// *************************************************************************** *
// *                                                                           *
// *                      Mentor Graphics Corporation                          *
// *                          All rights reserved                              *
// *                                                                           *
// *************************************************************************** *
// *                                                                           *
// * Description:         CANDB File                                           *
// * Generated at:        2025-06-23 15:14                                     *
// * System:              PP                                                   *
// * Variant:             DMH                                                  *
// * Network:             PTCANFD                                              *
// *                                                                           *
// *************************************************************************** *
// *                                                                           *
// *             THIS CONFIGURATION MIGHT CONTAIN SOME ERRORS                  *
// *              IF THE INPUT MODEL WAS NOT PROPERLY FORMED!                  *
// *                    Do Not Use this File directly!                         *
// *                                                                           *
// *************************************************************************** *
VERSION "PTCANFD"

NS_ :

BS_ :

BU_ :  BMS CCU PEU PICU TC TESTER VIU0

BO_ 287 ABM_State_VV01 : 20 VIU0
 SG_ ABM_CrashTyp : 127|5@0+ (1,0) [0|31] "" BMS,PEU,PICU,TC
 SG_ ABM_IMU_LateralAcceleration : 85|14@0+ (0.01,-49.05) [-49.05|114.78000000000002] "m/s2" TC
 SG_ ABM_IMU_LateralAccValid : 118|1@0+ (1,0) [0|1] "" TC
 SG_ ABM_IMU_LongAcceleration : 69|14@0+ (0.01,-49.05) [-49.05|114.78000000000002] "m/s2" TC
 SG_ ABM_IMU_LongAccelerationValid : 119|1@0+ (1,0) [0|1] "" TC
 SG_ ABM_IMU_Rollrate : 47|16@0+ (0.01,-300.0) [-300.0|355.35] "degree/s" TESTER
 SG_ ABM_IMU_RollrateSigVld : 33|1@0+ (1,0) [0|1] "" TESTER
 SG_ ABM_IMU_VertA : 31|14@0+ (0.01,-49.05) [-49.05|114.78000000000002] "m/s2" TESTER
 SG_ ABM_IMU_VertASigVld : 32|1@0+ (1,0) [0|1] "" TESTER
 SG_ ABM_IMU_YawRate : 103|16@0+ (0.01,-300.0) [-300.0|355.35] "degree/s" TESTER
 SG_ ABM_IMU_YawRateValid : 117|1@0+ (1,0) [0|1] "" TESTER
 SG_ ABM_IMU_YrsCalibStatus : 115|1@0+ (1,0) [0|1] "" TESTER
 SG_ ABM_State_Checksum : 7|16@0+ (1.0,0.0) [0.0|65535.0] "" PEU,PICU
 SG_ ABM_State_RollingCounter : 23|8@0+ (1.0,0.0) [0.0|255.0] "" PEU,PICU
 SG_ ABM_WarningLampStatus : 113|2@0+ (1,0) [0|3] "" PICU

BO_ 810 ADS_State : 32 VIU0
 SG_ ADS_CalSt : 110|5@0+ (1,0) [0|31] "" Vector_XXX
 SG_ ADS_FctSts : 37|1@0+ (1,0) [0|1] "" Vector_XXX
 SG_ ADS_FlowReq : 29|4@0+ (1,0) [0|15] "" PICU,TESTER
 SG_ ADS_ForcedHiBeamCtrl : 45|2@0+ (1,0) [0|3] "" Vector_XXX
 SG_ ADS_HVCtrlReq : 73|1@0+ (1,0) [0|1] "" Vector_XXX
 SG_ ADS_HzrdLampReq : 33|2@0+ (1,0) [0|3] "" Vector_XXX
 SG_ ADS_MdcCrtSts : 76|3@0+ (1,0) [0|7] "" Vector_XXX
 SG_ ADS_PwrOnOffReq : 79|3@0+ (1,0) [0|7] "" Vector_XXX
 SG_ ADS_RcwWarningReq : 47|2@0+ (1,0) [0|3] "" Vector_XXX
 SG_ ADS_RDAHzrdLampCtrl : 43|2@0+ (1,0) [0|3] "" Vector_XXX
 SG_ ADS_SilentCoolgMod : 199|2@0+ (1,0) [0|3] "" PICU,TESTER
 SG_ ADS_State_Checksum : 7|16@0+ (1.0,0.0) [0.0|65535.0] "" TESTER
 SG_ ADS_State_RollingCounter : 23|8@0+ (1.0,0.0) [0.0|255.0] "" TESTER
 SG_ ADS_SuspensionStatus : 24|3@0+ (1,0) [0|7] "" Vector_XXX
 SG_ ADS_ThmPostRun : 31|2@0+ (1,0) [0|3] "" PICU,TESTER
 SG_ ADS_TurnLampReq : 35|2@0+ (1,0) [0|3] "" Vector_XXX
 SG_ MDC_FuncReq_SentryModDetec : 118|1@0+ (1,0) [0|1] "" PICU
 SG_ MDC_FuncReq_SentryModWarn : 117|1@0+ (1,0) [0|1] "" Vector_XXX
 SG_ MDC_PrivacyModeSts : 127|2@0+ (1,0) [0|3] "" Vector_XXX

BO_ 1415 BMS_CellEquSt : 32 BMS
 SG_ BMS_BattEquilnSts : 0|1@0+ (1,0) [0|1] "" TESTER
 SG_ BMS_CellEquilnSts1 : 1|1@0+ (1,0) [0|1] "" TESTER
 SG_ BMS_CellEquilnSts10 : 10|1@0+ (1,0) [0|1] "" TESTER
 SG_ BMS_CellEquilnSts100 : 100|1@0+ (1,0) [0|1] "" TESTER
 SG_ BMS_CellEquilnSts101 : 101|1@0+ (1,0) [0|1] "" TESTER
 SG_ BMS_CellEquilnSts102 : 102|1@0+ (1,0) [0|1] "" TESTER
 SG_ BMS_CellEquilnSts103 : 103|1@0+ (1,0) [0|1] "" TESTER
 SG_ BMS_CellEquilnSts104 : 104|1@0+ (1,0) [0|1] "" TESTER
 SG_ BMS_CellEquilnSts105 : 105|1@0+ (1,0) [0|1] "" TESTER
 SG_ BMS_CellEquilnSts106 : 106|1@0+ (1,0) [0|1] "" TESTER
 SG_ BMS_CellEquilnSts107 : 107|1@0+ (1,0) [0|1] "" TESTER
 SG_ BMS_CellEquilnSts108 : 108|1@0+ (1,0) [0|1] "" TESTER
 SG_ BMS_CellEquilnSts109 : 109|1@0+ (1,0) [0|1] "" TESTER
 SG_ BMS_CellEquilnSts11 : 11|1@0+ (1,0) [0|1] "" TESTER
 SG_ BMS_CellEquilnSts110 : 110|1@0+ (1,0) [0|1] "" TESTER
 SG_ BMS_CellEquilnSts111 : 111|1@0+ (1,0) [0|1] "" TESTER
 SG_ BMS_CellEquilnSts112 : 112|1@0+ (1,0) [0|1] "" TESTER
 SG_ BMS_CellEquilnSts113 : 113|1@0+ (1,0) [0|1] "" TESTER
 SG_ BMS_CellEquilnSts114 : 114|1@0+ (1,0) [0|1] "" TESTER
 SG_ BMS_CellEquilnSts115 : 115|1@0+ (1,0) [0|1] "" TESTER
 SG_ BMS_CellEquilnSts116 : 116|1@0+ (1,0) [0|1] "" TESTER
 SG_ BMS_CellEquilnSts117 : 117|1@0+ (1,0) [0|1] "" TESTER
 SG_ BMS_CellEquilnSts118 : 118|1@0+ (1,0) [0|1] "" TESTER
 SG_ BMS_CellEquilnSts119 : 119|1@0+ (1,0) [0|1] "" TESTER
 SG_ BMS_CellEquilnSts12 : 12|1@0+ (1,0) [0|1] "" TESTER
 SG_ BMS_CellEquilnSts120 : 120|1@0+ (1,0) [0|1] "" TESTER
 SG_ BMS_CellEquilnSts121 : 121|1@0+ (1,0) [0|1] "" TESTER
 SG_ BMS_CellEquilnSts122 : 122|1@0+ (1,0) [0|1] "" TESTER
 SG_ BMS_CellEquilnSts123 : 123|1@0+ (1,0) [0|1] "" TESTER
 SG_ BMS_CellEquilnSts124 : 124|1@0+ (1,0) [0|1] "" TESTER
 SG_ BMS_CellEquilnSts125 : 125|1@0+ (1,0) [0|1] "" TESTER
 SG_ BMS_CellEquilnSts126 : 126|1@0+ (1,0) [0|1] "" TESTER
 SG_ BMS_CellEquilnSts127 : 127|1@0+ (1,0) [0|1] "" TESTER
 SG_ BMS_CellEquilnSts128 : 128|1@0+ (1,0) [0|1] "" TESTER
 SG_ BMS_CellEquilnSts129 : 129|1@0+ (1,0) [0|1] "" TESTER
 SG_ BMS_CellEquilnSts13 : 13|1@0+ (1,0) [0|1] "" TESTER
 SG_ BMS_CellEquilnSts130 : 130|1@0+ (1,0) [0|1] "" TESTER
 SG_ BMS_CellEquilnSts131 : 131|1@0+ (1,0) [0|1] "" TESTER
 SG_ BMS_CellEquilnSts132 : 132|1@0+ (1,0) [0|1] "" TESTER
 SG_ BMS_CellEquilnSts133 : 133|1@0+ (1,0) [0|1] "" TESTER
 SG_ BMS_CellEquilnSts134 : 134|1@0+ (1,0) [0|1] "" TESTER
 SG_ BMS_CellEquilnSts135 : 135|1@0+ (1,0) [0|1] "" TESTER
 SG_ BMS_CellEquilnSts136 : 136|1@0+ (1,0) [0|1] "" TESTER
 SG_ BMS_CellEquilnSts137 : 137|1@0+ (1,0) [0|1] "" TESTER
 SG_ BMS_CellEquilnSts138 : 138|1@0+ (1,0) [0|1] "" TESTER
 SG_ BMS_CellEquilnSts139 : 139|1@0+ (1,0) [0|1] "" TESTER
 SG_ BMS_CellEquilnSts14 : 14|1@0+ (1,0) [0|1] "" TESTER
 SG_ BMS_CellEquilnSts140 : 140|1@0+ (1,0) [0|1] "" TESTER
 SG_ BMS_CellEquilnSts141 : 141|1@0+ (1,0) [0|1] "" TESTER
 SG_ BMS_CellEquilnSts142 : 142|1@0+ (1,0) [0|1] "" TESTER
 SG_ BMS_CellEquilnSts143 : 143|1@0+ (1,0) [0|1] "" TESTER
 SG_ BMS_CellEquilnSts144 : 144|1@0+ (1,0) [0|1] "" TESTER
 SG_ BMS_CellEquilnSts145 : 145|1@0+ (1,0) [0|1] "" TESTER
 SG_ BMS_CellEquilnSts146 : 146|1@0+ (1,0) [0|1] "" TESTER
 SG_ BMS_CellEquilnSts147 : 147|1@0+ (1,0) [0|1] "" TESTER
 SG_ BMS_CellEquilnSts148 : 148|1@0+ (1,0) [0|1] "" TESTER
 SG_ BMS_CellEquilnSts149 : 149|1@0+ (1,0) [0|1] "" TESTER
 SG_ BMS_CellEquilnSts15 : 15|1@0+ (1,0) [0|1] "" TESTER
 SG_ BMS_CellEquilnSts150 : 150|1@0+ (1,0) [0|1] "" TESTER
 SG_ BMS_CellEquilnSts151 : 151|1@0+ (1,0) [0|1] "" TESTER
 SG_ BMS_CellEquilnSts152 : 152|1@0+ (1,0) [0|1] "" TESTER
 SG_ BMS_CellEquilnSts153 : 153|1@0+ (1,0) [0|1] "" TESTER
 SG_ BMS_CellEquilnSts154 : 154|1@0+ (1,0) [0|1] "" TESTER
 SG_ BMS_CellEquilnSts155 : 155|1@0+ (1,0) [0|1] "" TESTER
 SG_ BMS_CellEquilnSts156 : 156|1@0+ (1,0) [0|1] "" TESTER
 SG_ BMS_CellEquilnSts157 : 157|1@0+ (1,0) [0|1] "" TESTER
 SG_ BMS_CellEquilnSts158 : 158|1@0+ (1,0) [0|1] "" TESTER
 SG_ BMS_CellEquilnSts159 : 159|1@0+ (1,0) [0|1] "" TESTER
 SG_ BMS_CellEquilnSts16 : 16|1@0+ (1,0) [0|1] "" TESTER
 SG_ BMS_CellEquilnSts160 : 160|1@0+ (1,0) [0|1] "" TESTER
 SG_ BMS_CellEquilnSts161 : 161|1@0+ (1,0) [0|1] "" TESTER
 SG_ BMS_CellEquilnSts162 : 162|1@0+ (1,0) [0|1] "" TESTER
 SG_ BMS_CellEquilnSts163 : 163|1@0+ (1,0) [0|1] "" TESTER
 SG_ BMS_CellEquilnSts164 : 164|1@0+ (1,0) [0|1] "" TESTER
 SG_ BMS_CellEquilnSts165 : 165|1@0+ (1,0) [0|1] "" TESTER
 SG_ BMS_CellEquilnSts166 : 166|1@0+ (1,0) [0|1] "" TESTER
 SG_ BMS_CellEquilnSts167 : 167|1@0+ (1,0) [0|1] "" TESTER
 SG_ BMS_CellEquilnSts168 : 168|1@0+ (1,0) [0|1] "" TESTER
 SG_ BMS_CellEquilnSts169 : 169|1@0+ (1,0) [0|1] "" TESTER
 SG_ BMS_CellEquilnSts17 : 17|1@0+ (1,0) [0|1] "" TESTER
 SG_ BMS_CellEquilnSts170 : 170|1@0+ (1,0) [0|1] "" TESTER
 SG_ BMS_CellEquilnSts171 : 171|1@0+ (1,0) [0|1] "" TESTER
 SG_ BMS_CellEquilnSts172 : 172|1@0+ (1,0) [0|1] "" TESTER
 SG_ BMS_CellEquilnSts173 : 173|1@0+ (1,0) [0|1] "" TESTER
 SG_ BMS_CellEquilnSts174 : 174|1@0+ (1,0) [0|1] "" TESTER
 SG_ BMS_CellEquilnSts175 : 175|1@0+ (1,0) [0|1] "" TESTER
 SG_ BMS_CellEquilnSts176 : 176|1@0+ (1,0) [0|1] "" TESTER
 SG_ BMS_CellEquilnSts177 : 177|1@0+ (1,0) [0|1] "" TESTER
 SG_ BMS_CellEquilnSts178 : 178|1@0+ (1,0) [0|1] "" TESTER
 SG_ BMS_CellEquilnSts179 : 179|1@0+ (1,0) [0|1] "" TESTER
 SG_ BMS_CellEquilnSts18 : 18|1@0+ (1,0) [0|1] "" TESTER
 SG_ BMS_CellEquilnSts180 : 180|1@0+ (1,0) [0|1] "" TESTER
 SG_ BMS_CellEquilnSts181 : 181|1@0+ (1,0) [0|1] "" TESTER
 SG_ BMS_CellEquilnSts182 : 182|1@0+ (1,0) [0|1] "" TESTER
 SG_ BMS_CellEquilnSts183 : 183|1@0+ (1,0) [0|1] "" TESTER
 SG_ BMS_CellEquilnSts184 : 184|1@0+ (1,0) [0|1] "" TESTER
 SG_ BMS_CellEquilnSts185 : 185|1@0+ (1,0) [0|1] "" TESTER
 SG_ BMS_CellEquilnSts186 : 186|1@0+ (1,0) [0|1] "" TESTER
 SG_ BMS_CellEquilnSts187 : 187|1@0+ (1,0) [0|1] "" TESTER
 SG_ BMS_CellEquilnSts188 : 188|1@0+ (1,0) [0|1] "" TESTER
 SG_ BMS_CellEquilnSts189 : 189|1@0+ (1,0) [0|1] "" TESTER
 SG_ BMS_CellEquilnSts19 : 19|1@0+ (1,0) [0|1] "" TESTER
 SG_ BMS_CellEquilnSts190 : 190|1@0+ (1,0) [0|1] "" TESTER
 SG_ BMS_CellEquilnSts191 : 191|1@0+ (1,0) [0|1] "" TESTER
 SG_ BMS_CellEquilnSts192 : 192|1@0+ (1,0) [0|1] "" TESTER
 SG_ BMS_CellEquilnSts2 : 2|1@0+ (1,0) [0|1] "" TESTER
 SG_ BMS_CellEquilnSts20 : 20|1@0+ (1,0) [0|1] "" TESTER
 SG_ BMS_CellEquilnSts21 : 21|1@0+ (1,0) [0|1] "" TESTER
 SG_ BMS_CellEquilnSts22 : 22|1@0+ (1,0) [0|1] "" TESTER
 SG_ BMS_CellEquilnSts23 : 23|1@0+ (1,0) [0|1] "" TESTER
 SG_ BMS_CellEquilnSts24 : 24|1@0+ (1,0) [0|1] "" TESTER
 SG_ BMS_CellEquilnSts25 : 25|1@0+ (1,0) [0|1] "" TESTER
 SG_ BMS_CellEquilnSts26 : 26|1@0+ (1,0) [0|1] "" TESTER
 SG_ BMS_CellEquilnSts27 : 27|1@0+ (1,0) [0|1] "" TESTER
 SG_ BMS_CellEquilnSts28 : 28|1@0+ (1,0) [0|1] "" TESTER
 SG_ BMS_CellEquilnSts29 : 29|1@0+ (1,0) [0|1] "" TESTER
 SG_ BMS_CellEquilnSts3 : 3|1@0+ (1,0) [0|1] "" TESTER
 SG_ BMS_CellEquilnSts30 : 30|1@0+ (1,0) [0|1] "" TESTER
 SG_ BMS_CellEquilnSts31 : 31|1@0+ (1,0) [0|1] "" TESTER
 SG_ BMS_CellEquilnSts32 : 32|1@0+ (1,0) [0|1] "" TESTER
 SG_ BMS_CellEquilnSts33 : 33|1@0+ (1,0) [0|1] "" TESTER
 SG_ BMS_CellEquilnSts34 : 34|1@0+ (1,0) [0|1] "" TESTER
 SG_ BMS_CellEquilnSts35 : 35|1@0+ (1,0) [0|1] "" TESTER
 SG_ BMS_CellEquilnSts36 : 36|1@0+ (1,0) [0|1] "" TESTER
 SG_ BMS_CellEquilnSts37 : 37|1@0+ (1,0) [0|1] "" TESTER
 SG_ BMS_CellEquilnSts38 : 38|1@0+ (1,0) [0|1] "" TESTER
 SG_ BMS_CellEquilnSts39 : 39|1@0+ (1,0) [0|1] "" TESTER
 SG_ BMS_CellEquilnSts4 : 4|1@0+ (1,0) [0|1] "" TESTER
 SG_ BMS_CellEquilnSts40 : 40|1@0+ (1,0) [0|1] "" TESTER
 SG_ BMS_CellEquilnSts41 : 41|1@0+ (1,0) [0|1] "" TESTER
 SG_ BMS_CellEquilnSts42 : 42|1@0+ (1,0) [0|1] "" TESTER
 SG_ BMS_CellEquilnSts43 : 43|1@0+ (1,0) [0|1] "" TESTER
 SG_ BMS_CellEquilnSts44 : 44|1@0+ (1,0) [0|1] "" TESTER
 SG_ BMS_CellEquilnSts45 : 45|1@0+ (1,0) [0|1] "" TESTER
 SG_ BMS_CellEquilnSts46 : 46|1@0+ (1,0) [0|1] "" TESTER
 SG_ BMS_CellEquilnSts47 : 47|1@0+ (1,0) [0|1] "" TESTER
 SG_ BMS_CellEquilnSts48 : 48|1@0+ (1,0) [0|1] "" TESTER
 SG_ BMS_CellEquilnSts49 : 49|1@0+ (1,0) [0|1] "" TESTER
 SG_ BMS_CellEquilnSts5 : 5|1@0+ (1,0) [0|1] "" TESTER
 SG_ BMS_CellEquilnSts50 : 50|1@0+ (1,0) [0|1] "" TESTER
 SG_ BMS_CellEquilnSts51 : 51|1@0+ (1,0) [0|1] "" TESTER
 SG_ BMS_CellEquilnSts52 : 52|1@0+ (1,0) [0|1] "" TESTER
 SG_ BMS_CellEquilnSts53 : 53|1@0+ (1,0) [0|1] "" TESTER
 SG_ BMS_CellEquilnSts54 : 54|1@0+ (1,0) [0|1] "" TESTER
 SG_ BMS_CellEquilnSts55 : 55|1@0+ (1,0) [0|1] "" TESTER
 SG_ BMS_CellEquilnSts56 : 56|1@0+ (1,0) [0|1] "" TESTER
 SG_ BMS_CellEquilnSts57 : 57|1@0+ (1,0) [0|1] "" TESTER
 SG_ BMS_CellEquilnSts58 : 58|1@0+ (1,0) [0|1] "" TESTER
 SG_ BMS_CellEquilnSts59 : 59|1@0+ (1,0) [0|1] "" TESTER
 SG_ BMS_CellEquilnSts6 : 6|1@0+ (1,0) [0|1] "" TESTER
 SG_ BMS_CellEquilnSts60 : 60|1@0+ (1,0) [0|1] "" TESTER
 SG_ BMS_CellEquilnSts61 : 61|1@0+ (1,0) [0|1] "" TESTER
 SG_ BMS_CellEquilnSts62 : 62|1@0+ (1,0) [0|1] "" TESTER
 SG_ BMS_CellEquilnSts63 : 63|1@0+ (1,0) [0|1] "" TESTER
 SG_ BMS_CellEquilnSts64 : 64|1@0+ (1,0) [0|1] "" TESTER
 SG_ BMS_CellEquilnSts65 : 65|1@0+ (1,0) [0|1] "" TESTER
 SG_ BMS_CellEquilnSts66 : 66|1@0+ (1,0) [0|1] "" TESTER
 SG_ BMS_CellEquilnSts67 : 67|1@0+ (1,0) [0|1] "" TESTER
 SG_ BMS_CellEquilnSts68 : 68|1@0+ (1,0) [0|1] "" TESTER
 SG_ BMS_CellEquilnSts69 : 69|1@0+ (1,0) [0|1] "" TESTER
 SG_ BMS_CellEquilnSts7 : 7|1@0+ (1,0) [0|1] "" TESTER
 SG_ BMS_CellEquilnSts70 : 70|1@0+ (1,0) [0|1] "" TESTER
 SG_ BMS_CellEquilnSts71 : 71|1@0+ (1,0) [0|1] "" TESTER
 SG_ BMS_CellEquilnSts72 : 72|1@0+ (1,0) [0|1] "" TESTER
 SG_ BMS_CellEquilnSts73 : 73|1@0+ (1,0) [0|1] "" TESTER
 SG_ BMS_CellEquilnSts74 : 74|1@0+ (1,0) [0|1] "" TESTER
 SG_ BMS_CellEquilnSts75 : 75|1@0+ (1,0) [0|1] "" TESTER
 SG_ BMS_CellEquilnSts76 : 76|1@0+ (1,0) [0|1] "" TESTER
 SG_ BMS_CellEquilnSts77 : 77|1@0+ (1,0) [0|1] "" TESTER
 SG_ BMS_CellEquilnSts78 : 78|1@0+ (1,0) [0|1] "" TESTER
 SG_ BMS_CellEquilnSts79 : 79|1@0+ (1,0) [0|1] "" TESTER
 SG_ BMS_CellEquilnSts8 : 8|1@0+ (1,0) [0|1] "" TESTER
 SG_ BMS_CellEquilnSts80 : 80|1@0+ (1,0) [0|1] "" TESTER
 SG_ BMS_CellEquilnSts81 : 81|1@0+ (1,0) [0|1] "" TESTER
 SG_ BMS_CellEquilnSts82 : 82|1@0+ (1,0) [0|1] "" TESTER
 SG_ BMS_CellEquilnSts83 : 83|1@0+ (1,0) [0|1] "" TESTER
 SG_ BMS_CellEquilnSts84 : 84|1@0+ (1,0) [0|1] "" TESTER
 SG_ BMS_CellEquilnSts85 : 85|1@0+ (1,0) [0|1] "" TESTER
 SG_ BMS_CellEquilnSts86 : 86|1@0+ (1,0) [0|1] "" TESTER
 SG_ BMS_CellEquilnSts87 : 87|1@0+ (1,0) [0|1] "" TESTER
 SG_ BMS_CellEquilnSts88 : 88|1@0+ (1,0) [0|1] "" TESTER
 SG_ BMS_CellEquilnSts89 : 89|1@0+ (1,0) [0|1] "" TESTER
 SG_ BMS_CellEquilnSts9 : 9|1@0+ (1,0) [0|1] "" TESTER
 SG_ BMS_CellEquilnSts90 : 90|1@0+ (1,0) [0|1] "" TESTER
 SG_ BMS_CellEquilnSts91 : 91|1@0+ (1,0) [0|1] "" TESTER
 SG_ BMS_CellEquilnSts92 : 92|1@0+ (1,0) [0|1] "" TESTER
 SG_ BMS_CellEquilnSts93 : 93|1@0+ (1,0) [0|1] "" TESTER
 SG_ BMS_CellEquilnSts94 : 94|1@0+ (1,0) [0|1] "" TESTER
 SG_ BMS_CellEquilnSts95 : 95|1@0+ (1,0) [0|1] "" TESTER
 SG_ BMS_CellEquilnSts96 : 96|1@0+ (1,0) [0|1] "" TESTER
 SG_ BMS_CellEquilnSts97 : 97|1@0+ (1,0) [0|1] "" TESTER
 SG_ BMS_CellEquilnSts98 : 98|1@0+ (1,0) [0|1] "" TESTER
 SG_ BMS_CellEquilnSts99 : 99|1@0+ (1,0) [0|1] "" TESTER
 SG_ BMS_CellEquStSync : 251|4@0+ (1.0,0.0) [0.0|14.0] "" TESTER
 SG_ BMS_EquilnFltCellIdx : 247|8@0+ (1.0,0.0) [0.0|255.0] "" TESTER

BO_ 389 BMS_ChargeInfo : 32 BMS
 SG_ BMS_ACChrgSt : 91|4@0+ (1,0) [0|15] "" PICU,VIU0
 SG_ BMS_ACOutDischrgSt : 94|3@0+ (1,0) [0|7] "" PICU,VIU0
 SG_ BMS_ActvHvOffReq : 127|8@0+ (1.0,0.0) [0.0|255.0] "" VIU0
 SG_ BMS_ActvHvOnReq : 71|8@0+ (1,0) [0|255] "" CCU,PICU,TC,VIU0
 SG_ BMS_BattChrgNeeded : 87|1@0+ (1,0) [0|1] "" VIU0
 SG_ BMS_Cc2SngR : 100|13@0+ (1.0,0.0) [0.0|8191.0] "Ω" TESTER
 SG_ BMS_ChargeInfo_Checksum : 7|16@0+ (1.0,0.0) [0.0|65535.0] "" CCU,VIU0
 SG_ BMS_ChargeInfo_Counter : 23|8@0+ (1.0,0.0) [0.0|255.0] "" CCU,VIU0
 SG_ BMS_ChrgASigSt : 27|1@0+ (1,0) [0|1] "" TESTER
 SG_ BMS_ChrgASigVolt : 39|9@0+ (0.1,0.0) [0.0|36.0] "V" TESTER
 SG_ BMS_ChrgEndNum : 119|8@0+ (1.0,0.0) [0.0|255.0] "" VIU0
 SG_ BMS_ChrgForm : 79|4@0+ (1,0) [0|15] "" TESTER
 SG_ BMS_ChrgLockReq : 245|2@0+ (1,0) [0|3] "" VIU0
 SG_ BMS_ChrgRemainTime : 52|13@0+ (1.0,0.0) [0.0|8191.0] "min" VIU0
 SG_ BMS_ChrgTiEstimn : 220|13@0+ (1.0,0.0) [0.0|8189.0] "min" VIU0
 SG_ BMS_ChrgTrgtSOC : 46|7@0+ (1.0,0.0) [0.0|100.0] "%" VIU0
 SG_ BMS_DCChrgConnectSt : 26|3@0+ (1,0) [0|7] "" CCU,PICU,TC,VIU0
 SG_ BMS_DCChrgSt : 83|4@0+ (1,0) [0|15] "" PICU,VIU0
 SG_ BMS_DCOutDischrgSt : 86|3@0+ (1,0) [0|7] "" TESTER,VIU0
 SG_ BMS_DCPileInsuTestVoltMax : 215|10@0+ (1.0,0.0) [0.0|1000.0] "V" VIU0
 SG_ BMS_DeratingCoeff : 239|10@0+ (0.1,0.0) [0.0|100.0] "%" TESTER
 SG_ BMS_DrtngChg : 181|3@0+ (1,0) [0|7] "" VIU0
 SG_ BMS_FCNegRelaySt : 31|2@0+ (1,0) [0|3] "" VIU0
 SG_ BMS_FCPosRelaySt : 29|2@0+ (1,0) [0|3] "" VIU0
 SG_ BMS_HVONReq : 54|2@0+ (1,0) [0|3] "" PICU,VIU0
 SG_ BMS_LinkEnergizeSt : 103|3@0+ (1,0) [0|7] "" VIU0
 SG_ BMS_OBCCurrtReq : 155|12@0+ (0.1,0.0) [0.0|409.5] "A" CCU,VIU0
 SG_ BMS_OBCInvACVoltReq : 176|9@0+ (1.0,0.0) [0.0|511.0] "V" CCU
 SG_ BMS_OBCInvMaxPermPwr : 175|10@0+ (0.01,0.0) [0.0|10.23] "kw" CCU
 SG_ BMS_OBCVoltReq : 151|10@0+ (1.0,0.0) [0.0|1000.0] "V" CCU,VIU0
 SG_ BMS_OBCWorkModReq : 142|3@0+ (1,0) [0|7] "" CCU
 SG_ BMS_PilePwrSt : 139|3@0+ (1,0) [0|7] "" VIU0
 SG_ BMS_S1Req : 156|1@0+ (1,0) [0|1] "" TESTER
 SG_ BMS_S2SwtCtrl : 243|2@0+ (1,0) [0|3] "" VIU0
 SG_ BMS_S4Req : 157|1@0+ (1,0) [0|1] "" TESTER

BO_ 795 BMS_DFX_1 : 32 BMS
 SG_ BMS_AFEPreFail : 213|1@0+ (1,0) [0|1] "" VIU0
 SG_ BMS_AFEPreFailNum : 212|5@0+ (1.0,0.0) [0.0|31.0] "" VIU0
 SG_ BMS_ChrgCurrtLkUp : 167|14@0+ (0.1,-1000.0) [-1000.0|0.0] "A" VIU0
 SG_ BMS_CrashPWMDuty : 190|7@0+ (1.0,0.0) [0.0|100.0] "%" VIU0
 SG_ BMS_EquPreFail : 221|1@0+ (1,0) [0|1] "" VIU0
 SG_ BMS_EquPreFailNum : 220|5@0+ (1.0,0.0) [0.0|31.0] "" VIU0
 SG_ BMS_HighTempFaultNTCIdx : 237|6@0+ (1.0,0.0) [0.0|61.0] "" VIU0
 SG_ BMS_HighTempFaultNTCNum : 229|6@0+ (1.0,0.0) [0.0|61.0] "" VIU0
 SG_ BMS_HVILFCVh : 68|13@0+ (1.0,0.0) [0.0|5000.0] "mV" VIU0
 SG_ BMS_HVILFCVl : 84|13@0+ (1.0,0.0) [0.0|5000.0] "mV" VIU0
 SG_ BMS_HVILPWRTrainFVh : 100|13@0+ (1.0,0.0) [0.0|5000.0] "mV" VIU0
 SG_ BMS_HVILPWRTrainFVl : 116|13@0+ (1.0,0.0) [0.0|5000.0] "mV" VIU0
 SG_ BMS_HVILPWRTrainRVh : 132|13@0+ (1.0,0.0) [0.0|5000.0] "mV" VIU0
 SG_ BMS_HVILPWRTrainRVl : 148|13@0+ (1.0,0.0) [0.0|5000.0] "mV" VIU0
 SG_ BMS_InsulationNeg : 23|16@0+ (1.0,0.0) [0.0|60000.0] " kΩ" VIU0
 SG_ BMS_InsulationPos : 7|16@0+ (1.0,0.0) [0.0|60000.0] " kΩ" VIU0
 SG_ BMS_InsulationVoltNeg : 52|13@0+ (1.0,0.0) [0.0|5000.0] "V" VIU0
 SG_ BMS_InsulationVoltPos : 36|13@0+ (1.0,0.0) [0.0|5000.0] "V" VIU0
 SG_ BMS_LowTempFaultNTCIdx : 253|6@0+ (1.0,0.0) [0.0|61.0] "" VIU0
 SG_ BMS_LowTempFaultNTCNum : 245|6@0+ (1.0,0.0) [0.0|61.0] "" VIU0
 SG_ BMS_PreChgScssTime : 169|10@0+ (1.0,0.0) [0.0|1000.0] "ms" VIU0
 SG_ BMS_TSmplngLnPreFail : 206|1@0+ (1,0) [0|1] "" VIU0
 SG_ BMS_TSmplngLnPreFailNum : 205|6@0+ (1.0,0.0) [0.0|63.0] "" VIU0
 SG_ BMS_VSmplngLnPreFail : 207|1@0+ (1,0) [0|1] "" VIU0
 SG_ BMS_VSmplngLnPreFailNum : 199|8@0+ (1.0,0.0) [0.0|255.0] "" VIU0

BO_ 797 BMS_DFX_2 : 32 BMS
 SG_ BMS_CellMaxVolt : 20|13@0+ (1.0,0.0) [0.0|5000.0] "mV" VIU0
 SG_ BMS_CellMinVolt : 36|13@0+ (1.0,0.0) [0.0|5000.0] "mV" VIU0
 SG_ BMS_CellVoltSum : 53|14@0+ (0.1,0.0) [0.0|1000.0] "" VIU0
 SG_ BMS_MaxVoltCellNum : 7|8@0+ (1.0,0.0) [0.0|255.0] "" VIU0
 SG_ BMS_MinVoltCellNum : 15|8@0+ (1.0,0.0) [0.0|255.0] "" VIU0
 SG_ BMS_ModuleVolt1 : 71|10@0+ (0.1,0.0) [0.0|80.0] "V" VIU0
 SG_ BMS_ModuleVolt10 : 169|10@0+ (0.1,0.0) [0.0|80.0] "V" VIU0
 SG_ BMS_ModuleVolt11 : 191|10@0+ (0.1,0.0) [0.0|80.0] "V" VIU0
 SG_ BMS_ModuleVolt12 : 193|10@0+ (0.1,0.0) [0.0|80.0] "V" VIU0
 SG_ BMS_ModuleVolt13 : 215|10@0+ (0.1,0.0) [0.0|80.0] "V" VIU0
 SG_ BMS_ModuleVolt14 : 217|10@0+ (0.1,0.0) [0.0|80.0] "V" VIU0
 SG_ BMS_ModuleVolt2 : 73|10@0+ (0.1,0.0) [0.0|80.0] "V" VIU0
 SG_ BMS_ModuleVolt3 : 95|10@0+ (0.1,0.0) [0.0|80.0] "V" VIU0
 SG_ BMS_ModuleVolt4 : 97|10@0+ (0.1,0.0) [0.0|80.0] "V" VIU0
 SG_ BMS_ModuleVolt5 : 119|10@0+ (0.1,0.0) [0.0|80.0] "V" VIU0
 SG_ BMS_ModuleVolt6 : 121|10@0+ (0.1,0.0) [0.0|80.0] "V" VIU0
 SG_ BMS_ModuleVolt7 : 143|10@0+ (0.1,0.0) [0.0|80.0] "V" VIU0
 SG_ BMS_ModuleVolt8 : 145|10@0+ (0.1,0.0) [0.0|80.0] "V" VIU0
 SG_ BMS_ModuleVolt9 : 167|10@0+ (0.1,0.0) [0.0|80.0] "V" VIU0
 SG_ BMS_PrimaryCurrtSnsrTemp : 239|8@0+ (1.0,-50.0) [-50.0|205.0] "℃" TESTER

BO_ 1299 BMS_DFX_3 : 32 BMS
 SG_ BMS_EquTemp1 : 7|8@0+ (1.0,-40.0) [-40.0|125.0] "℃" VIU0
 SG_ BMS_EquTemp10 : 79|8@0+ (1.0,-40.0) [-40.0|125.0] "℃" VIU0
 SG_ BMS_EquTemp11 : 87|8@0+ (1.0,-40.0) [-40.0|125.0] "℃" VIU0
 SG_ BMS_EquTemp12 : 95|8@0+ (1.0,-40.0) [-40.0|125.0] "℃" VIU0
 SG_ BMS_EquTemp13 : 103|8@0+ (1.0,-40.0) [-40.0|125.0] "℃" VIU0
 SG_ BMS_EquTemp14 : 111|8@0+ (1.0,-40.0) [-40.0|125.0] "℃" VIU0
 SG_ BMS_EquTemp2 : 15|8@0+ (1.0,-40.0) [-40.0|125.0] "℃" VIU0
 SG_ BMS_EquTemp3 : 23|8@0+ (1.0,-40.0) [-40.0|125.0] "℃" VIU0
 SG_ BMS_EquTemp4 : 31|8@0+ (1.0,-40.0) [-40.0|125.0] "℃" VIU0
 SG_ BMS_EquTemp5 : 39|8@0+ (1.0,-40.0) [-40.0|125.0] "℃" VIU0
 SG_ BMS_EquTemp6 : 47|8@0+ (1.0,-40.0) [-40.0|125.0] "℃" VIU0
 SG_ BMS_EquTemp7 : 55|8@0+ (1.0,-40.0) [-40.0|125.0] "℃" VIU0
 SG_ BMS_EquTemp8 : 63|8@0+ (1.0,-40.0) [-40.0|125.0] "℃" VIU0
 SG_ BMS_EquTemp9 : 71|8@0+ (1.0,-40.0) [-40.0|125.0] "℃" VIU0
 SG_ BMS_MainNegBigLoadOpenCnt : 247|8@0+ (1.0,0.0) [0.0|255.0] "" VIU0
 SG_ BMS_MainNegLowLoadOpenCnt : 209|18@0+ (1.0,0.0) [0.0|262143.0] "" VIU0
 SG_ BMS_MainNegMidLoadOpenCnt : 239|8@0+ (1.0,0.0) [0.0|255.0] "" VIU0
 SG_ BMS_MainNegOpenCnt : 199|18@0+ (1.0,0.0) [0.0|262143.0] "" VIU0
 SG_ BMS_MainNegSuperLoadOpenCnt : 255|8@0+ (1.0,0.0) [0.0|255.0] "" VIU0
 SG_ BMS_MainPosBigLoadOpenCnt : 183|8@0+ (1.0,0.0) [0.0|255.0] "" VIU0
 SG_ BMS_MainPosLowLoadOpenCnt : 145|18@0+ (1.0,0.0) [0.0|262143.0] "" VIU0
 SG_ BMS_MainPosMidLoadOpenCnt : 175|8@0+ (1.0,0.0) [0.0|255.0] "" VIU0
 SG_ BMS_MainPosOpenCnt : 135|18@0+ (1.0,0.0) [0.0|262143.0] "" VIU0
 SG_ BMS_MainPosSuperLoadOpenCnt : 191|8@0+ (1.0,0.0) [0.0|255.0] "" VIU0

BO_ 786 BMS_ErrInfo : 32 BMS
 SG_ BMS_AirPressure : 87|16@0+ (0.1,0.0) [0.0|6553.3] "kPa" TESTER
 SG_ BMS_AirPressureRate : 103|8@0+ (0.1,0.0) [0.0|25.3] "kPa/s" TESTER
 SG_ BMS_BattSocUnderLamp : 29|1@0+ (1,0) [0|1] "" TESTER
 SG_ BMS_BattTempRate : 111|8@0+ (1.0,0.0) [0.0|253.0] "℃/3S" TESTER
 SG_ BMS_BattTLowLamp1 : 37|1@0+ (1,0) [0|1] "" TESTER
 SG_ BMS_BattTLowLamp2 : 38|1@0+ (1,0) [0|1] "" VIU0
 SG_ BMS_BattTOverLamp : 30|1@0+ (1,0) [0|1] "" PICU
 SG_ BMS_CalDataVers : 113|10@0+ (1.0,0.0) [0.0|1023.0] "" TESTER
 SG_ BMS_HVPwrDwnRsn : 119|6@0+ (1.0,0.0) [0.0|63.0] "" TESTER
 SG_ BMS_HVPwrOnFailRsn : 157|6@0+ (1.0,0.0) [0.0|63.0] "" TESTER
 SG_ BMS_InsulationProhibitRsn : 175|5@0+ (1.0,0.0) [0.0|31.0] "" TESTER
 SG_ BMS_MIL_Request : 39|1@0+ (1,0) [0|1] "" PICU,VIU0
 SG_ BMS_PackSOHActual : 151|10@0+ (0.1,0.0) [0.0|100.0] "%" TESTER
 SG_ BMS_PwrBattErrLamp : 31|1@0+ (1,0) [0|1] "" TESTER
 SG_ BMS_ResetRsn : 167|8@0+ (1.0,0.0) [0.0|255.0] "" TESTER
 SG_ BMS_SOCCalAlarm : 35|2@0+ (1,0) [0|3] "" VIU0
 SG_ BMS_TRWarnRsn : 28|5@0+ (1.0,0.0) [0.0|31.0] "" TESTER

BO_ 461 BMS_FastChgErr : 8 BMS
 SG_ BST_AchievedCellVoltage : 5|2@0+ (1,0) [0|3] "" TESTER
 SG_ BST_AchievedPackVoltage : 3|2@0+ (1,0) [0|3] "" TESTER
 SG_ BST_AchievedSOC : 1|2@0+ (1,0) [0|3] "" TESTER
 SG_ BST_BatteryTempHigh : 17|2@0+ (1,0) [0|3] "" TESTER
 SG_ BST_BMSComponentsFault : 13|2@0+ (1,0) [0|3] "" TESTER
 SG_ BST_ChargeConnetorFault : 15|2@0+ (1,0) [0|3] "" TESTER
 SG_ BST_ChargeTeminated : 7|2@0+ (1,0) [0|3] "" TESTER
 SG_ BST_HVContactorFault : 19|2@0+ (1,0) [0|3] "" TESTER
 SG_ BST_InsulationFault : 9|2@0+ (1,0) [0|3] "" TESTER
 SG_ BST_OtherFault : 23|2@0+ (1,0) [0|3] "" TESTER
 SG_ BST_OutputConectorTempHigh : 11|2@0+ (1,0) [0|3] "" TESTER
 SG_ BST_OverCurrentError : 25|2@0+ (1,0) [0|3] "" TESTER
 SG_ BST_Point2VoltageDetectFault : 21|2@0+ (1,0) [0|3] "" TESTER
 SG_ BST_VoltageError : 27|2@0+ (1,0) [0|3] "" TESTER
 SG_ CST_AchievedCondition : 33|2@0+ (1,0) [0|3] "" TESTER
 SG_ CST_BMSAbort : 39|2@0+ (1,0) [0|3] "" TESTER
 SG_ CST_ChargeConnetorFault : 43|2@0+ (1,0) [0|3] "" TESTER
 SG_ CST_ChargeInnerTempFault : 45|2@0+ (1,0) [0|3] "" TESTER
 SG_ CST_ChargeStopFault : 49|2@0+ (1,0) [0|3] "" TESTER
 SG_ CST_ChargeTempHighFault : 41|2@0+ (1,0) [0|3] "" TESTER
 SG_ CST_CurrentMismathError : 53|2@0+ (1,0) [0|3] "" TESTER
 SG_ CST_EnergyTransmitFault : 47|2@0+ (1,0) [0|3] "" TESTER
 SG_ CST_FaultAbort : 37|2@0+ (1,0) [0|3] "" TESTER
 SG_ CST_ManualAbort : 35|2@0+ (1,0) [0|3] "" TESTER
 SG_ CST_OtherFault : 51|2@0+ (1,0) [0|3] "" TESTER
 SG_ CST_VolateError : 55|2@0+ (1,0) [0|3] "" TESTER

BO_ 862 BMS_FastChgInfo : 48 BMS
 SG_ BCL_ChareMode : 263|8@0+ (1,0) [0|255] "" TESTER
 SG_ BCL_CurrentRequire : 247|16@0+ (0.1,-400.0) [-400.0|6153.5] "A" VIU0
 SG_ BCL_VoltageRequire : 231|16@0+ (0.1,0.0) [0.0|6553.5] "V" VIU0
 SG_ BEM_CCSTimeout : 329|2@0+ (1,0) [0|3] "" TESTER
 SG_ BEM_CRMTimeout00 : 321|2@0+ (1,0) [0|3] "" TESTER
 SG_ BEM_CRMTimeoutAA : 323|2@0+ (1,0) [0|3] "" TESTER
 SG_ BEM_CROTimeout : 327|2@0+ (1,0) [0|3] "" TESTER
 SG_ BEM_CSDTimeout : 333|2@0+ (1,0) [0|3] "" TESTER
 SG_ BEM_CSTTimeout : 331|2@0+ (1,0) [0|3] "" TESTER
 SG_ BEM_CTS_CMLTimeout : 325|2@0+ (1,0) [0|3] "" TESTER
 SG_ BEM_Other : 335|2@0+ (1,0) [0|3] "" TESTER
 SG_ BRM_BatteryChargeTimes : 127|24@0+ (1.0,0.0) [0.0|16777215.0] "" TESTER
 SG_ BRM_BatteryManufacture : 95|32@0+ (1.0,0.0) [0.0|4294967295.0] "" TESTER
 SG_ BRO_BMSChargeReady : 215|8@0+ (1,0) [0|255] "" TESTER
 SG_ CCS_ChargeAllowed : 313|2@0+ (1,0) [0|3] "" TESTER
 SG_ CCS_OutputCurent : 287|16@0+ (0.1,-400.0) [-400.0|6153.5] "A" TC,VIU0
 SG_ CCS_OutputVoltage : 271|16@0+ (0.1,0.0) [0.0|6553.5] "V" TC,VIU0
 SG_ CCS_TotalChargeTime : 303|16@0+ (1.0,0.0) [0.0|600.0] "min" TESTER
 SG_ CEM_BCLTimeout : 345|2@0+ (1,0) [0|3] "" TESTER
 SG_ CEM_BCPTimeout : 339|2@0+ (1,0) [0|3] "" TESTER
 SG_ CEM_BCSTimeout : 343|2@0+ (1,0) [0|3] "" TESTER
 SG_ CEM_BRMTimeout : 337|2@0+ (1,0) [0|3] "" TESTER
 SG_ CEM_BROTimeout : 341|2@0+ (1,0) [0|3] "" TESTER
 SG_ CEM_BSDTimeout : 349|2@0+ (1,0) [0|3] "" TESTER
 SG_ CEM_BSTTimeout : 347|2@0+ (1,0) [0|3] "" TESTER
 SG_ CEM_Other : 351|2@0+ (1,0) [0|3] "" TESTER
 SG_ CHM_ComVersion : 7|24@0+ (1.0,0.0) [0.0|16777215.0] "" TESTER
 SG_ CML_OutputCurentMax : 183|16@0+ (0.1,-400.0) [-400.0|6153.5] "A" TC,VIU0
 SG_ CML_OutputCurentMin : 199|16@0+ (0.1,-400.0) [-400.0|6153.5] "A" TESTER
 SG_ CML_OutputVoltageMax : 151|16@0+ (0.1,0.0) [0.0|6553.5] "V" TESTER
 SG_ CML_OutputVoltageMin : 167|16@0+ (0.1,0.0) [0.0|6553.5] "V" TESTER
 SG_ CRM_ChargeNo : 39|32@0+ (1.0,0.0) [0.0|4294967295.0] "" TESTER
 SG_ CRM_RecongnitionResult : 31|8@0+ (1.0,0.0) [0.0|255.0] "" TESTER
 SG_ CRM_RegionCode : 71|24@0+ (1.0,0.0) [0.0|16777215.0] "" TESTER
 SG_ CRO_ChargeReady : 223|8@0+ (1.0,0.0) [0.0|255.0] "" TESTER
 SG_ CSD_TotalChrgEnergy : 359|16@0+ (0.1,0.0) [0.0|1000.0] "kWh" TESTER

BO_ 1303 BMS_Fault : 32 BMS
 SG_ BMS_FaultNum1 : 23|12@0+ (1.0,0.0) [0.0|4095.0] "" VIU0
 SG_ BMS_FaultNum10 : 123|12@0+ (1.0,0.0) [0.0|4095.0] "" VIU0
 SG_ BMS_FaultNum11 : 143|12@0+ (1.0,0.0) [0.0|4095.0] "" VIU0
 SG_ BMS_FaultNum12 : 147|12@0+ (1.0,0.0) [0.0|4095.0] "" VIU0
 SG_ BMS_FaultNum13 : 167|12@0+ (1.0,0.0) [0.0|4095.0] "" VIU0
 SG_ BMS_FaultNum14 : 171|12@0+ (1.0,0.0) [0.0|4095.0] "" VIU0
 SG_ BMS_FaultNum15 : 191|12@0+ (1.0,0.0) [0.0|4095.0] "" VIU0
 SG_ BMS_FaultNum16 : 195|12@0+ (1.0,0.0) [0.0|4095.0] "" VIU0
 SG_ BMS_FaultNum17 : 215|12@0+ (1.0,0.0) [0.0|4095.0] "" VIU0
 SG_ BMS_FaultNum18 : 219|12@0+ (1.0,0.0) [0.0|4095.0] "" VIU0
 SG_ BMS_FaultNum19 : 239|12@0+ (1.0,0.0) [0.0|4095.0] "" VIU0
 SG_ BMS_FaultNum2 : 27|12@0+ (1.0,0.0) [0.0|4095.0] "" VIU0
 SG_ BMS_FaultNum20 : 243|12@0+ (1.0,0.0) [0.0|4095.0] "" VIU0
 SG_ BMS_FaultNum3 : 47|12@0+ (1.0,0.0) [0.0|4095.0] "" VIU0
 SG_ BMS_FaultNum4 : 51|12@0+ (1.0,0.0) [0.0|4095.0] "" VIU0
 SG_ BMS_FaultNum5 : 71|12@0+ (1.0,0.0) [0.0|4095.0] "" VIU0
 SG_ BMS_FaultNum6 : 75|12@0+ (1.0,0.0) [0.0|4095.0] "" VIU0
 SG_ BMS_FaultNum7 : 95|12@0+ (1.0,0.0) [0.0|4095.0] "" VIU0
 SG_ BMS_FaultNum8 : 99|12@0+ (1.0,0.0) [0.0|4095.0] "" VIU0
 SG_ BMS_FaultNum9 : 119|12@0+ (1.0,0.0) [0.0|4095.0] "" VIU0
 SG_ BMS_FrameIndex : 12|5@0+ (1.0,0.0) [0.0|31.0] "" VIU0
 SG_ BMS_SupplierNum : 15|3@0+ (1.0,0.0) [0.0|7.0] "" VIU0
 SG_ BMS_TotalFaultNum : 7|8@0+ (1.0,0.0) [0.0|255.0] "" VIU0

BO_ 1416 BMS_GBInfo : 32 BMS
 SG_ BMS_BattConstnceErrGb : 170|1@0+ (1,0) [0|1] "" VIU0
 SG_ BMS_BattIGb : 183|16@0+ (0.1,-1000.0) [-1000.0|5553.5] "A" VIU0
 SG_ BMS_BattMatchErrGb : 169|1@0+ (1,0) [0|1] "" VIU0
 SG_ BMS_BattNrTotGb : 223|8@0+ (1.0,0.0) [0.0|255.0] "" VIU0
 SG_ BMS_BattSocHiGb : 167|1@0+ (1,0) [0|1] "" VIU0
 SG_ BMS_BattSocJmpGb : 168|1@0+ (1,0) [0|1] "" VIU0
 SG_ BMS_BattSocLoGb : 164|1@0+ (1,0) [0|1] "" VIU0
 SG_ BMS_BattTOverGb : 161|1@0+ (1,0) [0|1] "" VIU0
 SG_ BMS_BattUGb : 199|16@0+ (0.1,0.0) [0.0|6553.5] "V" VIU0
 SG_ BMS_BattUMaxNrGb : 55|8@0+ (1.0,0.0) [0.0|255.0] "" VIU0
 SG_ BMS_BattUMinNrGb : 87|8@0+ (1.0,0.0) [0.0|255.0] "" VIU0
 SG_ BMS_BattUOverGb : 163|1@0+ (1,0) [0|1] "" VIU0
 SG_ BMS_BattUUnderGb : 162|1@0+ (1,0) [0|1] "" VIU0
 SG_ BMS_CellNrTotGb : 23|16@0+ (1.0,0.0) [0.0|65535.0] "" VIU0
 SG_ BMS_CellUMaxGb : 71|16@0+ (0.001,0.0) [0.0|65.535] "V" VIU0
 SG_ BMS_CellUMaxNrGb : 63|8@0+ (1.0,0.0) [0.0|255.0] "" VIU0
 SG_ BMS_CellUMinGb : 103|16@0+ (0.001,0.0) [0.0|65.535] "V" VIU0
 SG_ BMS_CellUMinNrGb : 95|8@0+ (1.0,0.0) [0.0|255.0] "" VIU0
 SG_ BMS_CellUOverGb : 166|1@0+ (1,0) [0|1] "" VIU0
 SG_ BMS_CellUUnderGb : 165|1@0+ (1,0) [0|1] "" VIU0
 SG_ BMS_ChrgOverGb : 172|1@0+ (1,0) [0|1] "" VIU0
 SG_ BMS_ChrgStGb : 226|3@0+ (1,0) [0|7] "" VIU0
 SG_ BMS_DeltaTOverGb : 160|1@0+ (1,0) [0|1] "" VIU0
 SG_ BMS_HvilStsGb : 171|1@0+ (1,0) [0|1] "" VIU0
 SG_ BMS_InsulationRGb : 7|16@0+ (1.0,0.0) [0.0|60000.0] "kΩ" VIU0
 SG_ BMS_InsulationStsGb : 173|1@0+ (1,0) [0|1] "" VIU0
 SG_ BMS_ModTMaxGb : 135|8@0+ (1.0,-40.0) [-40.0|215.0] "℃" VIU0
 SG_ BMS_ModTMaxNrGb : 119|8@0+ (1.0,0.0) [0.0|255.0] "" VIU0
 SG_ BMS_ModTMinGb : 159|8@0+ (1.0,-40.0) [-40.0|215.0] "℃" VIU0
 SG_ BMS_ModTMinNrGb : 143|8@0+ (1.0,0.0) [0.0|255.0] "" VIU0
 SG_ BMS_SnsrTMaxNrGb : 127|8@0+ (1.0,0.0) [0.0|255.0] "" VIU0
 SG_ BMS_SnsrTMinNrGb : 151|8@0+ (1.0,0.0) [0.0|255.0] "" VIU0
 SG_ BMS_SnsrTNrTotGb : 39|16@0+ (1.0,0.0) [0.0|65535.0] "" VIU0
 SG_ BMS_SocGb : 215|8@0+ (1.0,0.0) [0.0|255.0] "%" VIU0

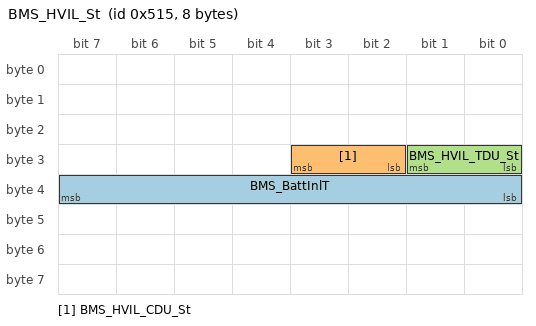
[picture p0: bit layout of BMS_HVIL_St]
BO_ 1301 BMS_HVIL_St : 8 BMS
 SG_ BMS_BattInlT : 39|8@0+ (1.0,-48.0) [0.0|207.0] "℃" PICU
 SG_ BMS_HVIL_CDU_St : 27|2@0+ (1,0) [0|3] "" PICU,VIU0
 SG_ BMS_HVIL_TDU_St : 25|2@0+ (1,0) [0|3] "" PICU,VIU0

BO_ 260 BMS_Measure : 32 BMS
 SG_ BMS_BattCurrt : 150|15@0+ (0.1,-1000.0) [-1000.0|2000.0] "A" PEU,PICU,TC,VIU0
 SG_ BMS_BattCurrtSnsr1 : 166|15@0+ (0.1,-1000.0) [-1000.0|2000.0] "A" TESTER
 SG_ BMS_BattCurrtSnsr1PreFail : 167|1@0+ (1,0) [0|1] "" TESTER
 SG_ BMS_BattCurrtSnsr2 : 182|15@0+ (0.1,-1000.0) [-1000.0|2000.0] "A" TESTER
 SG_ BMS_BattCurrtSnsr2PreFail : 183|1@0+ (1,0) [0|1] "" TESTER
 SG_ BMS_BattVolt_U1 : 213|14@0+ (0.1,0.0) [0.0|1000.0] "V" TC,TESTER
 SG_ BMS_BattVolt_U2 : 229|14@0+ (0.1,0.0) [0.0|1000.0] "V" TESTER
 SG_ BMS_BattVolt_U7 : 85|14@0+ (0.1,0.0) [0.0|1000.0] "V" CCU,PEU,PICU,TC,VIU0
 SG_ BMS_BattVolt_U8 : 101|14@0+ (0.1,0.0) [0.0|1000.0] "V" TESTER
 SG_ BMS_LVBattVolt_KL30 : 119|8@0+ (0.1,0.0) [0.0|24.0] "V" TESTER
 SG_ BMS_LVBattVolt_Relay : 127|8@0+ (0.1,0.0) [0.0|24.0] "V" TESTER
 SG_ BMS_Measure_Checksum : 7|16@0+ (1.0,0.0) [0.0|65535.0] "" CCU,TC,VIU0
 SG_ BMS_Measure_Counter : 23|8@0+ (1.0,0.0) [0.0|255.0] "" CCU,TC,VIU0
 SG_ BMS_vPackG0PreFail : 86|1@0+ (1,0) [0|1] "" TESTER
 SG_ BMS_vPackG1PreFail : 87|1@0+ (1,0) [0|1] "" VIU0

BO_ 269 BMS_SOX_1 : 32 BMS
 SG_ BMS_CurrtLimitCharge : 229|14@0+ (0.1,-1000.0) [-1000.0|0.0] "A" VIU0
 SG_ BMS_CurrtLimitDrive : 213|14@0+ (0.1,0.0) [0.0|1000.0] "A" VIU0
 SG_ BMS_CurrtLimitFeedback : 245|14@0+ (0.1,-1000.0) [-1000.0|0.0] "A" VIU0
 SG_ BMS_PackPwr : 134|15@0+ (0.1,-1000.0) [-1000.0|1000.0] "kW" TESTER
 SG_ BMS_PackSOCActual : 41|10@0+ (0.1,0.0) [0.0|100.0] "%" PICU,TC,TESTER
 SG_ BMS_PackSOCCalc : 111|10@0+ (0.1,0.0) [0.0|100.0] "%" TESTER
 SG_ BMS_PackSOCDisp : 62|7@0+ (1.0,0.0) [0.0|100.0] "%" PEU,PICU,VIU0
 SG_ BMS_PackSOCRange : 113|10@0+ (0.1,0.0) [0.0|100.0] "%" PICU,VIU0
 SG_ BMS_PackSOEActual : 87|18@0+ (1.0,0.0) [0.0|200000.0] "wh" TESTER
 SG_ BMS_PackSOEDisp : 31|18@0+ (1.0,0.0) [0.0|200000.0] "wh" VIU0
 SG_ BMS_PackSOHDisp : 193|10@0+ (0.1,0.0) [0.0|100.0] "%" VIU0
 SG_ BMS_PackSOX_Checksum : 7|16@0+ (1.0,0.0) [0.0|65535.0] "" VIU0
 SG_ BMS_PackSOX_Counter : 23|8@0+ (1.0,0.0) [0.0|255.0] "" VIU0
 SG_ BMS_PwrLimitCharge : 165|14@0+ (0.1,-1000.0) [-1000.0|0.0] "kW" PICU,VIU0
 SG_ BMS_PwrLimitDrive : 149|14@0+ (0.1,0.0) [0.0|1000.0] "kW" PICU,VIU0
 SG_ BMS_PwrLimitFeedback : 181|14@0+ (0.1,-1000.0) [-1000.0|0.0] "kW" PICU,VIU0

BO_ 528 BMS_SOX_2 : 32 BMS
 SG_ BMS_ChrgCurrtContnsMax : 181|14@0+ (0.1,-1000.0) [-1000.0|0.0] "A" VIU0
 SG_ BMS_ChrgCurrtLongTiMax : 247|14@0+ (0.1,-1000.0) [-1000.0|0.0] "A" TESTER
 SG_ BMS_ChrgCurrtShoTiMax : 103|14@0+ (0.1,-1000.0) [-1000.0|0.0] "A" TESTER
 SG_ BMS_ChrgPwrContnsMax : 149|14@0+ (0.1,-1000.0) [-1000.0|0.0] "kW" VIU0
 SG_ BMS_ChrgPwrLongTiMax : 215|14@0+ (0.1,-1000.0) [-1000.0|0.0] "kW" TESTER
 SG_ BMS_ChrgPwrShoTiMax : 47|14@0+ (0.1,-1000.0) [-1000.0|0.0] "kW" TESTER
 SG_ BMS_DchaCurrtContnsMax : 165|14@0+ (0.1,0.0) [0.0|1000.0] "A" VIU0
 SG_ BMS_DchaCurrtLongTiMax : 231|14@0+ (0.1,0.0) [0.0|1000.0] "A" TESTER
 SG_ BMS_DchaCurrtShoTiMax : 87|14@0+ (0.1,0.0) [0.0|1000.0] "A" TESTER
 SG_ BMS_DchaPwrContnsMax : 133|14@0+ (0.1,0.0) [0.0|1000.0] "kW" VIU0
 SG_ BMS_DchaPwrLongTiMax : 119|14@0+ (0.1,0.0) [0.0|1000.0] "kW" TESTER
 SG_ BMS_DchaPwrShoTiMax : 31|14@0+ (0.1,0.0) [0.0|1000.0] "kW" TESTER
 SG_ BMS_NormSOPLimSt : 79|3@0+ (1,0) [0|7] "" TESTER
 SG_ BMS_PackSOCNotAvrlble : 49|10@0+ (0.1,0.0) [0.0|100.0] "%" TESTER

BO_ 263 BMS_State : 32 BMS
 SG_ BMS_AbnormalPollingSt : 102|2@0+ (1,0) [0|3] "" VIU0
 SG_ BMS_AFEWakeupSt : 85|2@0+ (1,0) [0|3] "" TESTER
 SG_ BMS_APlusWakeupSt : 91|2@0+ (1,0) [0|3] "" TESTER
 SG_ BMS_BPSWakeupSt : 81|2@0+ (1,0) [0|3] "" TESTER
 SG_ BMS_CC1WakeupSt : 95|2@0+ (1,0) [0|3] "" TESTER
 SG_ BMS_CC2WakeupSt : 89|2@0+ (1,0) [0|3] "" TESTER
 SG_ BMS_CrashSt : 55|3@0+ (1,0) [0|7] "" VIU0
 SG_ BMS_DCBBoxRlyCtrlCmd : 144|1@0+ (1,0) [0|1] "" TESTER
 SG_ BMS_DCBCapRlyCtrlCmd : 145|1@0+ (1,0) [0|1] "" TESTER
 SG_ BMS_DCBInpUReq : 159|16@0+ (0.1,0.0) [0.0|6553.5] "V" TC
 SG_ BMS_DCBoostChrgReq : 191|2@0+ (1,0) [0|3] "" VIU0
 SG_ BMS_DCChrgProtocolVers : 119|8@0+ (1.0,0.0) [0.0|255.0] "" VIU0
 SG_ BMS_FaultLevel : 51|4@0+ (1,0) [0|15] "" PICU,VIU0
 SG_ BMS_HVIL_FC_St : 31|2@0+ (1,0) [0|3] "" VIU0
 SG_ BMS_HVIL_FMot_St : 39|2@0+ (1,0) [0|3] "" VIU0
 SG_ BMS_HVIL_RMot_St : 41|2@0+ (1,0) [0|3] "" VIU0
 SG_ BMS_HWWakeupSt : 93|2@0+ (1,0) [0|3] "" TESTER
 SG_ BMS_InsulationFaultlevel : 100|2@0+ (1,0) [0|3] "" VIU0
 SG_ BMS_InsulationSt : 111|3@0+ (1,0) [0|7] "" VIU0
 SG_ BMS_LowSOCHVOffReq : 52|1@0+ (1,0) [0|1] "" PICU,VIU0
 SG_ BMS_MainNegSt : 45|2@0+ (1,0) [0|3] "" TC,VIU0
 SG_ BMS_MainPosSt : 47|2@0+ (1,0) [0|3] "" PEU,PICU,TC,VIU0
 SG_ BMS_MainPreChrgSt : 43|2@0+ (1,0) [0|3] "" TESTER
 SG_ BMS_MCURDCBoostChrgModReq : 150|2@0+ (1,0) [0|3] "" TC
 SG_ BMS_MCURDCBoostChrgOperReq : 148|3@0+ (1,0) [0|7] "" TC
 SG_ BMS_MCURDCBoostChrgOutpIReq : 215|16@0+ (0.1,0.0) [0.0|6553.5] "A" TC
 SG_ BMS_MCURDCBoostChrgOutpUReq : 175|16@0+ (0.1,0.0) [0.0|6553.5] "V" TC
 SG_ BMS_NegInsulationSt : 29|3@0+ (1,0) [0|7] "" VIU0
 SG_ BMS_NMWakeupSt : 87|2@0+ (1,0) [0|3] "" TESTER
 SG_ BMS_OBDFaultExistSts : 103|1@0+ (1,0) [0|1] "" PICU,VIU0
 SG_ BMS_OperSt : 59|4@0+ (1,0) [0|15] "" PICU,VIU0
 SG_ BMS_PckInsulationSt : 98|3@0+ (1,0) [0|7] "" VIU0
 SG_ BMS_PosInsulationSt : 26|3@0+ (1,0) [0|7] "" VIU0
 SG_ BMS_RTCWakeupSt : 83|2@0+ (1,0) [0|3] "" TESTER
 SG_ BMS_State_Checksum : 7|16@0+ (1.0,0.0) [0.0|65535.0] "" TC,VIU0
 SG_ BMS_State_Counter : 23|8@0+ (1.0,0.0) [0.0|255.0] "" TC,VIU0
 SG_ BMS_ThermRunawaySt : 37|3@0+ (1,0) [0|7] "" PICU,VIU0
 SG_ BMS_VeInsulationSt : 34|3@0+ (1,0) [0|7] "" VIU0
 SG_ BMS_WorkMode : 63|4@0+ (1,0) [0|15] "" TESTER

BO_ 1417 BMS_Statistics : 32 BMS
 SG_ BMS_ACChrgCpDisp : 143|8@0+ (1.0,0.0) [0.0|250.0] "Ah" TESTER,VIU0
 SG_ BMS_ACChrgEngDisp : 135|8@0+ (1.0,0.0) [0.0|250.0] "kWh" TESTER
 SG_ BMS_BattType : 215|4@0+ (1,0) [0|15] "" TESTER,VIU0
 SG_ BMS_DCChrgCpDisp : 207|8@0+ (1.0,0.0) [0.0|250.0] "Ah" TESTER,VIU0
 SG_ BMS_DCChrgEngDisp : 199|8@0+ (1.0,0.0) [0.0|250.0] "kWh" TESTER
 SG_ BMS_DisChaCpDisp : 15|8@0+ (1.0,0.0) [0.0|250.0] "Ah" TESTER
 SG_ BMS_DisChaEngDisp : 7|8@0+ (1.0,0.0) [0.0|250.0] "kWh" TESTER
 SG_ BMS_RegenCpDisp : 79|8@0+ (1.0,0.0) [0.0|250.0] "Ah" TESTER
 SG_ BMS_RegenEngDisp : 71|8@0+ (1.0,0.0) [0.0|250.0] "kWh" TESTER
 SG_ BMS_TotalACChrgCpDisp : 173|22@0+ (1.0,0.0) [0.0|2500000.0] "Ah" TESTER
 SG_ BMS_TotalACChrgEngDisp : 149|22@0+ (1.0,0.0) [0.0|2500000.0] "kWh" TESTER
 SG_ BMS_TotalDCChrgCpDisp : 237|22@0+ (1.0,0.0) [0.0|2500000.0] "Ah" TESTER
 SG_ BMS_TotalDCChrgEngDisp : 211|22@0+ (1.0,0.0) [0.0|2500000.0] "kWh" TESTER
 SG_ BMS_TotalDisChaCpDisp : 45|22@0+ (1.0,0.0) [0.0|2500000.0] "Ah" TESTER,VIU0
 SG_ BMS_TotalDisChaEngDisp : 21|22@0+ (1.0,0.0) [0.0|2500000.0] "kWh" TESTER
 SG_ BMS_TotalRegenCpDisp : 109|22@0+ (1.0,0.0) [0.0|2500000.0] "Ah" TESTER,VIU0
 SG_ BMS_TotalRegenEngDisp : 85|22@0+ (1.0,0.0) [0.0|2500000.0] "kWh" TESTER

BO_ 791 BMS_TMSInfo : 32 BMS
 SG_ BMS_BattTempAvg : 55|8@0+ (1.0,-40.0) [-40.0|125.0] "℃" PICU,VIU0
 SG_ BMS_BattTempMax : 39|8@0+ (1.0,-40.0) [-40.0|125.0] "℃" PICU,VIU0
 SG_ BMS_BattTempMin : 47|8@0+ (1.0,-40.0) [-40.0|125.0] "℃" PICU,VIU0
 SG_ BMS_BookHeatStsRsp : 31|4@0+ (1,0) [0|15] "" VIU0
 SG_ BMS_CoolingLevel : 149|3@0+ (1,0) [0|7] "" PICU,VIU0
 SG_ BMS_HeatingLevel : 146|3@0+ (1,0) [0|7] "" PICU,VIU0
 SG_ BMS_HeatngActuPwr : 135|8@0+ (0.1,0.0) [0.0|25.5] "KW" PICU,VIU0
 SG_ BMS_HeatReq : 59|2@0+ (1,0) [0|3] "" PICU,VIU0
 SG_ BMS_NavChrgThermStFb : 154|3@0+ (1,0) [0|7] "" VIU0
 SG_ BMS_PasCoolAllwd : 159|2@0+ (1,0) [0|3] "" PICU
 SG_ BMS_PasHeatAllwd : 157|2@0+ (1,0) [0|3] "" PICU
 SG_ BMS_PreHeatEnergyEst : 111|16@0+ (1.0,0.0) [0.0|65535.0] "wh" TESTER
 SG_ BMS_PreHeatTimeEst : 90|11@0+ (1.0,0.0) [0.0|2047.0] "min" TESTER
 SG_ BMS_RemThermTiEstimn : 167|8@0+ (1.0,0.0) [0.0|60.0] "min" VIU0
 SG_ BMS_ThermalRequest : 27|4@0+ (1,0) [0|15] "" PICU,VIU0
 SG_ BMS_ThermalScene : 63|4@0+ (1,0) [0|15] "" PICU
 SG_ BMS_ThermUsgAllwd : 151|2@0+ (1,0) [0|3] "" PICU
 SG_ BMS_TrgtFlowRate : 87|9@0+ (0.5,0.0) [0.0|100.0] "L/min" PICU
 SG_ BMS_TrgtInletTemp : 127|8@0+ (0.5,-20.0) [-20.0|60.0] "℃" PICU

BO_ 1422 BMS_TraceCode : 32 BMS
 SG_ BMS_BattTraceCodLen : 7|8@0+ (1.0,0.0) [0.0|255.0] "" VIU0
 SG_ BMS_BattTraceCodN1 : 15|8@0+ (1,0) [0|255] "" VIU0
 SG_ BMS_BattTraceCodN10 : 87|8@0+ (1,0) [0|255] "" VIU0
 SG_ BMS_BattTraceCodN11 : 95|8@0+ (1,0) [0|255] "" VIU0
 SG_ BMS_BattTraceCodN12 : 103|8@0+ (1,0) [0|255] "" VIU0
 SG_ BMS_BattTraceCodN13 : 111|8@0+ (1,0) [0|255] "" VIU0
 SG_ BMS_BattTraceCodN14 : 119|8@0+ (1,0) [0|255] "" VIU0
 SG_ BMS_BattTraceCodN15 : 127|8@0+ (1,0) [0|255] "" VIU0
 SG_ BMS_BattTraceCodN16 : 135|8@0+ (1,0) [0|255] "" VIU0
 SG_ BMS_BattTraceCodN17 : 143|8@0+ (1,0) [0|255] "" VIU0
 SG_ BMS_BattTraceCodN18 : 151|8@0+ (1,0) [0|255] "" VIU0
 SG_ BMS_BattTraceCodN19 : 159|8@0+ (1,0) [0|255] "" VIU0
 SG_ BMS_BattTraceCodN2 : 23|8@0+ (1,0) [0|255] "" VIU0
 SG_ BMS_BattTraceCodN20 : 167|8@0+ (1,0) [0|255] "" VIU0
 SG_ BMS_BattTraceCodN21 : 175|8@0+ (1,0) [0|255] "" VIU0
 SG_ BMS_BattTraceCodN22 : 183|8@0+ (1,0) [0|255] "" VIU0
 SG_ BMS_BattTraceCodN23 : 191|8@0+ (1,0) [0|255] "" VIU0
 SG_ BMS_BattTraceCodN24 : 199|8@0+ (1,0) [0|255] "" VIU0
 SG_ BMS_BattTraceCodN3 : 31|8@0+ (1,0) [0|255] "" VIU0
 SG_ BMS_BattTraceCodN4 : 39|8@0+ (1,0) [0|255] "" VIU0
 SG_ BMS_BattTraceCodN5 : 47|8@0+ (1,0) [0|255] "" VIU0
 SG_ BMS_BattTraceCodN6 : 55|8@0+ (1,0) [0|255] "" VIU0
 SG_ BMS_BattTraceCodN7 : 63|8@0+ (1,0) [0|255] "" VIU0
 SG_ BMS_BattTraceCodN8 : 71|8@0+ (1,0) [0|255] "" VIU0
 SG_ BMS_BattTraceCodN9 : 79|8@0+ (1,0) [0|255] "" VIU0

// Signal Comments
CM_ SG_ 287 ABM_CrashTyp "碰撞类型
Crash Type";
CM_ SG_ 287 ABM_IMU_LateralAcceleration "Laterak acceleration signal(横向加速度信号)";
CM_ SG_ 287 ABM_IMU_LateralAccValid "Lateral acceleration signal valid(横向加速度信号有效位)";
CM_ SG_ 287 ABM_IMU_LongAcceleration "longitudinal acceleration signal(纵向加速度信号)";
CM_ SG_ 287 ABM_IMU_LongAccelerationValid "longitudinal acceleration valid(纵向加速度信号有效位)";
CM_ SG_ 287 ABM_IMU_Rollrate "翻滚角速率有效位";
CM_ SG_ 287 ABM_IMU_RollrateSigVld "翻滚角速率";
CM_ SG_ 287 ABM_IMU_VertA "垂直方向加速度";
CM_ SG_ 287 ABM_IMU_VertASigVld "垂直方向加速度有效位";
CM_ SG_ 287 ABM_IMU_YawRate "Yaw rate 
偏航率";
CM_ SG_ 287 ABM_IMU_YawRateValid "偏航率信号有效位";
CM_ SG_ 287 ABM_IMU_YrsCalibStatus "Calibration status of YRS(偏航率传感器标定状态)";
CM_ SG_ 287 ABM_State_Checksum "CRC16 checksum(DataID: 0x611F)";
CM_ SG_ 287 ABM_State_RollingCounter "Rolling Counter";
CM_ SG_ 287 ABM_WarningLampStatus "安全气囊警告灯状态
WarningLampStatus";
CM_ SG_ 810 ADS_CalSt "标定状态";
CM_ SG_ 810 ADS_FctSts "智驾功能状态";
CM_ SG_ 810 ADS_FlowReq "MDC冷却液流量请求";
CM_ SG_ 810 ADS_ForcedHiBeamCtrl "远光灯强控制";
CM_ SG_ 810 ADS_HVCtrlReq "ADS高压上电需求";
CM_ SG_ 810 ADS_HzrdLampReq "危险警告灯功能(双闪灯)开启请求";
CM_ SG_ 810 ADS_MdcCrtSts "MDC工作状态";
CM_ SG_ 810 ADS_PwrOnOffReq "MDC遥控泊车上下电请求";
CM_ SG_ 810 ADS_RcwWarningReq "RCW报警请求";
CM_ SG_ 810 ADS_RDAHzrdLampCtrl "RDA危险警告灯控制";
CM_ SG_ 810 ADS_SilentCoolgMod "静默冷却功能开关请求";
CM_ SG_ 810 ADS_State_Checksum "CRC16 checksum (Data ID:0x632A)";
CM_ SG_ 810 ADS_State_RollingCounter "Rolling Counter";
CM_ SG_ 810 ADS_SuspensionStatus "ADS空气悬架状态请求";
CM_ SG_ 810 ADS_ThmPostRun "MDC冷却请求标志";
CM_ SG_ 810 ADS_TurnLampReq "转向灯功能开启请求";
CM_ SG_ 810 MDC_FuncReq_SentryModDetec "哨兵模式待命状态";
CM_ SG_ 810 MDC_FuncReq_SentryModWarn "哨兵模式报警状态";
CM_ SG_ 810 MDC_PrivacyModeSts "智驾隐私安全模式状态";
CM_ SG_ 1415 BMS_BattEquilnSts "Pack均衡状态";
CM_ SG_ 1415 BMS_CellEquilnSts1 "1#单体均衡状态";
CM_ SG_ 1415 BMS_CellEquilnSts10 "10#单体均衡状态";
CM_ SG_ 1415 BMS_CellEquilnSts100 "100#单体均衡状态";
CM_ SG_ 1415 BMS_CellEquilnSts101 "101#单体均衡状态";
CM_ SG_ 1415 BMS_CellEquilnSts102 "102#单体均衡状态";
CM_ SG_ 1415 BMS_CellEquilnSts103 "103#单体均衡状态";
CM_ SG_ 1415 BMS_CellEquilnSts104 "104#单体均衡状态";
CM_ SG_ 1415 BMS_CellEquilnSts105 "105#单体均衡状态";
CM_ SG_ 1415 BMS_CellEquilnSts106 "106#单体均衡状态";
CM_ SG_ 1415 BMS_CellEquilnSts107 "107#单体均衡状态";
CM_ SG_ 1415 BMS_CellEquilnSts108 "108#单体均衡状态";
CM_ SG_ 1415 BMS_CellEquilnSts109 "109#单体均衡状态";
CM_ SG_ 1415 BMS_CellEquilnSts11 "11#单体均衡状态";
CM_ SG_ 1415 BMS_CellEquilnSts110 "110#单体均衡状态";
CM_ SG_ 1415 BMS_CellEquilnSts111 "111#单体均衡状态";
CM_ SG_ 1415 BMS_CellEquilnSts112 "112#单体均衡状态";
CM_ SG_ 1415 BMS_CellEquilnSts113 "113#单体均衡状态";
CM_ SG_ 1415 BMS_CellEquilnSts114 "114#单体均衡状态";
CM_ SG_ 1415 BMS_CellEquilnSts115 "115#单体均衡状态";
CM_ SG_ 1415 BMS_CellEquilnSts116 "116#单体均衡状态";
CM_ SG_ 1415 BMS_CellEquilnSts117 "117#单体均衡状态";
CM_ SG_ 1415 BMS_CellEquilnSts118 "118#单体均衡状态";
CM_ SG_ 1415 BMS_CellEquilnSts119 "119#单体均衡状态";
CM_ SG_ 1415 BMS_CellEquilnSts12 "12#单体均衡状态";
CM_ SG_ 1415 BMS_CellEquilnSts120 "120#单体均衡状态";
CM_ SG_ 1415 BMS_CellEquilnSts121 "121#单体均衡状态";
CM_ SG_ 1415 BMS_CellEquilnSts122 "122#单体均衡状态";
CM_ SG_ 1415 BMS_CellEquilnSts123 "123#单体均衡状态";
CM_ SG_ 1415 BMS_CellEquilnSts124 "124#单体均衡状态";
CM_ SG_ 1415 BMS_CellEquilnSts125 "125#单体均衡状态";
CM_ SG_ 1415 BMS_CellEquilnSts126 "126#单体均衡状态";
CM_ SG_ 1415 BMS_CellEquilnSts127 "127#单体均衡状态";
CM_ SG_ 1415 BMS_CellEquilnSts128 "128#单体均衡状态";
CM_ SG_ 1415 BMS_CellEquilnSts129 "129#单体均衡状态";
CM_ SG_ 1415 BMS_CellEquilnSts13 "13#单体均衡状态";
CM_ SG_ 1415 BMS_CellEquilnSts130 "130#单体均衡状态";
CM_ SG_ 1415 BMS_CellEquilnSts131 "131#单体均衡状态";
CM_ SG_ 1415 BMS_CellEquilnSts132 "132#单体均衡状态";
CM_ SG_ 1415 BMS_CellEquilnSts133 "133#单体均衡状态";
CM_ SG_ 1415 BMS_CellEquilnSts134 "134#单体均衡状态";
CM_ SG_ 1415 BMS_CellEquilnSts135 "135#单体均衡状态";
CM_ SG_ 1415 BMS_CellEquilnSts136 "136#单体均衡状态";
CM_ SG_ 1415 BMS_CellEquilnSts137 "137#单体均衡状态";
CM_ SG_ 1415 BMS_CellEquilnSts138 "138#单体均衡状态";
CM_ SG_ 1415 BMS_CellEquilnSts139 "139#单体均衡状态";
CM_ SG_ 1415 BMS_CellEquilnSts14 "14#单体均衡状态";
CM_ SG_ 1415 BMS_CellEquilnSts140 "140#单体均衡状态";
CM_ SG_ 1415 BMS_CellEquilnSts141 "141#单体均衡状态";
CM_ SG_ 1415 BMS_CellEquilnSts142 "142#单体均衡状态";
CM_ SG_ 1415 BMS_CellEquilnSts143 "143#单体均衡状态";
CM_ SG_ 1415 BMS_CellEquilnSts144 "144#单体均衡状态";
CM_ SG_ 1415 BMS_CellEquilnSts145 "145#单体均衡状态";
CM_ SG_ 1415 BMS_CellEquilnSts146 "146#单体均衡状态";
CM_ SG_ 1415 BMS_CellEquilnSts147 "147#单体均衡状态";
CM_ SG_ 1415 BMS_CellEquilnSts148 "148#单体均衡状态";
CM_ SG_ 1415 BMS_CellEquilnSts149 "149#单体均衡状态";
CM_ SG_ 1415 BMS_CellEquilnSts15 "15#单体均衡状态";
CM_ SG_ 1415 BMS_CellEquilnSts150 "150#单体均衡状态";
CM_ SG_ 1415 BMS_CellEquilnSts151 "151#单体均衡状态";
CM_ SG_ 1415 BMS_CellEquilnSts152 "152#单体均衡状态";
CM_ SG_ 1415 BMS_CellEquilnSts153 "153#单体均衡状态";
CM_ SG_ 1415 BMS_CellEquilnSts154 "154#单体均衡状态";
CM_ SG_ 1415 BMS_CellEquilnSts155 "155#单体均衡状态";
CM_ SG_ 1415 BMS_CellEquilnSts156 "156#单体均衡状态";
CM_ SG_ 1415 BMS_CellEquilnSts157 "157#单体均衡状态";
CM_ SG_ 1415 BMS_CellEquilnSts158 "158#单体均衡状态";
CM_ SG_ 1415 BMS_CellEquilnSts159 "159#单体均衡状态";
CM_ SG_ 1415 BMS_CellEquilnSts16 "16#单体均衡状态";
CM_ SG_ 1415 BMS_CellEquilnSts160 "160#单体均衡状态";
CM_ SG_ 1415 BMS_CellEquilnSts161 "161#单体均衡状态";
CM_ SG_ 1415 BMS_CellEquilnSts162 "162#单体均衡状态";
CM_ SG_ 1415 BMS_CellEquilnSts163 "163#单体均衡状态";
CM_ SG_ 1415 BMS_CellEquilnSts164 "164#单体均衡状态";
CM_ SG_ 1415 BMS_CellEquilnSts165 "165#单体均衡状态";
CM_ SG_ 1415 BMS_CellEquilnSts166 "166#单体均衡状态";
CM_ SG_ 1415 BMS_CellEquilnSts167 "167#单体均衡状态";
CM_ SG_ 1415 BMS_CellEquilnSts168 "168#单体均衡状态";
CM_ SG_ 1415 BMS_CellEquilnSts169 "169#单体均衡状态";
CM_ SG_ 1415 BMS_CellEquilnSts17 "17#单体均衡状态";
CM_ SG_ 1415 BMS_CellEquilnSts170 "170#单体均衡状态";
CM_ SG_ 1415 BMS_CellEquilnSts171 "171#单体均衡状态";
CM_ SG_ 1415 BMS_CellEquilnSts172 "172#单体均衡状态";
CM_ SG_ 1415 BMS_CellEquilnSts173 "173#单体均衡状态";
CM_ SG_ 1415 BMS_CellEquilnSts174 "174#单体均衡状态";
CM_ SG_ 1415 BMS_CellEquilnSts175 "175#单体均衡状态";
CM_ SG_ 1415 BMS_CellEquilnSts176 "176#单体均衡状态";
CM_ SG_ 1415 BMS_CellEquilnSts177 "177#单体均衡状态";
CM_ SG_ 1415 BMS_CellEquilnSts178 "178#单体均衡状态";
CM_ SG_ 1415 BMS_CellEquilnSts179 "179#单体均衡状态";
CM_ SG_ 1415 BMS_CellEquilnSts18 "18#单体均衡状态";
CM_ SG_ 1415 BMS_CellEquilnSts180 "180#单体均衡状态";
CM_ SG_ 1415 BMS_CellEquilnSts181 "181#单体均衡状态";
CM_ SG_ 1415 BMS_CellEquilnSts182 "182#单体均衡状态";
CM_ SG_ 1415 BMS_CellEquilnSts183 "183#单体均衡状态";
CM_ SG_ 1415 BMS_CellEquilnSts184 "184#单体均衡状态";
CM_ SG_ 1415 BMS_CellEquilnSts185 "185#单体均衡状态";
CM_ SG_ 1415 BMS_CellEquilnSts186 "186#单体均衡状态";
CM_ SG_ 1415 BMS_CellEquilnSts187 "187#单体均衡状态";
CM_ SG_ 1415 BMS_CellEquilnSts188 "188#单体均衡状态";
CM_ SG_ 1415 BMS_CellEquilnSts189 "189#单体均衡状态";
CM_ SG_ 1415 BMS_CellEquilnSts19 "19#单体均衡状态";
CM_ SG_ 1415 BMS_CellEquilnSts190 "190#单体均衡状态";
CM_ SG_ 1415 BMS_CellEquilnSts191 "191#单体均衡状态";
CM_ SG_ 1415 BMS_CellEquilnSts192 "192#单体均衡状态";
CM_ SG_ 1415 BMS_CellEquilnSts2 "2#单体均衡状态";
CM_ SG_ 1415 BMS_CellEquilnSts20 "20#单体均衡状态";
CM_ SG_ 1415 BMS_CellEquilnSts21 "21#单体均衡状态";
CM_ SG_ 1415 BMS_CellEquilnSts22 "22#单体均衡状态";
CM_ SG_ 1415 BMS_CellEquilnSts23 "23#单体均衡状态";
CM_ SG_ 1415 BMS_CellEquilnSts24 "24#单体均衡状态";
CM_ SG_ 1415 BMS_CellEquilnSts25 "25#单体均衡状态";
CM_ SG_ 1415 BMS_CellEquilnSts26 "26#单体均衡状态";
CM_ SG_ 1415 BMS_CellEquilnSts27 "27#单体均衡状态";
CM_ SG_ 1415 BMS_CellEquilnSts28 "28#单体均衡状态";
CM_ SG_ 1415 BMS_CellEquilnSts29 "29#单体均衡状态";
CM_ SG_ 1415 BMS_CellEquilnSts3 "3#单体均衡状态";
CM_ SG_ 1415 BMS_CellEquilnSts30 "30#单体均衡状态";
CM_ SG_ 1415 BMS_CellEquilnSts31 "31#单体均衡状态";
CM_ SG_ 1415 BMS_CellEquilnSts32 "32#单体均衡状态";
CM_ SG_ 1415 BMS_CellEquilnSts33 "33#单体均衡状态";
CM_ SG_ 1415 BMS_CellEquilnSts34 "34#单体均衡状态";
CM_ SG_ 1415 BMS_CellEquilnSts35 "35#单体均衡状态";
CM_ SG_ 1415 BMS_CellEquilnSts36 "36#单体均衡状态";
CM_ SG_ 1415 BMS_CellEquilnSts37 "37#单体均衡状态";
CM_ SG_ 1415 BMS_CellEquilnSts38 "38#单体均衡状态";
CM_ SG_ 1415 BMS_CellEquilnSts39 "39#单体均衡状态";
CM_ SG_ 1415 BMS_CellEquilnSts4 "4#单体均衡状态";
CM_ SG_ 1415 BMS_CellEquilnSts40 "40#单体均衡状态";
CM_ SG_ 1415 BMS_CellEquilnSts41 "41#单体均衡状态";
CM_ SG_ 1415 BMS_CellEquilnSts42 "42#单体均衡状态";
CM_ SG_ 1415 BMS_CellEquilnSts43 "43#单体均衡状态";
CM_ SG_ 1415 BMS_CellEquilnSts44 "44#单体均衡状态";
CM_ SG_ 1415 BMS_CellEquilnSts45 "45#单体均衡状态";
CM_ SG_ 1415 BMS_CellEquilnSts46 "46#单体均衡状态";
CM_ SG_ 1415 BMS_CellEquilnSts47 "47#单体均衡状态";
CM_ SG_ 1415 BMS_CellEquilnSts48 "48#单体均衡状态";
CM_ SG_ 1415 BMS_CellEquilnSts49 "49#单体均衡状态";
CM_ SG_ 1415 BMS_CellEquilnSts5 "5#单体均衡状态";
CM_ SG_ 1415 BMS_CellEquilnSts50 "50#单体均衡状态";
CM_ SG_ 1415 BMS_CellEquilnSts51 "51#单体均衡状态";
CM_ SG_ 1415 BMS_CellEquilnSts52 "52#单体均衡状态";
CM_ SG_ 1415 BMS_CellEquilnSts53 "53#单体均衡状态";
CM_ SG_ 1415 BMS_CellEquilnSts54 "54#单体均衡状态";
CM_ SG_ 1415 BMS_CellEquilnSts55 "55#单体均衡状态";
CM_ SG_ 1415 BMS_CellEquilnSts56 "56#单体均衡状态";
CM_ SG_ 1415 BMS_CellEquilnSts57 "57#单体均衡状态";
CM_ SG_ 1415 BMS_CellEquilnSts58 "58#单体均衡状态";
CM_ SG_ 1415 BMS_CellEquilnSts59 "59#单体均衡状态";
CM_ SG_ 1415 BMS_CellEquilnSts6 "6#单体均衡状态";
CM_ SG_ 1415 BMS_CellEquilnSts60 "60#单体均衡状态";
CM_ SG_ 1415 BMS_CellEquilnSts61 "61#单体均衡状态";
CM_ SG_ 1415 BMS_CellEquilnSts62 "62#单体均衡状态";
CM_ SG_ 1415 BMS_CellEquilnSts63 "63#单体均衡状态";
CM_ SG_ 1415 BMS_CellEquilnSts64 "64#单体均衡状态";
CM_ SG_ 1415 BMS_CellEquilnSts65 "65#单体均衡状态";
CM_ SG_ 1415 BMS_CellEquilnSts66 "66#单体均衡状态";
CM_ SG_ 1415 BMS_CellEquilnSts67 "67#单体均衡状态";
CM_ SG_ 1415 BMS_CellEquilnSts68 "68#单体均衡状态";
CM_ SG_ 1415 BMS_CellEquilnSts69 "69#单体均衡状态";
CM_ SG_ 1415 BMS_CellEquilnSts7 "7#单体均衡状态";
CM_ SG_ 1415 BMS_CellEquilnSts70 "70#单体均衡状态";
CM_ SG_ 1415 BMS_CellEquilnSts71 "71#单体均衡状态";
CM_ SG_ 1415 BMS_CellEquilnSts72 "72#单体均衡状态";
CM_ SG_ 1415 BMS_CellEquilnSts73 "73#单体均衡状态";
CM_ SG_ 1415 BMS_CellEquilnSts74 "74#单体均衡状态";
CM_ SG_ 1415 BMS_CellEquilnSts75 "75#单体均衡状态";
CM_ SG_ 1415 BMS_CellEquilnSts76 "76#单体均衡状态";
CM_ SG_ 1415 BMS_CellEquilnSts77 "77#单体均衡状态";
CM_ SG_ 1415 BMS_CellEquilnSts78 "78#单体均衡状态";
CM_ SG_ 1415 BMS_CellEquilnSts79 "79#单体均衡状态";
CM_ SG_ 1415 BMS_CellEquilnSts8 "8#单体均衡状态";
CM_ SG_ 1415 BMS_CellEquilnSts80 "80#单体均衡状态";
CM_ SG_ 1415 BMS_CellEquilnSts81 "81#单体均衡状态";
CM_ SG_ 1415 BMS_CellEquilnSts82 "82#单体均衡状态";
CM_ SG_ 1415 BMS_CellEquilnSts83 "83#单体均衡状态";
CM_ SG_ 1415 BMS_CellEquilnSts84 "84#单体均衡状态";
CM_ SG_ 1415 BMS_CellEquilnSts85 "85#单体均衡状态";
CM_ SG_ 1415 BMS_CellEquilnSts86 "86#单体均衡状态";
CM_ SG_ 1415 BMS_CellEquilnSts87 "87#单体均衡状态";
CM_ SG_ 1415 BMS_CellEquilnSts88 "88#单体均衡状态";
CM_ SG_ 1415 BMS_CellEquilnSts89 "89#单体均衡状态";
CM_ SG_ 1415 BMS_CellEquilnSts9 "9#单体均衡状态";
CM_ SG_ 1415 BMS_CellEquilnSts90 "90#单体均衡状态";
CM_ SG_ 1415 BMS_CellEquilnSts91 "91#单体均衡状态";
CM_ SG_ 1415 BMS_CellEquilnSts92 "92#单体均衡状态";
CM_ SG_ 1415 BMS_CellEquilnSts93 "93#单体均衡状态";
CM_ SG_ 1415 BMS_CellEquilnSts94 "94#单体均衡状态";
CM_ SG_ 1415 BMS_CellEquilnSts95 "95#单体均衡状态";
CM_ SG_ 1415 BMS_CellEquilnSts96 "96#单体均衡状态";
CM_ SG_ 1415 BMS_CellEquilnSts97 "97#单体均衡状态";
CM_ SG_ 1415 BMS_CellEquilnSts98 "98#单体均衡状态";
CM_ SG_ 1415 BMS_CellEquilnSts99 "99#单体均衡状态";
CM_ SG_ 1415 BMS_CellEquStSync "电芯均衡状态同步参数";
CM_ SG_ 1415 BMS_EquilnFltCellIdx "均衡回路故障对应采样电芯编号";
CM_ SG_ 389 BMS_ACChrgSt "交流充电状态";
CM_ SG_ 389 BMS_ACOutDischrgSt "交流对外放电状态";
CM_ SG_ 389 BMS_ActvHvOffReq "BMS主动下高压请求";
CM_ SG_ 389 BMS_ActvHvOnReq "BMS主动上高压请求";
CM_ SG_ 389 BMS_BattChrgNeeded "电池需要充电标志位";
CM_ SG_ 389 BMS_Cc2SngR "CC2电阻";
CM_ SG_ 389 BMS_ChargeInfo_Checksum "CRC16 checksum  (DataID: 0x8185)";
CM_ SG_ 389 BMS_ChargeInfo_Counter "Rolling Counter";
CM_ SG_ 389 BMS_ChrgASigSt "A+信号状态";
CM_ SG_ 389 BMS_ChrgASigVolt "A+电压";
CM_ SG_ 389 BMS_ChrgEndNum "充电结束码";
CM_ SG_ 389 BMS_ChrgForm "充电形式";
CM_ SG_ 389 BMS_ChrgLockReq "电子锁开闭锁请求";
CM_ SG_ 389 BMS_ChrgRemainTime "显示剩余充电时间";
CM_ SG_ 389 BMS_ChrgTiEstimn "备车充电预估时间";
CM_ SG_ 389 BMS_ChrgTrgtSOC "充电目标SOC";
CM_ SG_ 389 BMS_DCChrgConnectSt "DC充电枪状态";
CM_ SG_ 389 BMS_DCChrgSt "直流充电状态";
CM_ SG_ 389 BMS_DCOutDischrgSt "直流对外放电状态";
CM_ SG_ 389 BMS_DCPileInsuTestVoltMax "BMS直流桩绝缘检测最大电压";
CM_ SG_ 389 BMS_DeratingCoeff "充电电流降额系数";
CM_ SG_ 389 BMS_DrtngChg "降额充电标志位";
CM_ SG_ 389 BMS_FCNegRelaySt "快充负继电器状态";
CM_ SG_ 389 BMS_FCPosRelaySt "快充正继电器状态";
CM_ SG_ 389 BMS_HVONReq "高压上电请求";
CM_ SG_ 389 BMS_LinkEnergizeSt "BMS充电前加热供电状态";
CM_ SG_ 389 BMS_OBCCurrtReq "请求OBC工作电流";
CM_ SG_ 389 BMS_OBCInvACVoltReq "OBC放电交流侧电压请求值";
CM_ SG_ 389 BMS_OBCInvMaxPermPwr "OBC放电功率最大允许值";
CM_ SG_ 389 BMS_OBCVoltReq "请求OBC工作电压";
CM_ SG_ 389 BMS_OBCWorkModReq "充电机工作模式请求";
CM_ SG_ 389 BMS_PilePwrSt "BMS桩端供电状态";
CM_ SG_ 389 BMS_S1Req "OBC S1开关动作请求";
CM_ SG_ 389 BMS_S2SwtCtrl "S2开关控制信号";
CM_ SG_ 389 BMS_S4Req "OBC S4开关动作请求";
CM_ SG_ 795 BMS_AFEPreFail "AFE故障标志位";
CM_ SG_ 795 BMS_AFEPreFailNum "AFE故障标志位序号";
CM_ SG_ 795 BMS_ChrgCurrtLkUp "电池允许充电电流";
CM_ SG_ 795 BMS_CrashPWMDuty "碰撞PWM占空比";
CM_ SG_ 795 BMS_EquPreFail "均衡电路预故障标志";
CM_ SG_ 795 BMS_EquPreFailNum "均衡电路预故障标志位序号";
CM_ SG_ 795 BMS_HighTempFaultNTCIdx "高温离群NTC序号";
CM_ SG_ 795 BMS_HighTempFaultNTCNum "高温离群NTC数量";
CM_ SG_ 795 BMS_HVILFCVh "快充口高压互锁高边输出电压Vh";
CM_ SG_ 795 BMS_HVILFCVl "快充口高压互锁低边输出电压Vl";
CM_ SG_ 795 BMS_HVILPWRTrainFVh "前驱口高压互锁高边输出电压Vh";
CM_ SG_ 795 BMS_HVILPWRTrainFVl "前驱口高压互锁低边输出电压Vl";
CM_ SG_ 795 BMS_HVILPWRTrainRVh "后驱口高压互锁高边输出电压Vh";
CM_ SG_ 795 BMS_HVILPWRTrainRVl "后驱口高压互锁低边输出电压Vl";
CM_ SG_ 795 BMS_InsulationNeg "绝缘检测采集负极绝缘电阻(国标法)Rn";
CM_ SG_ 795 BMS_InsulationPos "绝缘检测采集正极绝缘电阻(国标法)Rp";
CM_ SG_ 795 BMS_InsulationVoltNeg "绝缘检测采集负极电压(国标法)Vn";
CM_ SG_ 795 BMS_InsulationVoltPos "绝缘检测采集正极电压(国标法)Vp";
CM_ SG_ 795 BMS_LowTempFaultNTCIdx "低温离群NTC序号";
CM_ SG_ 795 BMS_LowTempFaultNTCNum "低温离群NTC数量";
CM_ SG_ 795 BMS_PreChgScssTime "预充成功时的预充时间";
CM_ SG_ 795 BMS_TSmplngLnPreFail "电芯温度采样线故障标志位";
CM_ SG_ 795 BMS_TSmplngLnPreFailNum "电芯温度采样线故障标志位序号";
CM_ SG_ 795 BMS_VSmplngLnPreFail "电芯电压采样线故障标志位";
CM_ SG_ 795 BMS_VSmplngLnPreFailNum "电芯电压采样线故障标志位序号";
CM_ SG_ 797 BMS_CellMaxVolt "单体最高电压";
CM_ SG_ 797 BMS_CellMinVolt "单体最低电压";
CM_ SG_ 797 BMS_CellVoltSum "电芯电压累加和";
CM_ SG_ 797 BMS_MaxVoltCellNum "最高单体电压单体序号";
CM_ SG_ 797 BMS_MinVoltCellNum "最低单体电压单体序号";
CM_ SG_ 797 BMS_ModuleVolt1 "1#模组电压";
CM_ SG_ 797 BMS_ModuleVolt10 "10#模组电压";
CM_ SG_ 797 BMS_ModuleVolt11 "11#模组电压";
CM_ SG_ 797 BMS_ModuleVolt12 "12#模组电压";
CM_ SG_ 797 BMS_ModuleVolt13 "13#模组电压";
CM_ SG_ 797 BMS_ModuleVolt14 "14#模组电压";
CM_ SG_ 797 BMS_ModuleVolt2 "2#模组电压";
CM_ SG_ 797 BMS_ModuleVolt3 "3#模组电压";
CM_ SG_ 797 BMS_ModuleVolt4 "4#模组电压";
CM_ SG_ 797 BMS_ModuleVolt5 "5#模组电压";
CM_ SG_ 797 BMS_ModuleVolt6 "6#模组电压";
CM_ SG_ 797 BMS_ModuleVolt7 "7#模组电压";
CM_ SG_ 797 BMS_ModuleVolt8 "8#模组电压";
CM_ SG_ 797 BMS_ModuleVolt9 "9#模组电压";
CM_ SG_ 797 BMS_PrimaryCurrtSnsrTemp "第一电流传感器温度值";
CM_ SG_ 1299 BMS_EquTemp1 "1#均衡板温度";
CM_ SG_ 1299 BMS_EquTemp10 "10#均衡板温度";
CM_ SG_ 1299 BMS_EquTemp11 "11#均衡板温度";
CM_ SG_ 1299 BMS_EquTemp12 "12#均衡板温度";
CM_ SG_ 1299 BMS_EquTemp13 "13#均衡板温度";
CM_ SG_ 1299 BMS_EquTemp14 "14#均衡板温度";
CM_ SG_ 1299 BMS_EquTemp2 "2#均衡板温度";
CM_ SG_ 1299 BMS_EquTemp3 "3#均衡板温度";
CM_ SG_ 1299 BMS_EquTemp4 "4#均衡板温度";
CM_ SG_ 1299 BMS_EquTemp5 "5#均衡板温度";
CM_ SG_ 1299 BMS_EquTemp6 "6#均衡板温度";
CM_ SG_ 1299 BMS_EquTemp7 "7#均衡板温度";
CM_ SG_ 1299 BMS_EquTemp8 "8#均衡板温度";
CM_ SG_ 1299 BMS_EquTemp9 "9#均衡板温度";
CM_ SG_ 1299 BMS_MainNegBigLoadOpenCnt "主负继电器大负载断开次数";
CM_ SG_ 1299 BMS_MainNegLowLoadOpenCnt "主负继电器低负载断开次数";
CM_ SG_ 1299 BMS_MainNegMidLoadOpenCnt "主负继电器中负载断开次数";
CM_ SG_ 1299 BMS_MainNegOpenCnt "主负继电器总断开次数";
CM_ SG_ 1299 BMS_MainNegSuperLoadOpenCnt "主负继电器超大负载切断次数";
CM_ SG_ 1299 BMS_MainPosBigLoadOpenCnt "主正继电器大负载断开次数";
CM_ SG_ 1299 BMS_MainPosLowLoadOpenCnt "主正继电器低负载断开次数";
CM_ SG_ 1299 BMS_MainPosMidLoadOpenCnt "主正继电器中负载断开次数";
CM_ SG_ 1299 BMS_MainPosOpenCnt "主正继电器总断开次数";
CM_ SG_ 1299 BMS_MainPosSuperLoadOpenCnt "主正继电器超大负载切断次数";
CM_ SG_ 786 BMS_AirPressure "气压";
CM_ SG_ 786 BMS_AirPressureRate "气压变化率";
CM_ SG_ 786 BMS_BattSocUnderLamp "动力电池SOC低指示灯";
CM_ SG_ 786 BMS_BattTempRate "温度变化率";
CM_ SG_ 786 BMS_BattTLowLamp1 "动力电池低温报警指示灯1";
CM_ SG_ 786 BMS_BattTLowLamp2 "动力电池低温报警指示灯2";
CM_ SG_ 786 BMS_BattTOverLamp "动力电池高温报警指示灯";
CM_ SG_ 786 BMS_CalDataVers "标定数据版本";
CM_ SG_ 786 BMS_HVPwrDwnRsn "BMS下高压原因";
CM_ SG_ 786 BMS_HVPwrOnFailRsn "BMS上高压失败原因";
CM_ SG_ 786 BMS_InsulationProhibitRsn "BMS禁止绝缘原因";
CM_ SG_ 786 BMS_MIL_Request "动力电池故障指示灯(MIL)";
CM_ SG_ 786 BMS_PackSOHActual "真实SOH";
CM_ SG_ 786 BMS_PwrBattErrLamp "动力电池故障指示灯";
CM_ SG_ 786 BMS_ResetRsn "BMS复位原因";
CM_ SG_ 786 BMS_SOCCalAlarm "长时间未校准SOC提示";
CM_ SG_ 786 BMS_TRWarnRsn "热失控原因";
CM_ SG_ 461 BST_AchievedCellVoltage "达到单体电压的设定值";
CM_ SG_ 461 BST_AchievedPackVoltage "达到总电压的设定值";
CM_ SG_ 461 BST_AchievedSOC "达到所需的SOC目标值";
CM_ SG_ 461 BST_BatteryTempHigh "电池组温度故障";
CM_ SG_ 461 BST_BMSComponentsFault "BMS元件\输出连接器过温";
CM_ SG_ 461 BST_ChargeConnetorFault "充电连接器故障";
CM_ SG_ 461 BST_ChargeTeminated "充电机主动终止";
CM_ SG_ 461 BST_HVContactorFault "高压继电器故障";
CM_ SG_ 461 BST_InsulationFault "绝缘故障";
CM_ SG_ 461 BST_OtherFault "其他故障";
CM_ SG_ 461 BST_OutputConectorTempHigh "输出连接器过温";
CM_ SG_ 461 BST_OverCurrentError "电流过大";
CM_ SG_ 461 BST_Point2VoltageDetectFault "监测点2电压检测故障";
CM_ SG_ 461 BST_VoltageError "电压异常";
CM_ SG_ 461 CST_AchievedCondition "达到充电机设定的条件终止";
CM_ SG_ 461 CST_BMSAbort "BMS中止";
CM_ SG_ 461 CST_ChargeConnetorFault "充电连接器故障";
CM_ SG_ 461 CST_ChargeInnerTempFault "充电机内部过温";
CM_ SG_ 461 CST_ChargeStopFault "充电机急停故障";
CM_ SG_ 461 CST_ChargeTempHighFault "充电机过温故障";
CM_ SG_ 461 CST_CurrentMismathError "电流不匹配错误";
CM_ SG_ 461 CST_EnergyTransmitFault "所需电量不能传送";
CM_ SG_ 461 CST_FaultAbort "故障中止";
CM_ SG_ 461 CST_ManualAbort "人工中止";
CM_ SG_ 461 CST_OtherFault "其他故障";
CM_ SG_ 461 CST_VolateError "电压异常错误";
CM_ SG_ 862 BCL_ChareMode "充电模式";
CM_ SG_ 862 BCL_CurrentRequire "电流需求(A)";
CM_ SG_ 862 BCL_VoltageRequire "电压需求(V)";
CM_ SG_ 862 BEM_CCSTimeout "接收CCS超时";
CM_ SG_ 862 BEM_CRMTimeout00 "接收CRM=00超时";
CM_ SG_ 862 BEM_CRMTimeoutAA "接收CRM=AA超时";
CM_ SG_ 862 BEM_CROTimeout "接收CRO0超时";
CM_ SG_ 862 BEM_CSDTimeout "接收CSD超时";
CM_ SG_ 862 BEM_CSTTimeout "接收CST超时";
CM_ SG_ 862 BEM_CTS_CMLTimeout "接收CTS&CML超时";
CM_ SG_ 862 BEM_Other "其他";
CM_ SG_ 862 BRM_BatteryChargeTimes "电池组充电次数";
CM_ SG_ 862 BRM_BatteryManufacture "电池生产厂商名称";
CM_ SG_ 862 BRO_BMSChargeReady "BMS是否准备好";
CM_ SG_ 862 CCS_ChargeAllowed "充电允许";
CM_ SG_ 862 CCS_OutputCurent "桩端输出电流";
CM_ SG_ 862 CCS_OutputVoltage "桩端输出电压";
CM_ SG_ 862 CCS_TotalChargeTime "累计充电时间(min)";
CM_ SG_ 862 CEM_BCLTimeout "接收BCL报文超时";
CM_ SG_ 862 CEM_BCPTimeout "接收BCP报文超时";
CM_ SG_ 862 CEM_BCSTimeout "接收BCS报文超时";
CM_ SG_ 862 CEM_BRMTimeout "接收BRM报文超时";
CM_ SG_ 862 CEM_BROTimeout "接收BRO报文超时";
CM_ SG_ 862 CEM_BSDTimeout "接收BSD报文超时";
CM_ SG_ 862 CEM_BSTTimeout "接收BST报文超时";
CM_ SG_ 862 CEM_Other "其他";
CM_ SG_ 862 CHM_ComVersion "通信协议版本";
CM_ SG_ 862 CML_OutputCurentMax "最高输出电流";
CM_ SG_ 862 CML_OutputCurentMin "最低输出电流";
CM_ SG_ 862 CML_OutputVoltageMax "最高输出电压";
CM_ SG_ 862 CML_OutputVoltageMin "最低输出电压";
CM_ SG_ 862 CRM_ChargeNo "充电机编号";
CM_ SG_ 862 CRM_RecongnitionResult "辨识结果";
CM_ SG_ 862 CRM_RegionCode "充电站区域码";
CM_ SG_ 862 CRO_ChargeReady "充电机是否准备好";
CM_ SG_ 862 CSD_TotalChrgEnergy "CSD输出能量";
CM_ SG_ 1303 BMS_FaultNum1 "故障编号1";
CM_ SG_ 1303 BMS_FaultNum10 "故障编号10";
CM_ SG_ 1303 BMS_FaultNum11 "故障编号11";
CM_ SG_ 1303 BMS_FaultNum12 "故障编号12";
CM_ SG_ 1303 BMS_FaultNum13 "故障编号13";
CM_ SG_ 1303 BMS_FaultNum14 "故障编号14";
CM_ SG_ 1303 BMS_FaultNum15 "故障编号15";
CM_ SG_ 1303 BMS_FaultNum16 "故障编号16";
CM_ SG_ 1303 BMS_FaultNum17 "故障编号17";
CM_ SG_ 1303 BMS_FaultNum18 "故障编号18";
CM_ SG_ 1303 BMS_FaultNum19 "故障编号19";
CM_ SG_ 1303 BMS_FaultNum2 "故障编号2";
CM_ SG_ 1303 BMS_FaultNum20 "故障编号20";
CM_ SG_ 1303 BMS_FaultNum3 "故障编号3";
CM_ SG_ 1303 BMS_FaultNum4 "故障编号4";
CM_ SG_ 1303 BMS_FaultNum5 "故障编号5";
CM_ SG_ 1303 BMS_FaultNum6 "故障编号6";
CM_ SG_ 1303 BMS_FaultNum7 "故障编号7";
CM_ SG_ 1303 BMS_FaultNum8 "故障编号8";
CM_ SG_ 1303 BMS_FaultNum9 "故障编号9";
CM_ SG_ 1303 BMS_FrameIndex "帧序号";
CM_ SG_ 1303 BMS_SupplierNum "供应商代码";
CM_ SG_ 1303 BMS_TotalFaultNum "当前故障总数";
CM_ SG_ 1416 BMS_BattConstnceErrGb "动力电池一致性差报警";
CM_ SG_ 1416 BMS_BattIGb "电池总电流";
CM_ SG_ 1416 BMS_BattMatchErrGb "动力电池不匹配报警";
CM_ SG_ 1416 BMS_BattNrTotGb "动力电池包总数";
CM_ SG_ 1416 BMS_BattSocHiGb "SOC过高报警";
CM_ SG_ 1416 BMS_BattSocJmpGb "SOC跳变故障";
CM_ SG_ 1416 BMS_BattSocLoGb "SOC过低报警";
CM_ SG_ 1416 BMS_BattTOverGb "动力电池高温报警";
CM_ SG_ 1416 BMS_BattUGb "电池总电压";
CM_ SG_ 1416 BMS_BattUMaxNrGb "最高单体电压电池包序号";
CM_ SG_ 1416 BMS_BattUMinNrGb "最低单体电压电池包序号";
CM_ SG_ 1416 BMS_BattUOverGb "动力电池过压报警";
CM_ SG_ 1416 BMS_BattUUnderGb "动力电池欠压报警";
CM_ SG_ 1416 BMS_CellNrTotGb "单体电池总数";
CM_ SG_ 1416 BMS_CellUMaxGb "单体最高电压";
CM_ SG_ 1416 BMS_CellUMaxNrGb "最高单体电压单体序号";
CM_ SG_ 1416 BMS_CellUMinGb "单体最低电压";
CM_ SG_ 1416 BMS_CellUMinNrGb "最低单体电压单体序号";
CM_ SG_ 1416 BMS_CellUOverGb "单体蓄电池包过压报警";
CM_ SG_ 1416 BMS_CellUUnderGb "单体蓄电池包欠压报警";
CM_ SG_ 1416 BMS_ChrgOverGb "动力电池过充报警";
CM_ SG_ 1416 BMS_ChrgStGb "电池充电状态";
CM_ SG_ 1416 BMS_DeltaTOverGb "温度差异报警";
CM_ SG_ 1416 BMS_HvilStsGb "高压互锁状态报警";
CM_ SG_ 1416 BMS_InsulationRGb "绝缘电阻阻值";
CM_ SG_ 1416 BMS_InsulationStsGb "绝缘状态报警";
CM_ SG_ 1416 BMS_ModTMaxGb "单体最高温度";
CM_ SG_ 1416 BMS_ModTMaxNrGb "最高温度动力电池序号";
CM_ SG_ 1416 BMS_ModTMinGb "单体最低温度";
CM_ SG_ 1416 BMS_ModTMinNrGb "最低温度动力电池序号";
CM_ SG_ 1416 BMS_SnsrTMaxNrGb "最高温度探针序号";
CM_ SG_ 1416 BMS_SnsrTMinNrGb "最低温度探针序号";
CM_ SG_ 1416 BMS_SnsrTNrTotGb "动力电池温度探针总数";
CM_ SG_ 1416 BMS_SocGb "电池电量";
CM_ SG_ 1301 BMS_BattInlT "电池包进水口水温";
CM_ SG_ 1301 BMS_HVIL_CDU_St "OBC+DCDC互锁状态";
CM_ SG_ 1301 BMS_HVIL_TDU_St "空调压缩机+PTC互锁状态";
CM_ SG_ 260 BMS_BattCurrt "Pack电流";
CM_ SG_ 260 BMS_BattCurrtSnsr1 "Pack第一电流传感器读值";
CM_ SG_ 260 BMS_BattCurrtSnsr1PreFail "Pack第一电流传感器预故障标志";
CM_ SG_ 260 BMS_BattCurrtSnsr2 "Pack第二电流传感器读值";
CM_ SG_ 260 BMS_BattCurrtSnsr2PreFail "Pack第二电流传感器预故障标志";
CM_ SG_ 260 BMS_BattVolt_U1 "主正内侧-主负内侧电压U1";
CM_ SG_ 260 BMS_BattVolt_U2 "主正外侧-主负内侧电压U2";
CM_ SG_ 260 BMS_BattVolt_U7 "主正外侧电压-主负外侧电压U7(电池包后端输出电压)";
CM_ SG_ 260 BMS_BattVolt_U8 "主正外侧电压-快充负外侧电压U8";
CM_ SG_ 260 BMS_LVBattVolt_KL30 "BMS供电电压KL30";
CM_ SG_ 260 BMS_LVBattVolt_Relay "继电器驱动电压KL30";
CM_ SG_ 260 BMS_Measure_Checksum "CRC16 checksum  (DataID: 0x8104)";
CM_ SG_ 260 BMS_Measure_Counter "Rolling Counter";
CM_ SG_ 260 BMS_vPackG0PreFail "G0点电压预故障标志(U1\U2\U4)";
CM_ SG_ 260 BMS_vPackG1PreFail "G1点电压预故障标志(U7\U8)";
CM_ SG_ 269 BMS_CurrtLimitCharge "电池工况最大充电电流限值";
CM_ SG_ 269 BMS_CurrtLimitDrive "电池工况最大驱动电流限值";
CM_ SG_ 269 BMS_CurrtLimitFeedback "电池工况最大回馈电流限值";
CM_ SG_ 269 BMS_PackPwr "电池系统功率";
CM_ SG_ 269 BMS_PackSOCActual "真实SOC";
CM_ SG_ 269 BMS_PackSOCCalc "计算SOC";
CM_ SG_ 269 BMS_PackSOCDisp "显示SOC";
CM_ SG_ 269 BMS_PackSOCRange "续航SOC";
CM_ SG_ 269 BMS_PackSOEActual "真实SOE";
CM_ SG_ 269 BMS_PackSOEDisp "显示SOE";
CM_ SG_ 269 BMS_PackSOHDisp "显示SOH";
CM_ SG_ 269 BMS_PackSOX_Checksum "CRC16 checksum  (DataID: 0x810D)";
CM_ SG_ 269 BMS_PackSOX_Counter "Rolling Counter";
CM_ SG_ 269 BMS_PwrLimitCharge "电池工况最大充电功率限值";
CM_ SG_ 269 BMS_PwrLimitDrive "电池工况最大驱动功率限值";
CM_ SG_ 269 BMS_PwrLimitFeedback "电池工况最大回馈功率限值";
CM_ SG_ 528 BMS_ChrgCurrtContnsMax "电池持续充电电流";
CM_ SG_ 528 BMS_ChrgCurrtLongTiMax "电池长时充电电流";
CM_ SG_ 528 BMS_ChrgCurrtShoTiMax "电池短时充电电流";
CM_ SG_ 528 BMS_ChrgPwrContnsMax "电池持续充电功率";
CM_ SG_ 528 BMS_ChrgPwrLongTiMax "电池长时充电功率";
CM_ SG_ 528 BMS_ChrgPwrShoTiMax "电池短时充电功率";
CM_ SG_ 528 BMS_DchaCurrtContnsMax "电池持续放电电流";
CM_ SG_ 528 BMS_DchaCurrtLongTiMax "电池长时放电电流";
CM_ SG_ 528 BMS_DchaCurrtShoTiMax "电池短时放电电流";
CM_ SG_ 528 BMS_DchaPwrContnsMax "电池持续放电功率";
CM_ SG_ 528 BMS_DchaPwrLongTiMax "电池长时放电功率";
CM_ SG_ 528 BMS_DchaPwrShoTiMax "电池短时放电功率";
CM_ SG_ 528 BMS_NormSOPLimSt "非故障SOP限制状态";
CM_ SG_ 528 BMS_PackSOCNotAvrlble "不可用SOC";
CM_ SG_ 263 BMS_AbnormalPollingSt "BMS巡检异常状态";
CM_ SG_ 263 BMS_AFEWakeupSt "AFE唤醒源状态";
CM_ SG_ 263 BMS_APlusWakeupSt "A+唤醒源状态";
CM_ SG_ 263 BMS_BPSWakeupSt "BPS唤醒源状态";
CM_ SG_ 263 BMS_CC1WakeupSt "CC1唤醒源状态";
CM_ SG_ 263 BMS_CC2WakeupSt "CC2唤醒源状态";
CM_ SG_ 263 BMS_CrashSt "碰撞故障状态";
CM_ SG_ 263 BMS_DCBBoxRlyCtrlCmd "BMS升压负极接触器控制指令";
CM_ SG_ 263 BMS_DCBCapRlyCtrlCmd "BMS升压电容接触器控制指令";
CM_ SG_ 263 BMS_DCBInpUReq "快充电压转换模块输入电压请求";
CM_ SG_ 263 BMS_DCBoostChrgReq "快充升压需求";
CM_ SG_ 263 BMS_DCChrgProtocolVers "直流充电协议版本号";
CM_ SG_ 263 BMS_FaultLevel "BMS系统故障等级";
CM_ SG_ 263 BMS_HVIL_FC_St "快充口高压互锁状态";
CM_ SG_ 263 BMS_HVIL_FMot_St "前驱口高压互锁状态";
CM_ SG_ 263 BMS_HVIL_RMot_St "后驱口高压互锁状态";
CM_ SG_ 263 BMS_HWWakeupSt "硬线唤醒源状态";
CM_ SG_ 263 BMS_InsulationFaultlevel "绝缘故障等级";
CM_ SG_ 263 BMS_InsulationSt "绝缘状态";
CM_ SG_ 263 BMS_LowSOCHVOffReq "低电量下电请求标志位";
CM_ SG_ 263 BMS_MainNegSt "主负继电器状态";
CM_ SG_ 263 BMS_MainPosSt "主正继电器状态";
CM_ SG_ 263 BMS_MainPreChrgSt "预充继电器状态";
CM_ SG_ 263 BMS_MCURDCBoostChrgModReq "快充电压转换模块充电模式请求";
CM_ SG_ 263 BMS_MCURDCBoostChrgOperReq "BMS直流升压工作模式控制指令";
CM_ SG_ 263 BMS_MCURDCBoostChrgOutpIReq "快充电压转换模块输出电流请求";
CM_ SG_ 263 BMS_MCURDCBoostChrgOutpUReq "快充电压转换模块输出电压请求";
CM_ SG_ 263 BMS_NegInsulationSt "主负对地绝缘状态";
CM_ SG_ 263 BMS_NMWakeupSt "NM唤醒源状态";
CM_ SG_ 263 BMS_OBDFaultExistSts "当前驾驶循环BMS监测OBD实时故障标志位";
CM_ SG_ 263 BMS_OperSt "BMS工作状态";
CM_ SG_ 263 BMS_PckInsulationSt "电池包绝缘状态";
CM_ SG_ 263 BMS_PosInsulationSt "主正对地绝缘状态";
CM_ SG_ 263 BMS_RTCWakeupSt "RTC唤醒源状态";
CM_ SG_ 263 BMS_State_Checksum "CRC16 checksum  (DataID: 0x8107)";
CM_ SG_ 263 BMS_State_Counter "Rolling Counter";
CM_ SG_ 263 BMS_ThermRunawaySt "电池热失控状态";
CM_ SG_ 263 BMS_VeInsulationSt "整车绝缘状态";
CM_ SG_ 263 BMS_WorkMode "BMS工作模式";
CM_ SG_ 1417 BMS_ACChrgCpDisp "当前驾驶循环外插交流充电容量存储值";
CM_ SG_ 1417 BMS_ACChrgEngDisp "当前驾驶循环外插交流充电能量存储值";
CM_ SG_ 1417 BMS_BattType "动力电池类型";
CM_ SG_ 1417 BMS_DCChrgCpDisp "当前驾驶循环外插直流充电容量存储值";
CM_ SG_ 1417 BMS_DCChrgEngDisp "当前驾驶循环外插直流充电能量存储值";
CM_ SG_ 1417 BMS_DisChaCpDisp "当前驾驶循环放电容量存储值";
CM_ SG_ 1417 BMS_DisChaEngDisp "当前驾驶循环放电能量存储值";
CM_ SG_ 1417 BMS_RegenCpDisp "当前驾驶循环能量回收容量存储值";
CM_ SG_ 1417 BMS_RegenEngDisp "当前驾驶循环能量回收能量存储值";
CM_ SG_ 1417 BMS_TotalACChrgCpDisp "累计外插交流充电容量存储值";
CM_ SG_ 1417 BMS_TotalACChrgEngDisp "累计外插交流充电能量存储值";
CM_ SG_ 1417 BMS_TotalDCChrgCpDisp "累计外插直流充电容量存储值";
CM_ SG_ 1417 BMS_TotalDCChrgEngDisp "累计外插直流充电能量存储值";
CM_ SG_ 1417 BMS_TotalDisChaCpDisp "累计放电容量存储值";
CM_ SG_ 1417 BMS_TotalDisChaEngDisp "累计放电能量存储值";
CM_ SG_ 1417 BMS_TotalRegenCpDisp "累计能量回收容量存储值";
CM_ SG_ 1417 BMS_TotalRegenEngDisp "累计能量回收能量存储值";
CM_ SG_ 791 BMS_BattTempAvg "电池平均温度";
CM_ SG_ 791 BMS_BattTempMax "电池最高温度";
CM_ SG_ 791 BMS_BattTempMin "电池最低温度";
CM_ SG_ 791 BMS_BookHeatStsRsp "预约电池加热状态反馈";
CM_ SG_ 791 BMS_CoolingLevel "电池冷却等级";
CM_ SG_ 791 BMS_HeatingLevel "电池加热等级";
CM_ SG_ 791 BMS_HeatngActuPwr "电池加热膜实际功率";
CM_ SG_ 791 BMS_HeatReq "BMS加热请求";
CM_ SG_ 791 BMS_NavChrgThermStFb "BMS导航充电场景热管理状态反馈";
CM_ SG_ 791 BMS_PasCoolAllwd "电池利用整车余冷BMS许可标志位";
CM_ SG_ 791 BMS_PasHeatAllwd "电池利用整车余热BMS许可标志位";
CM_ SG_ 791 BMS_PreHeatEnergyEst "预估预热能量";
CM_ SG_ 791 BMS_PreHeatTimeEst "预估预热时间";
CM_ SG_ 791 BMS_RemThermTiEstimn "BMS反馈备车热管理所需时间";
CM_ SG_ 791 BMS_ThermalRequest "电池热管理请求";
CM_ SG_ 791 BMS_ThermalScene "电池热管理场景";
CM_ SG_ 791 BMS_ThermUsgAllwd "整车利用电池余热BMS许可标志位";
CM_ SG_ 791 BMS_TrgtFlowRate "请求水流量";
CM_ SG_ 791 BMS_TrgtInletTemp "请求进水口目标水温";
CM_ SG_ 1422 BMS_BattTraceCodLen "电池追溯码长度";
CM_ SG_ 1422 BMS_BattTraceCodN1 "电池追溯码(N1)";
CM_ SG_ 1422 BMS_BattTraceCodN10 "电池追溯码(N10)";
CM_ SG_ 1422 BMS_BattTraceCodN11 "电池追溯码(N11)";
CM_ SG_ 1422 BMS_BattTraceCodN12 "电池追溯码(N12)";
CM_ SG_ 1422 BMS_BattTraceCodN13 "电池追溯码(N13)";
CM_ SG_ 1422 BMS_BattTraceCodN14 "电池追溯码(N14)";
CM_ SG_ 1422 BMS_BattTraceCodN15 "电池追溯码(N15)";
CM_ SG_ 1422 BMS_BattTraceCodN16 "电池追溯码(N16)";
CM_ SG_ 1422 BMS_BattTraceCodN17 "电池追溯码(N17)";
CM_ SG_ 1422 BMS_BattTraceCodN18 "电池追溯码(N18)";
CM_ SG_ 1422 BMS_BattTraceCodN19 "电池追溯码(N19)";
CM_ SG_ 1422 BMS_BattTraceCodN2 "电池追溯码(N2)";
CM_ SG_ 1422 BMS_BattTraceCodN20 "电池追溯码(N20)";
CM_ SG_ 1422 BMS_BattTraceCodN21 "电池追溯码(N21)";
CM_ SG_ 1422 BMS_BattTraceCodN22 "电池追溯码(N22)";
CM_ SG_ 1422 BMS_BattTraceCodN23 "电池追溯码(N23)";
CM_ SG_ 1422 BMS_BattTraceCodN24 "电池追溯码(N24)";
CM_ SG_ 1422 BMS_BattTraceCodN3 "电池追溯码(N3)";
CM_ SG_ 1422 BMS_BattTraceCodN4 "电池追溯码(N4)";
CM_ SG_ 1422 BMS_BattTraceCodN5 "电池追溯码(N5)";
CM_ SG_ 1422 BMS_BattTraceCodN6 "电池追溯码(N6)";
CM_ SG_ 1422 BMS_BattTraceCodN7 "电池追溯码(N7)";
CM_ SG_ 1422 BMS_BattTraceCodN8 "电池追溯码(N8)";
CM_ SG_ 1422 BMS_BattTraceCodN9 "电池追溯码(N9)";

// Attribute definitions
BA_DEF_ BO_ "CANFD_BRS" ENUM "1","0"; //
BA_DEF_ BO_ "DiagRequest" ENUM "Yes","No"; //
BA_DEF_ BO_ "DiagResponse" ENUM "Yes","No"; //
BA_DEF_ BO_ "DiagState" ENUM "Yes","No"; //
BA_DEF_ BO_ "GenMsgSendType" ENUM "Cycle","Event","CE"; //
BA_DEF_ SG_ "GenSigSendType" ENUM "Cycle","OnWrite","OnWriteWithRepetition","OnChange","OnChangeWithRepetition"; //
BA_DEF_ BO_ "MSG IL Support" ENUM "Yes","No"; //
BA_DEF_ BO_ "NmMessage" ENUM "Yes","No"; //
BA_DEF_  "Baudrate" FLOAT 1000 1000000; // [bps]
BA_DEF_  "BaudRateCANFD" FLOAT 1000 10000000; // [bps]
BA_DEF_ BO_ "VFrameFormat" ENUM "StandardCAN","ExtendedCAN","reserved","J1939PG","reserved","reserved","reserved","reserved","reserved","reserved","reserved","reserved","reserved","reserved","StandardCAN_FD","ExtendedCAN_FD";
BA_DEF_ BO_ "GenMsgCycleTime" FLOAT 0 300000; // [ms]
BA_DEF_ BO_ "GenMsgStartDelayTime" FLOAT 0 300000; // [ms]
BA_DEF_ BO_ "GenMsgDelayTime" FLOAT 0 300000; // [ms]
BA_DEF_ SG_ "GenSigStartValue" FLOAT -1.7976931348623157E308 18446744073709551615;
BA_DEF_ BU_ "NmAsrNodeIdentifier" INT 0 255;
BA_DEF_ BU_ "NmAsrNode" ENUM "No","Yes";
BA_DEF_ BO_ "GenMsgNrOfRepetition" INT 0 100000;
BA_DEF_ BO_ "GenMsgCycleTimeFast" FLOAT 0 300000;
BA_DEF_  "DBName" STRING;
BA_DEF_  "BusType" STRING;
BA_DEF_  "ProtocolType" STRING;

BA_DEF_DEF_ "CANFD_BRS" "1";
BA_DEF_DEF_ "DiagRequest" "No";
BA_DEF_DEF_ "DiagResponse" "No";
BA_DEF_DEF_ "DiagState" "No";
BA_DEF_DEF_ "GenMsgSendType" "Cycle";
BA_DEF_DEF_ "GenSigSendType" "Cycle";
BA_DEF_DEF_ "MSG IL Support" "Yes";
BA_DEF_DEF_ "NmMessage" "No";
BA_DEF_DEF_ "VFrameFormat" "J1939PG";
BA_DEF_DEF_ "GenSigStartValue" 0;
BA_DEF_DEF_ "NmAsrNodeIdentifier" 0;
BA_DEF_DEF_ "NmAsrNode" "No";
BA_DEF_DEF_ "GenMsgNrOfRepetition" 0;
BA_DEF_DEF_ "DBName" "";
BA_DEF_DEF_ "BusType" "";
BA_DEF_DEF_ "ProtocolType" "";

// Network
BA_ "DBName" "PTCANFD";
BA_ "BusType" "CAN FD";
BA_ "ProtocolType" "CAN";
BA_ "Baudrate" 500000;
BA_ "BaudRateCANFD" 2000000;
// ECU: BMS
BA_ "NmAsrNodeIdentifier" BU_ BMS 18;
BA_ "NmAsrNode" BU_ BMS 1;
// ECU: CCU
BA_ "NmAsrNodeIdentifier" BU_ CCU 21;
BA_ "NmAsrNode" BU_ CCU 1;
// ECU: PEU
BA_ "NmAsrNodeIdentifier" BU_ PEU 24;
BA_ "NmAsrNode" BU_ PEU 1;
// ECU: PICU
BA_ "NmAsrNodeIdentifier" BU_ PICU 49;
BA_ "NmAsrNode" BU_ PICU 1;
// ECU: TC
BA_ "NmAsrNodeIdentifier" BU_ TC 20;
BA_ "NmAsrNode" BU_ TC 1;
// ECU: VIU0
BA_ "NmAsrNodeIdentifier" BU_ VIU0 17;
BA_ "NmAsrNode" BU_ VIU0 1;
// Frame: ABM_State_VV01
BA_ "VFrameFormat" BO_ 287 14;
BA_ "GenMsgCycleTime" BO_ 287 10.000;
BA_ "GenMsgStartDelayTime" BO_ 287 0.000;
BA_ "GenSigStartValue" SG_ 287 ABM_IMU_LateralAcceleration 4905;
BA_ "GenSigStartValue" SG_ 287 ABM_IMU_LateralAccValid 1;
BA_ "GenSigStartValue" SG_ 287 ABM_IMU_LongAcceleration 4905;
BA_ "GenSigStartValue" SG_ 287 ABM_IMU_LongAccelerationValid 1;
BA_ "GenSigStartValue" SG_ 287 ABM_IMU_Rollrate 30000;
BA_ "GenSigStartValue" SG_ 287 ABM_IMU_RollrateSigVld 1;
BA_ "GenSigStartValue" SG_ 287 ABM_IMU_VertA 4905;
BA_ "GenSigStartValue" SG_ 287 ABM_IMU_VertASigVld 1;
BA_ "GenSigStartValue" SG_ 287 ABM_IMU_YawRate 30000;
BA_ "GenSigStartValue" SG_ 287 ABM_IMU_YawRateValid 1;
// Frame: ADS_State
BA_ "VFrameFormat" BO_ 810 14;
BA_ "GenMsgSendType" BO_ 810 1;
// Frame: BMS_CellEquSt
BA_ "VFrameFormat" BO_ 1415 14;
BA_ "GenMsgCycleTime" BO_ 1415 1000.000;
BA_ "GenMsgStartDelayTime" BO_ 1415 0.000;
// Frame: BMS_ChargeInfo
BA_ "VFrameFormat" BO_ 389 14;
BA_ "GenMsgCycleTime" BO_ 389 20.000;
BA_ "GenMsgStartDelayTime" BO_ 389 0.000;
BA_ "GenSigStartValue" SG_ 389 BMS_ChrgRemainTime 8190;
BA_ "GenSigStartValue" SG_ 389 BMS_ChrgTiEstimn 8190;
BA_ "GenSigStartValue" SG_ 389 BMS_ChrgTrgtSOC 126;
BA_ "GenSigStartValue" SG_ 389 BMS_DeratingCoeff 1022;
BA_ "GenSigStartValue" SG_ 389 BMS_OBCCurrtReq 4094;
BA_ "GenSigStartValue" SG_ 389 BMS_OBCVoltReq 1022;
// Frame: BMS_DFX_1
BA_ "VFrameFormat" BO_ 795 14;
BA_ "GenMsgCycleTime" BO_ 795 100.000;
BA_ "GenMsgStartDelayTime" BO_ 795 0.000;
BA_ "GenSigStartValue" SG_ 795 BMS_ChrgCurrtLkUp 16382;
BA_ "GenSigStartValue" SG_ 795 BMS_CrashPWMDuty 126;
BA_ "GenSigStartValue" SG_ 795 BMS_HighTempFaultNTCIdx 62;
BA_ "GenSigStartValue" SG_ 795 BMS_HighTempFaultNTCNum 62;
BA_ "GenSigStartValue" SG_ 795 BMS_HVILFCVh 8190;
BA_ "GenSigStartValue" SG_ 795 BMS_HVILFCVl 8190;
BA_ "GenSigStartValue" SG_ 795 BMS_HVILPWRTrainFVh 8190;
BA_ "GenSigStartValue" SG_ 795 BMS_HVILPWRTrainFVl 8190;
BA_ "GenSigStartValue" SG_ 795 BMS_HVILPWRTrainRVh 8190;
BA_ "GenSigStartValue" SG_ 795 BMS_HVILPWRTrainRVl 8190;
BA_ "GenSigStartValue" SG_ 795 BMS_InsulationNeg 65534;
BA_ "GenSigStartValue" SG_ 795 BMS_InsulationPos 65534;
BA_ "GenSigStartValue" SG_ 795 BMS_InsulationVoltNeg 8190;
BA_ "GenSigStartValue" SG_ 795 BMS_InsulationVoltPos 8190;
BA_ "GenSigStartValue" SG_ 795 BMS_LowTempFaultNTCIdx 62;
BA_ "GenSigStartValue" SG_ 795 BMS_LowTempFaultNTCNum 62;
BA_ "GenSigStartValue" SG_ 795 BMS_PreChgScssTime 1022;
// Frame: BMS_DFX_2
BA_ "VFrameFormat" BO_ 797 14;
BA_ "GenMsgCycleTime" BO_ 797 100.000;
BA_ "GenMsgStartDelayTime" BO_ 797 0.000;
BA_ "GenSigStartValue" SG_ 797 BMS_CellMaxVolt 8190;
BA_ "GenSigStartValue" SG_ 797 BMS_CellMinVolt 8190;
BA_ "GenSigStartValue" SG_ 797 BMS_CellVoltSum 16382;
BA_ "GenSigStartValue" SG_ 797 BMS_ModuleVolt1 1022;
BA_ "GenSigStartValue" SG_ 797 BMS_ModuleVolt10 1022;
BA_ "GenSigStartValue" SG_ 797 BMS_ModuleVolt11 1022;
BA_ "GenSigStartValue" SG_ 797 BMS_ModuleVolt12 1022;
BA_ "GenSigStartValue" SG_ 797 BMS_ModuleVolt13 1022;
BA_ "GenSigStartValue" SG_ 797 BMS_ModuleVolt14 1022;
BA_ "GenSigStartValue" SG_ 797 BMS_ModuleVolt2 1022;
BA_ "GenSigStartValue" SG_ 797 BMS_ModuleVolt3 1022;
BA_ "GenSigStartValue" SG_ 797 BMS_ModuleVolt4 1022;
BA_ "GenSigStartValue" SG_ 797 BMS_ModuleVolt5 1022;
BA_ "GenSigStartValue" SG_ 797 BMS_ModuleVolt6 1022;
BA_ "GenSigStartValue" SG_ 797 BMS_ModuleVolt7 1022;
BA_ "GenSigStartValue" SG_ 797 BMS_ModuleVolt8 1022;
BA_ "GenSigStartValue" SG_ 797 BMS_ModuleVolt9 1022;
BA_ "GenSigStartValue" SG_ 797 BMS_PrimaryCurrtSnsrTemp 254;
// Frame: BMS_DFX_3
BA_ "VFrameFormat" BO_ 1299 14;
BA_ "GenMsgCycleTime" BO_ 1299 200.000;
BA_ "GenMsgStartDelayTime" BO_ 1299 0.000;
BA_ "GenSigStartValue" SG_ 1299 BMS_EquTemp1 254;
BA_ "GenSigStartValue" SG_ 1299 BMS_EquTemp10 254;
BA_ "GenSigStartValue" SG_ 1299 BMS_EquTemp11 254;
BA_ "GenSigStartValue" SG_ 1299 BMS_EquTemp12 254;
BA_ "GenSigStartValue" SG_ 1299 BMS_EquTemp13 254;
BA_ "GenSigStartValue" SG_ 1299 BMS_EquTemp14 254;
BA_ "GenSigStartValue" SG_ 1299 BMS_EquTemp2 254;
BA_ "GenSigStartValue" SG_ 1299 BMS_EquTemp3 254;
BA_ "GenSigStartValue" SG_ 1299 BMS_EquTemp4 254;
BA_ "GenSigStartValue" SG_ 1299 BMS_EquTemp5 254;
BA_ "GenSigStartValue" SG_ 1299 BMS_EquTemp6 254;
BA_ "GenSigStartValue" SG_ 1299 BMS_EquTemp7 254;
BA_ "GenSigStartValue" SG_ 1299 BMS_EquTemp8 254;
BA_ "GenSigStartValue" SG_ 1299 BMS_EquTemp9 254;
// Frame: BMS_ErrInfo
BA_ "VFrameFormat" BO_ 786 14;
BA_ "GenMsgCycleTime" BO_ 786 100.000;
BA_ "GenMsgStartDelayTime" BO_ 786 0.000;
BA_ "GenSigStartValue" SG_ 786 BMS_AirPressure 65534;
BA_ "GenSigStartValue" SG_ 786 BMS_AirPressureRate 254;
BA_ "GenSigStartValue" SG_ 786 BMS_BattTempRate 254;
BA_ "GenSigStartValue" SG_ 786 BMS_PackSOHActual 1022;
// Frame: BMS_FastChgErr
BA_ "VFrameFormat" BO_ 461 14;
BA_ "GenMsgCycleTime" BO_ 461 100.000;
BA_ "GenMsgStartDelayTime" BO_ 461 0.000;
BA_ "GenSigStartValue" SG_ 461 BST_AchievedCellVoltage 3;
BA_ "GenSigStartValue" SG_ 461 BST_AchievedPackVoltage 3;
BA_ "GenSigStartValue" SG_ 461 BST_AchievedSOC 3;
BA_ "GenSigStartValue" SG_ 461 BST_BatteryTempHigh 3;
BA_ "GenSigStartValue" SG_ 461 BST_BMSComponentsFault 3;
BA_ "GenSigStartValue" SG_ 461 BST_ChargeConnetorFault 3;
BA_ "GenSigStartValue" SG_ 461 BST_ChargeTeminated 3;
BA_ "GenSigStartValue" SG_ 461 BST_HVContactorFault 3;
BA_ "GenSigStartValue" SG_ 461 BST_InsulationFault 3;
BA_ "GenSigStartValue" SG_ 461 BST_OtherFault 3;
BA_ "GenSigStartValue" SG_ 461 BST_OutputConectorTempHigh 3;
BA_ "GenSigStartValue" SG_ 461 BST_OverCurrentError 3;
BA_ "GenSigStartValue" SG_ 461 BST_Point2VoltageDetectFault 3;
BA_ "GenSigStartValue" SG_ 461 BST_VoltageError 3;
BA_ "GenSigStartValue" SG_ 461 CST_AchievedCondition 3;
BA_ "GenSigStartValue" SG_ 461 CST_BMSAbort 3;
BA_ "GenSigStartValue" SG_ 461 CST_ChargeConnetorFault 3;
BA_ "GenSigStartValue" SG_ 461 CST_ChargeInnerTempFault 3;
BA_ "GenSigStartValue" SG_ 461 CST_ChargeStopFault 3;
BA_ "GenSigStartValue" SG_ 461 CST_ChargeTempHighFault 3;
BA_ "GenSigStartValue" SG_ 461 CST_CurrentMismathError 3;
BA_ "GenSigStartValue" SG_ 461 CST_EnergyTransmitFault 3;
BA_ "GenSigStartValue" SG_ 461 CST_FaultAbort 3;
BA_ "GenSigStartValue" SG_ 461 CST_ManualAbort 3;
BA_ "GenSigStartValue" SG_ 461 CST_OtherFault 3;
BA_ "GenSigStartValue" SG_ 461 CST_VolateError 3;
// Frame: BMS_FastChgInfo
BA_ "VFrameFormat" BO_ 862 14;
BA_ "GenMsgCycleTime" BO_ 862 100.000;
BA_ "GenMsgStartDelayTime" BO_ 862 0.000;
BA_ "GenSigStartValue" SG_ 862 BCL_ChareMode 254;
BA_ "GenSigStartValue" SG_ 862 BCL_CurrentRequire 65534;
BA_ "GenSigStartValue" SG_ 862 BCL_VoltageRequire 65534;
BA_ "GenSigStartValue" SG_ 862 BEM_CCSTimeout 3;
BA_ "GenSigStartValue" SG_ 862 BEM_CRMTimeout00 3;
BA_ "GenSigStartValue" SG_ 862 BEM_CRMTimeoutAA 3;
BA_ "GenSigStartValue" SG_ 862 BEM_CROTimeout 3;
BA_ "GenSigStartValue" SG_ 862 BEM_CSDTimeout 3;
BA_ "GenSigStartValue" SG_ 862 BEM_CSTTimeout 3;
BA_ "GenSigStartValue" SG_ 862 BEM_CTS_CMLTimeout 3;
BA_ "GenSigStartValue" SG_ 862 BEM_Other 3;
BA_ "GenSigStartValue" SG_ 862 BRM_BatteryChargeTimes 16777214;
BA_ "GenSigStartValue" SG_ 862 BRM_BatteryManufacture 4294967294;
BA_ "GenSigStartValue" SG_ 862 BRO_BMSChargeReady 254;
BA_ "GenSigStartValue" SG_ 862 CCS_ChargeAllowed 3;
BA_ "GenSigStartValue" SG_ 862 CCS_OutputCurent 65534;
BA_ "GenSigStartValue" SG_ 862 CCS_OutputVoltage 65534;
BA_ "GenSigStartValue" SG_ 862 CCS_TotalChargeTime 65534;
BA_ "GenSigStartValue" SG_ 862 CEM_BCLTimeout 3;
BA_ "GenSigStartValue" SG_ 862 CEM_BCPTimeout 3;
BA_ "GenSigStartValue" SG_ 862 CEM_BCSTimeout 3;
BA_ "GenSigStartValue" SG_ 862 CEM_BRMTimeout 3;
BA_ "GenSigStartValue" SG_ 862 CEM_BROTimeout 3;
BA_ "GenSigStartValue" SG_ 862 CEM_BSDTimeout 3;
BA_ "GenSigStartValue" SG_ 862 CEM_BSTTimeout 3;
BA_ "GenSigStartValue" SG_ 862 CEM_Other 3;
BA_ "GenSigStartValue" SG_ 862 CHM_ComVersion 16777214;
BA_ "GenSigStartValue" SG_ 862 CML_OutputCurentMax 65534;
BA_ "GenSigStartValue" SG_ 862 CML_OutputCurentMin 65534;
BA_ "GenSigStartValue" SG_ 862 CML_OutputVoltageMax 65534;
BA_ "GenSigStartValue" SG_ 862 CML_OutputVoltageMin 65534;
BA_ "GenSigStartValue" SG_ 862 CRM_ChargeNo 4294967294;
BA_ "GenSigStartValue" SG_ 862 CRM_RecongnitionResult 254;
BA_ "GenSigStartValue" SG_ 862 CRM_RegionCode 16777214;
BA_ "GenSigStartValue" SG_ 862 CRO_ChargeReady 254;
BA_ "GenSigStartValue" SG_ 862 CSD_TotalChrgEnergy 65534;
// Frame: BMS_Fault
BA_ "VFrameFormat" BO_ 1303 14;
BA_ "GenMsgCycleTime" BO_ 1303 500.000;
BA_ "GenMsgStartDelayTime" BO_ 1303 0.000;
// Frame: BMS_GBInfo
BA_ "VFrameFormat" BO_ 1416 14;
BA_ "GenMsgCycleTime" BO_ 1416 1000.000;
BA_ "GenMsgStartDelayTime" BO_ 1416 0.000;
BA_ "GenSigStartValue" SG_ 1416 BMS_BattIGb 65534;
BA_ "GenSigStartValue" SG_ 1416 BMS_BattNrTotGb 254;
BA_ "GenSigStartValue" SG_ 1416 BMS_BattUGb 65534;
BA_ "GenSigStartValue" SG_ 1416 BMS_BattUMaxNrGb 254;
BA_ "GenSigStartValue" SG_ 1416 BMS_BattUMinNrGb 254;
BA_ "GenSigStartValue" SG_ 1416 BMS_CellNrTotGb 65534;
BA_ "GenSigStartValue" SG_ 1416 BMS_CellUMaxGb 65534;
BA_ "GenSigStartValue" SG_ 1416 BMS_CellUMaxNrGb 254;
BA_ "GenSigStartValue" SG_ 1416 BMS_CellUMinGb 65534;
BA_ "GenSigStartValue" SG_ 1416 BMS_CellUMinNrGb 254;
BA_ "GenSigStartValue" SG_ 1416 BMS_ChrgStGb 3;
BA_ "GenSigStartValue" SG_ 1416 BMS_InsulationRGb 65534;
BA_ "GenSigStartValue" SG_ 1416 BMS_ModTMaxGb 254;
BA_ "GenSigStartValue" SG_ 1416 BMS_ModTMaxNrGb 254;
BA_ "GenSigStartValue" SG_ 1416 BMS_ModTMinGb 254;
BA_ "GenSigStartValue" SG_ 1416 BMS_ModTMinNrGb 254;
BA_ "GenSigStartValue" SG_ 1416 BMS_SnsrTMaxNrGb 254;
BA_ "GenSigStartValue" SG_ 1416 BMS_SnsrTMinNrGb 254;
BA_ "GenSigStartValue" SG_ 1416 BMS_SnsrTNrTotGb 65534;
BA_ "GenSigStartValue" SG_ 1416 BMS_SocGb 254;
// Frame: BMS_HVIL_St
BA_ "VFrameFormat" BO_ 1301 14;
BA_ "GenMsgCycleTime" BO_ 1301 200.000;
BA_ "GenMsgStartDelayTime" BO_ 1301 0.000;
BA_ "GenSigStartValue" SG_ 1301 BMS_BattInlT 68;
// Frame: BMS_Measure
BA_ "VFrameFormat" BO_ 260 14;
BA_ "GenMsgCycleTime" BO_ 260 10.000;
BA_ "GenMsgStartDelayTime" BO_ 260 0.000;
BA_ "GenSigStartValue" SG_ 260 BMS_BattCurrt 32766;
BA_ "GenSigStartValue" SG_ 260 BMS_BattCurrtSnsr1 32766;
BA_ "GenSigStartValue" SG_ 260 BMS_BattCurrtSnsr2 32766;
BA_ "GenSigStartValue" SG_ 260 BMS_BattVolt_U1 16382;
BA_ "GenSigStartValue" SG_ 260 BMS_BattVolt_U2 16382;
BA_ "GenSigStartValue" SG_ 260 BMS_BattVolt_U7 16382;
BA_ "GenSigStartValue" SG_ 260 BMS_BattVolt_U8 16382;
BA_ "GenSigStartValue" SG_ 260 BMS_LVBattVolt_KL30 254;
// Frame: BMS_SOX_1
BA_ "VFrameFormat" BO_ 269 14;
BA_ "GenMsgCycleTime" BO_ 269 10.000;
BA_ "GenMsgStartDelayTime" BO_ 269 0.000;
BA_ "GenSigStartValue" SG_ 269 BMS_CurrtLimitCharge 16382;
BA_ "GenSigStartValue" SG_ 269 BMS_CurrtLimitDrive 16382;
BA_ "GenSigStartValue" SG_ 269 BMS_CurrtLimitFeedback 16382;
BA_ "GenSigStartValue" SG_ 269 BMS_PackPwr 32766;
BA_ "GenSigStartValue" SG_ 269 BMS_PackSOCActual 1022;
BA_ "GenSigStartValue" SG_ 269 BMS_PackSOCCalc 1022;
BA_ "GenSigStartValue" SG_ 269 BMS_PackSOCDisp 126;
BA_ "GenSigStartValue" SG_ 269 BMS_PackSOCRange 1022;
BA_ "GenSigStartValue" SG_ 269 BMS_PackSOEActual 262142;
BA_ "GenSigStartValue" SG_ 269 BMS_PackSOEDisp 16382;
BA_ "GenSigStartValue" SG_ 269 BMS_PackSOHDisp 1022;
BA_ "GenSigStartValue" SG_ 269 BMS_PwrLimitCharge 16382;
BA_ "GenSigStartValue" SG_ 269 BMS_PwrLimitDrive 16382;
BA_ "GenSigStartValue" SG_ 269 BMS_PwrLimitFeedback 16382;
// Frame: BMS_SOX_2
BA_ "VFrameFormat" BO_ 528 14;
BA_ "GenMsgCycleTime" BO_ 528 50.000;
BA_ "GenMsgStartDelayTime" BO_ 528 0.000;
BA_ "GenSigStartValue" SG_ 528 BMS_ChrgCurrtContnsMax 16382;
BA_ "GenSigStartValue" SG_ 528 BMS_ChrgCurrtLongTiMax 16382;
BA_ "GenSigStartValue" SG_ 528 BMS_ChrgCurrtShoTiMax 16382;
BA_ "GenSigStartValue" SG_ 528 BMS_ChrgPwrContnsMax 16382;
BA_ "GenSigStartValue" SG_ 528 BMS_ChrgPwrLongTiMax 16382;
BA_ "GenSigStartValue" SG_ 528 BMS_ChrgPwrShoTiMax 16382;
BA_ "GenSigStartValue" SG_ 528 BMS_DchaCurrtContnsMax 16382;
BA_ "GenSigStartValue" SG_ 528 BMS_DchaCurrtLongTiMax 16382;
BA_ "GenSigStartValue" SG_ 528 BMS_DchaCurrtShoTiMax 16382;
BA_ "GenSigStartValue" SG_ 528 BMS_DchaPwrContnsMax 16382;
BA_ "GenSigStartValue" SG_ 528 BMS_DchaPwrLongTiMax 16382;
BA_ "GenSigStartValue" SG_ 528 BMS_DchaPwrShoTiMax 16382;
BA_ "GenSigStartValue" SG_ 528 BMS_PackSOCNotAvrlble 1022;
// Frame: BMS_State
BA_ "VFrameFormat" BO_ 263 14;
BA_ "GenMsgCycleTime" BO_ 263 10.000;
BA_ "GenMsgStartDelayTime" BO_ 263 0.000;
// Frame: BMS_Statistics
BA_ "VFrameFormat" BO_ 1417 14;
BA_ "GenMsgCycleTime" BO_ 1417 1000.000;
BA_ "GenMsgStartDelayTime" BO_ 1417 0.000;
BA_ "GenSigStartValue" SG_ 1417 BMS_ACChrgCpDisp 254;
BA_ "GenSigStartValue" SG_ 1417 BMS_ACChrgEngDisp 254;
BA_ "GenSigStartValue" SG_ 1417 BMS_DCChrgCpDisp 254;
BA_ "GenSigStartValue" SG_ 1417 BMS_DCChrgEngDisp 254;
BA_ "GenSigStartValue" SG_ 1417 BMS_DisChaCpDisp 254;
BA_ "GenSigStartValue" SG_ 1417 BMS_DisChaEngDisp 254;
BA_ "GenSigStartValue" SG_ 1417 BMS_RegenCpDisp 254;
BA_ "GenSigStartValue" SG_ 1417 BMS_RegenEngDisp 254;
BA_ "GenSigStartValue" SG_ 1417 BMS_TotalACChrgCpDisp 4194302;
BA_ "GenSigStartValue" SG_ 1417 BMS_TotalACChrgEngDisp 4194302;
BA_ "GenSigStartValue" SG_ 1417 BMS_TotalDCChrgCpDisp 4194302;
BA_ "GenSigStartValue" SG_ 1417 BMS_TotalDCChrgEngDisp 4194302;
BA_ "GenSigStartValue" SG_ 1417 BMS_TotalDisChaCpDisp 4194302;
BA_ "GenSigStartValue" SG_ 1417 BMS_TotalDisChaEngDisp 4194302;
BA_ "GenSigStartValue" SG_ 1417 BMS_TotalRegenCpDisp 4194302;
BA_ "GenSigStartValue" SG_ 1417 BMS_TotalRegenEngDisp 4194302;
// Frame: BMS_TMSInfo
BA_ "VFrameFormat" BO_ 791 14;
BA_ "GenMsgCycleTime" BO_ 791 100.000;
BA_ "GenMsgStartDelayTime" BO_ 791 0.000;
BA_ "GenSigStartValue" SG_ 791 BMS_BattTempAvg 254;
BA_ "GenSigStartValue" SG_ 791 BMS_BattTempMax 254;
BA_ "GenSigStartValue" SG_ 791 BMS_BattTempMin 254;
BA_ "GenSigStartValue" SG_ 791 BMS_RemThermTiEstimn 254;
BA_ "GenSigStartValue" SG_ 791 BMS_TrgtFlowRate 510;
BA_ "GenSigStartValue" SG_ 791 BMS_TrgtInletTemp 254;
// Frame: BMS_TraceCode
BA_ "VFrameFormat" BO_ 1422 14;
BA_ "GenMsgCycleTime" BO_ 1422 1000.000;
BA_ "GenMsgStartDelayTime" BO_ 1422 0.000;

VAL_ 287 ABM_CrashTyp 0 "ABM_CrashTyp_0_Initial_No_Crash" 1 "ABM_CrashTyp_1_Front_crash" 2 "ABM_CrashTyp_2_Side_crash" 3 "ABM_CrashTyp_3_Front+side_crash" 4 "ABM_CrashTyp_4_Rear_crash" 5 "ABM_CrashTyp_5_Front+rear_crash" 6 "ABM_CrashTyp_6_Side+rear_crash" 7 "ABM_CrashTyp_7_Front+side+rear_crash" 8 "ABM_CrashTyp_8_Rollover_crash" 9 "ABM_CrashTyp_9_Rollover+front_crash" 10 "ABM_CrashTyp_10_Rollover+side_crash" 11 "ABM_CrashTyp_11_Rollover+side+front_crash" 12 "ABM_CrashTyp_12_Rollover+rear_crash" 13 "ABM_CrashTyp_13_Rollover+rear+front_crash" 14 "ABM_CrashTyp_14_Rollover+rear+side_crash" 15 "ABM_CrashTyp_15_Rollover+rear+side+front_crash" 16 "ABM_CrashTyp_16_Reserved";
VAL_ 287 ABM_IMU_LateralAcceleration 16383 "ABM_IMU_LateralAcceleration_16363_Invalid";
VAL_ 287 ABM_IMU_LateralAccValid 0 "ABM_IMU_LateralAccValid_0_Invalid" 1 "ABM_IMU_LateralAccValid_1_Valid";
VAL_ 287 ABM_IMU_LongAcceleration 16383 "ABM_IMU_LongAcceleration_16383_Invalid";
VAL_ 287 ABM_IMU_LongAccelerationValid 0 "ABM_IMU_LongAccelerationValid_0_Invalid" 1 "ABM_IMU_LongAccelerationValid_1_Valid";
VAL_ 287 ABM_IMU_Rollrate 65535 "ABM_IMU_Rollrate_16383_Invalid";
VAL_ 287 ABM_IMU_RollrateSigVld 0 "ABM_IMU_RollrateSigVld_0_Invalid" 1 "ABM_IMU_RollrateSigVld_1_Valid";
VAL_ 287 ABM_IMU_VertA 16383 "ABM_IMU_VertA_16383_Invalid";
VAL_ 287 ABM_IMU_VertASigVld 0 "ABM_IMU_VertASigVld_0_Invalid" 1 "ABM_IMU_VertASigVld_1_Valid";
VAL_ 287 ABM_IMU_YawRate 65535 "ABM_IMU_YawRate_16383_Invalid";
VAL_ 287 ABM_IMU_YawRateValid 0 "ABM_IMU_YawRateValid_0_Invalid" 1 "ABM_IMU_YawRateValid_1_Valid";
VAL_ 287 ABM_IMU_YrsCalibStatus 0 "ABM_IMU_YrsCalibStatus_0_Calibration_Finished_Error/_Not_in_Calibrating" 1 "ABM_IMU_YrsCalibStatus_1_Calibration_Finished_Success";
VAL_ 287 ABM_WarningLampStatus 0 "ABM_WarningLampStatus_0_OFF" 1 "ABM_WarningLampStatus_1_ON" 2 "ABM_WarningLampStatus_2_Flash" 3 "ABM_WarningLampStatus_3_Invalid";
VAL_ 810 ADS_CalSt 0 "ADS_CalSt_0_no_request" 1 "ADS_CalSt_1_off" 2 "ADS_CalSt_2_on" 3 "ADS_CalSt_3_reserved" 4 "ADS_CalSt_4_reserved" 5 "ADS_CalSt_5_reserved" 6 "ADS_CalSt_6_reserved" 31 "ADS_CalSt_31_invalid";
VAL_ 810 ADS_FctSts 0 "ADS_FctSts_0_Off" 1 "ADS_FctSts_1_On";
VAL_ 810 ADS_FlowReq 0 "ADS_FlowReq_0_0.0L/min" 1 "ADS_FlowReq_1_0.25L/min" 2 "ADS_FlowReq_2_0.5L/min" 3 "ADS_FlowReq_3_0.75L/min" 4 "ADS_FlowReq_4_1.0L/min" 5 "ADS_FlowReq_5_1.25L/min" 6 "ADS_FlowReq_6_1.5L/min" 7 "ADS_FlowReq_7_1.75L/min" 8 "ADS_FlowReq_8_2.0L/min" 9 "ADS_FlowReq_9_2.25L/min" 10 "ADS_FlowReq_10_2.5L/min" 11 "ADS_FlowReq_11_2.75L/min" 12 "ADS_FlowReq_12_3.0L/min" 13 "ADS_FlowReq_13_3.25L/min" 14 "ADS_FlowReq_14_3.5L/min";
VAL_ 810 ADS_ForcedHiBeamCtrl 0 "ADS_ForcedHiBeamCtrl_0_No_request" 1 "ADS_ForcedHiBeamCtrl_1_OFF" 2 "ADS_ForcedHiBeamCtrl_2_ON" 3 "ADS_ForcedHiBeamCtrl_3_Reserved";
VAL_ 810 ADS_HVCtrlReq 0 "ADS_HVCtrlReq_0_No_Request" 1 "ADS_HVCtrlReq_1_Request";
VAL_ 810 ADS_HzrdLampReq 0 "ADS_HzrdLampReq_0_No_request" 1 "ADS_HzrdLampReq_1_OFF" 2 "ADS_HzrdLampReq_2_ON";
VAL_ 810 ADS_MdcCrtSts 0 "ADS_MdcCrtSts_0_DeepSleep深度睡眠状态" 1 "ADS_MdcCrtSts_1_LightSleep浅睡眠状态" 2 "ADS_MdcCrtSts_2_Active激活状态" 3 "ADS_MdcCrtSts_3_PartialActive半激活状态" 4 "ADS_MdcCrtSts_4_Reserve" 7 "ADS_MdcCrtSts_7_Invalid";
VAL_ 810 ADS_PwrOnOffReq 0 "ADS_PwrOnOffReq_0_None" 1 "ADS_PwrOnOffReq_1_Power_on_上电&Ready" 2 "ADS_PwrOnOffReq_2_Power_off_下电&锁车" 3 "ADS_PwrOnOffReq_3_上Ready" 4 "ADS_PwrOnOffReq_4_下Ready(维持高压)" 5 "ADS_PwrOnOffReq_5_上ready_searchkey" 6 "LogicalValue_6_Reserved";
VAL_ 810 ADS_RcwWarningReq 0 "ADS_RcwWarningReq_0_No_request" 1 "ADS_RcwWarningReq_1_OFF" 2 "ADS_RcwWarningReq_2_ON";
VAL_ 810 ADS_RDAHzrdLampCtrl 0 "ADS_RDAHzrdLampCtrl_0_No_request" 1 "ADS_RDAHzrdLampCtrl_1_ON" 2 "ADS_RDAHzrdLampCtrl_2_Reserved";
VAL_ 810 ADS_SilentCoolgMod 0 "ADS_SilentCoolgMod_0_Initial" 1 "ADS_SilentCoolgMod_1_ON" 2 "ADS_SilentCoolgMod_2_OFF" 3 "ADS_SilentCoolgMod_3_Reserved";
VAL_ 810 ADS_SuspensionStatus 0 "ADS_SuspensionStatus_0_No_request" 1 "ADS_SuspensionStatus_1_Auto_Disable" 2 "ADS_SuspensionStatus_2_Manual_Disable" 3 "ADS_SuspensionStatus_3_Disable" 4 "ADS_SuspensionStatus_4_Standard_Height" 5 "ADS_SuspensionStatus_5_Reserved";
VAL_ 810 ADS_ThmPostRun 0 "ADS_ThmPostRun_0_No_request" 1 "ADS_ThmPostRun_1_Request" 2 "ADS_ThmPostRun_2_reserved" 3 "ADS_ThmPostRun_3_Invalid";
VAL_ 810 ADS_TurnLampReq 0 "ADS_TurnLampReq_0_No_request" 1 "ADS_TurnLampReq_1_OFF" 2 "ADS_TurnLampReq_2_LeTurnOn" 3 "ADS_TurnLampReq_3_RiTurnOn";
VAL_ 810 MDC_FuncReq_SentryModDetec 0 "MDC_FuncReq_SentryModDetec_0_Inactive" 1 "MDC_FuncReq_SentryModDetec_1_Active";
VAL_ 810 MDC_FuncReq_SentryModWarn 0 "MDC_FuncReq_SentryModWarn_0_Inactive" 1 "MDC_FuncReq_SentryModWarn_1_Active";
VAL_ 810 MDC_PrivacyModeSts 0 "MDC_PrivacyModeSts_0_Initial" 1 "MDC_PrivacyModeSts_1_OFF" 2 "MDC_PrivacyModeSts_2_ON" 3 "MDC_PrivacyModeSts_3_Invalid";
VAL_ 1415 BMS_BattEquilnSts 0 "BMS_BattEquilnSts_0_NO" 1 "BMS_BattEquilnSts_1_YES";
VAL_ 1415 BMS_CellEquilnSts1 0 "BMS_CellEquilnSts1_0_NO" 1 "BMS_CellEquilnSts1_1_YES";
VAL_ 1415 BMS_CellEquilnSts10 0 "BMS_CellEquilnSts10_0_NO" 1 "BMS_CellEquilnSts10_1_YES";
VAL_ 1415 BMS_CellEquilnSts100 0 "BMS_CellEquilnSts100_0_NO" 1 "BMS_CellEquilnSts100_1_YES";
VAL_ 1415 BMS_CellEquilnSts101 0 "BMS_CellEquilnSts101_0_NO" 1 "BMS_CellEquilnSts101_1_YES";
VAL_ 1415 BMS_CellEquilnSts102 0 "BMS_CellEquilnSts102_0_NO" 1 "BMS_CellEquilnSts102_1_YES";
VAL_ 1415 BMS_CellEquilnSts103 0 "BMS_CellEquilnSts103_0_NO" 1 "BMS_CellEquilnSts103_1_YES";
VAL_ 1415 BMS_CellEquilnSts104 0 "BMS_CellEquilnSts104_0_NO" 1 "BMS_CellEquilnSts104_1_YES";
VAL_ 1415 BMS_CellEquilnSts105 0 "BMS_CellEquilnSts105_0_NO" 1 "BMS_CellEquilnSts105_1_YES";
VAL_ 1415 BMS_CellEquilnSts106 0 "BMS_CellEquilnSts106_0_NO" 1 "BMS_CellEquilnSts106_1_YES";
VAL_ 1415 BMS_CellEquilnSts107 0 "BMS_CellEquilnSts107_0_NO" 1 "BMS_CellEquilnSts107_1_YES";
VAL_ 1415 BMS_CellEquilnSts108 0 "BMS_CellEquilnSts108_0_NO" 1 "BMS_CellEquilnSts108_1_YES";
VAL_ 1415 BMS_CellEquilnSts109 0 "BMS_CellEquilnSts109_0_NO" 1 "BMS_CellEquilnSts109_1_YES";
VAL_ 1415 BMS_CellEquilnSts11 0 "BMS_CellEquilnSts11_0_NO" 1 "BMS_CellEquilnSts11_1_YES";
VAL_ 1415 BMS_CellEquilnSts110 0 "BMS_CellEquilnSts110_0_NO" 1 "BMS_CellEquilnSts110_1_YES";
VAL_ 1415 BMS_CellEquilnSts111 0 "BMS_CellEquilnSts111_0_NO" 1 "BMS_CellEquilnSts111_1_YES";
VAL_ 1415 BMS_CellEquilnSts112 0 "BMS_CellEquilnSts112_0_NO" 1 "BMS_CellEquilnSts112_1_YES";
VAL_ 1415 BMS_CellEquilnSts113 0 "BMS_CellEquilnSts113_0_NO" 1 "BMS_CellEquilnSts113_1_YES";
VAL_ 1415 BMS_CellEquilnSts114 0 "BMS_CellEquilnSts114_0_NO" 1 "BMS_CellEquilnSts114_1_YES";
VAL_ 1415 BMS_CellEquilnSts115 0 "BMS_CellEquilnSts115_0_NO" 1 "BMS_CellEquilnSts115_1_YES";
VAL_ 1415 BMS_CellEquilnSts116 0 "BMS_CellEquilnSts116_0_NO" 1 "BMS_CellEquilnSts116_1_YES";
VAL_ 1415 BMS_CellEquilnSts117 0 "BMS_CellEquilnSts117_0_NO" 1 "BMS_CellEquilnSts117_1_YES";
VAL_ 1415 BMS_CellEquilnSts118 0 "BMS_CellEquilnSts118_0_NO" 1 "BMS_CellEquilnSts118_1_YES";
VAL_ 1415 BMS_CellEquilnSts119 0 "BMS_CellEquilnSts119_0_NO" 1 "BMS_CellEquilnSts119_1_YES";
VAL_ 1415 BMS_CellEquilnSts12 0 "BMS_CellEquilnSts12_0_NO" 1 "BMS_CellEquilnSts12_1_YES";
VAL_ 1415 BMS_CellEquilnSts120 0 "BMS_CellEquilnSts120_0_NO" 1 "BMS_CellEquilnSts120_1_YES";
VAL_ 1415 BMS_CellEquilnSts121 0 "BMS_CellEquilnSts121_0_NO" 1 "BMS_CellEquilnSts121_1_YES";
VAL_ 1415 BMS_CellEquilnSts122 0 "BMS_CellEquilnSts122_0_NO" 1 "BMS_CellEquilnSts122_1_YES";
VAL_ 1415 BMS_CellEquilnSts123 0 "BMS_CellEquilnSts123_0_NO" 1 "BMS_CellEquilnSts123_1_YES";
VAL_ 1415 BMS_CellEquilnSts124 0 "BMS_CellEquilnSts124_0_NO" 1 "BMS_CellEquilnSts124_1_YES";
VAL_ 1415 BMS_CellEquilnSts125 0 "BMS_CellEquilnSts125_0_NO" 1 "BMS_CellEquilnSts125_1_YES";
VAL_ 1415 BMS_CellEquilnSts126 0 "BMS_CellEquilnSts126_0_NO" 1 "BMS_CellEquilnSts126_1_YES";
VAL_ 1415 BMS_CellEquilnSts127 0 "BMS_CellEquilnSts127_0_NO" 1 "BMS_CellEquilnSts127_1_YES";
VAL_ 1415 BMS_CellEquilnSts128 0 "BMS_CellEquilnSts128_0_NO" 1 "BMS_CellEquilnSts128_1_YES";
VAL_ 1415 BMS_CellEquilnSts129 0 "BMS_CellEquilnSts129_0_NO" 1 "BMS_CellEquilnSts129_1_YES";
VAL_ 1415 BMS_CellEquilnSts13 0 "BMS_CellEquilnSts13_0_NO" 1 "BMS_CellEquilnSts13_1_YES";
VAL_ 1415 BMS_CellEquilnSts130 0 "BMS_CellEquilnSts130_0_NO" 1 "BMS_CellEquilnSts130_1_YES";
VAL_ 1415 BMS_CellEquilnSts131 0 "BMS_CellEquilnSts131_0_NO" 1 "BMS_CellEquilnSts131_1_YES";
VAL_ 1415 BMS_CellEquilnSts132 0 "BMS_CellEquilnSts132_0_NO" 1 "BMS_CellEquilnSts132_1_YES";
VAL_ 1415 BMS_CellEquilnSts133 0 "BMS_CellEquilnSts133_0_NO" 1 "BMS_CellEquilnSts133_1_YES";
VAL_ 1415 BMS_CellEquilnSts134 0 "BMS_CellEquilnSts134_0_NO" 1 "BMS_CellEquilnSts134_1_YES";
VAL_ 1415 BMS_CellEquilnSts135 0 "BMS_CellEquilnSts135_0_NO" 1 "BMS_CellEquilnSts135_1_YES";
VAL_ 1415 BMS_CellEquilnSts136 0 "BMS_CellEquilnSts136_0_NO" 1 "BMS_CellEquilnSts136_1_YES";
VAL_ 1415 BMS_CellEquilnSts137 0 "BMS_CellEquilnSts137_0_NO" 1 "BMS_CellEquilnSts137_1_YES";
VAL_ 1415 BMS_CellEquilnSts138 0 "BMS_CellEquilnSts138_0_NO" 1 "BMS_CellEquilnSts138_1_YES";
VAL_ 1415 BMS_CellEquilnSts139 0 "BMS_CellEquilnSts139_0_NO" 1 "BMS_CellEquilnSts139_1_YES";
VAL_ 1415 BMS_CellEquilnSts14 0 "BMS_CellEquilnSts14_0_NO" 1 "BMS_CellEquilnSts14_1_YES";
VAL_ 1415 BMS_CellEquilnSts140 0 "BMS_CellEquilnSts140_0_NO" 1 "BMS_CellEquilnSts140_1_YES";
VAL_ 1415 BMS_CellEquilnSts141 0 "BMS_CellEquilnSts141_0_NO" 1 "BMS_CellEquilnSts141_1_YES";
VAL_ 1415 BMS_CellEquilnSts142 0 "BMS_CellEquilnSts142_0_NO" 1 "BMS_CellEquilnSts142_1_YES";
VAL_ 1415 BMS_CellEquilnSts143 0 "BMS_CellEquilnSts143_0_NO" 1 "BMS_CellEquilnSts143_1_YES";
VAL_ 1415 BMS_CellEquilnSts144 0 "BMS_CellEquilnSts144_0_NO" 1 "BMS_CellEquilnSts144_1_YES";
VAL_ 1415 BMS_CellEquilnSts145 0 "BMS_CellEquilnSts145_0_NO" 1 "BMS_CellEquilnSts145_1_YES";
VAL_ 1415 BMS_CellEquilnSts146 0 "BMS_CellEquilnSts146_0_NO" 1 "BMS_CellEquilnSts146_1_YES";
VAL_ 1415 BMS_CellEquilnSts147 0 "BMS_CellEquilnSts147_0_NO" 1 "BMS_CellEquilnSts147_1_YES";
VAL_ 1415 BMS_CellEquilnSts148 0 "BMS_CellEquilnSts148_0_NO" 1 "BMS_CellEquilnSts148_1_YES";
VAL_ 1415 BMS_CellEquilnSts149 0 "BMS_CellEquilnSts149_0_NO" 1 "BMS_CellEquilnSts149_1_YES";
VAL_ 1415 BMS_CellEquilnSts15 0 "BMS_CellEquilnSts15_0_NO" 1 "BMS_CellEquilnSts15_1_YES";
VAL_ 1415 BMS_CellEquilnSts150 0 "BMS_CellEquilnSts150_0_NO" 1 "BMS_CellEquilnSts150_1_YES";
VAL_ 1415 BMS_CellEquilnSts151 0 "BMS_CellEquilnSts151_0_NO" 1 "BMS_CellEquilnSts151_1_YES";
VAL_ 1415 BMS_CellEquilnSts152 0 "BMS_CellEquilnSts152_0_NO" 1 "BMS_CellEquilnSts152_1_YES";
VAL_ 1415 BMS_CellEquilnSts153 0 "BMS_CellEquilnSts153_0_NO" 1 "BMS_CellEquilnSts153_1_YES";
VAL_ 1415 BMS_CellEquilnSts154 0 "BMS_CellEquilnSts154_0_NO" 1 "BMS_CellEquilnSts154_1_YES";
VAL_ 1415 BMS_CellEquilnSts155 0 "BMS_CellEquilnSts155_0_NO" 1 "BMS_CellEquilnSts155_1_YES";
VAL_ 1415 BMS_CellEquilnSts156 0 "BMS_CellEquilnSts156_0_NO" 1 "BMS_CellEquilnSts156_1_YES";
VAL_ 1415 BMS_CellEquilnSts157 0 "BMS_CellEquilnSts157_0_NO" 1 "BMS_CellEquilnSts157_1_YES";
VAL_ 1415 BMS_CellEquilnSts158 0 "BMS_CellEquilnSts158_0_NO" 1 "BMS_CellEquilnSts158_1_YES";
VAL_ 1415 BMS_CellEquilnSts159 0 "BMS_CellEquilnSts159_0_NO" 1 "BMS_CellEquilnSts159_1_YES";
VAL_ 1415 BMS_CellEquilnSts16 0 "BMS_CellEquilnSts16_0_NO" 1 "BMS_CellEquilnSts16_1_YES";
VAL_ 1415 BMS_CellEquilnSts160 0 "BMS_CellEquilnSts160_0_NO" 1 "BMS_CellEquilnSts160_1_YES";
VAL_ 1415 BMS_CellEquilnSts161 0 "BMS_CellEquilnSts161_0_NO" 1 "BMS_CellEquilnSts161_1_YES";
VAL_ 1415 BMS_CellEquilnSts162 0 "BMS_CellEquilnSts162_0_NO" 1 "BMS_CellEquilnSts162_1_YES";
VAL_ 1415 BMS_CellEquilnSts163 0 "BMS_CellEquilnSts163_0_NO" 1 "BMS_CellEquilnSts163_1_YES";
VAL_ 1415 BMS_CellEquilnSts164 0 "BMS_CellEquilnSts164_0_NO" 1 "BMS_CellEquilnSts164_1_YES";
VAL_ 1415 BMS_CellEquilnSts165 0 "BMS_CellEquilnSts165_0_NO" 1 "BMS_CellEquilnSts165_1_YES";
VAL_ 1415 BMS_CellEquilnSts166 0 "BMS_CellEquilnSts166_0_NO" 1 "BMS_CellEquilnSts166_1_YES";
VAL_ 1415 BMS_CellEquilnSts167 0 "BMS_CellEquilnSts167_0_NO" 1 "BMS_CellEquilnSts167_1_YES";
VAL_ 1415 BMS_CellEquilnSts168 0 "BMS_CellEquilnSts168_0_NO" 1 "BMS_CellEquilnSts168_1_YES";
VAL_ 1415 BMS_CellEquilnSts169 0 "BMS_CellEquilnSts169_0_NO" 1 "BMS_CellEquilnSts169_1_YES";
VAL_ 1415 BMS_CellEquilnSts17 0 "BMS_CellEquilnSts17_0_NO" 1 "BMS_CellEquilnSts17_1_YES";
VAL_ 1415 BMS_CellEquilnSts170 0 "BMS_CellEquilnSts170_0_NO" 1 "BMS_CellEquilnSts170_1_YES";
VAL_ 1415 BMS_CellEquilnSts171 0 "BMS_CellEquilnSts171_0_NO" 1 "BMS_CellEquilnSts171_1_YES";
VAL_ 1415 BMS_CellEquilnSts172 0 "BMS_CellEquilnSts172_0_NO" 1 "BMS_CellEquilnSts172_1_YES";
VAL_ 1415 BMS_CellEquilnSts173 0 "BMS_CellEquilnSts173_0_NO" 1 "BMS_CellEquilnSts173_1_YES";
VAL_ 1415 BMS_CellEquilnSts174 0 "BMS_CellEquilnSts174_0_NO" 1 "BMS_CellEquilnSts174_1_YES";
VAL_ 1415 BMS_CellEquilnSts175 0 "BMS_CellEquilnSts175_0_NO" 1 "BMS_CellEquilnSts175_1_YES";
VAL_ 1415 BMS_CellEquilnSts176 0 "BMS_CellEquilnSts176_0_NO" 1 "BMS_CellEquilnSts176_1_YES";
VAL_ 1415 BMS_CellEquilnSts177 0 "BMS_CellEquilnSts177_0_NO" 1 "BMS_CellEquilnSts177_1_YES";
VAL_ 1415 BMS_CellEquilnSts178 0 "BMS_CellEquilnSts178_0_NO" 1 "BMS_CellEquilnSts178_1_YES";
VAL_ 1415 BMS_CellEquilnSts179 0 "BMS_CellEquilnSts179_0_NO" 1 "BMS_CellEquilnSts179_1_YES";
VAL_ 1415 BMS_CellEquilnSts18 0 "BMS_CellEquilnSts18_0_NO" 1 "BMS_CellEquilnSts18_1_YES";
VAL_ 1415 BMS_CellEquilnSts180 0 "BMS_CellEquilnSts180_0_NO" 1 "BMS_CellEquilnSts180_1_YES";
VAL_ 1415 BMS_CellEquilnSts181 0 "BMS_CellEquilnSts181_0_NO" 1 "BMS_CellEquilnSts181_1_YES";
VAL_ 1415 BMS_CellEquilnSts182 0 "BMS_CellEquilnSts182_0_NO" 1 "BMS_CellEquilnSts182_1_YES";
VAL_ 1415 BMS_CellEquilnSts183 0 "BMS_CellEquilnSts183_0_NO" 1 "BMS_CellEquilnSts183_1_YES";
VAL_ 1415 BMS_CellEquilnSts184 0 "BMS_CellEquilnSts184_0_NO" 1 "BMS_CellEquilnSts184_1_YES";
VAL_ 1415 BMS_CellEquilnSts185 0 "BMS_CellEquilnSts185_0_NO" 1 "BMS_CellEquilnSts185_1_YES";
VAL_ 1415 BMS_CellEquilnSts186 0 "BMS_CellEquilnSts186_0_NO" 1 "BMS_CellEquilnSts186_1_YES";
VAL_ 1415 BMS_CellEquilnSts187 0 "BMS_CellEquilnSts187_0_NO" 1 "BMS_CellEquilnSts187_1_YES";
VAL_ 1415 BMS_CellEquilnSts188 0 "BMS_CellEquilnSts188_0_NO" 1 "BMS_CellEquilnSts188_1_YES";
VAL_ 1415 BMS_CellEquilnSts189 0 "BMS_CellEquilnSts189_0_NO" 1 "BMS_CellEquilnSts189_1_YES";
VAL_ 1415 BMS_CellEquilnSts19 0 "BMS_CellEquilnSts19_0_NO" 1 "BMS_CellEquilnSts19_1_YES";
VAL_ 1415 BMS_CellEquilnSts190 0 "BMS_CellEquilnSts190_0_NO" 1 "BMS_CellEquilnSts190_1_YES";
VAL_ 1415 BMS_CellEquilnSts191 0 "BMS_CellEquilnSts191_0_NO" 1 "BMS_CellEquilnSts191_1_YES";
VAL_ 1415 BMS_CellEquilnSts192 0 "BMS_CellEquilnSts192_0_NO" 1 "BMS_CellEquilnSts192_1_YES";
VAL_ 1415 BMS_CellEquilnSts2 0 "BMS_CellEquilnSts2_0_NO" 1 "BMS_CellEquilnSts2_1_YES";
VAL_ 1415 BMS_CellEquilnSts20 0 "BMS_CellEquilnSts20_0_NO" 1 "BMS_CellEquilnSts20_1_YES";
VAL_ 1415 BMS_CellEquilnSts21 0 "BMS_CellEquilnSts21_0_NO" 1 "BMS_CellEquilnSts21_1_YES";
VAL_ 1415 BMS_CellEquilnSts22 0 "BMS_CellEquilnSts22_0_NO" 1 "BMS_CellEquilnSts22_1_YES";
VAL_ 1415 BMS_CellEquilnSts23 0 "BMS_CellEquilnSts23_0_NO" 1 "BMS_CellEquilnSts23_1_YES";
VAL_ 1415 BMS_CellEquilnSts24 0 "BMS_CellEquilnSts24_0_NO" 1 "BMS_CellEquilnSts24_1_YES";
VAL_ 1415 BMS_CellEquilnSts25 0 "BMS_CellEquilnSts25_0_NO" 1 "BMS_CellEquilnSts25_1_YES";
VAL_ 1415 BMS_CellEquilnSts26 0 "BMS_CellEquilnSts26_0_NO" 1 "BMS_CellEquilnSts26_1_YES";
VAL_ 1415 BMS_CellEquilnSts27 0 "BMS_CellEquilnSts27_0_NO" 1 "BMS_CellEquilnSts27_1_YES";
VAL_ 1415 BMS_CellEquilnSts28 0 "BMS_CellEquilnSts28_0_NO" 1 "BMS_CellEquilnSts28_1_YES";
VAL_ 1415 BMS_CellEquilnSts29 0 "BMS_CellEquilnSts29_0_NO" 1 "BMS_CellEquilnSts29_1_YES";
VAL_ 1415 BMS_CellEquilnSts3 0 "BMS_CellEquilnSts3_0_NO" 1 "BMS_CellEquilnSts3_1_YES";
VAL_ 1415 BMS_CellEquilnSts30 0 "BMS_CellEquilnSts30_0_NO" 1 "BMS_CellEquilnSts30_1_YES";
VAL_ 1415 BMS_CellEquilnSts31 0 "BMS_CellEquilnSts31_0_NO" 1 "BMS_CellEquilnSts31_1_YES";
VAL_ 1415 BMS_CellEquilnSts32 0 "BMS_CellEquilnSts32_0_NO" 1 "BMS_CellEquilnSts32_1_YES";
VAL_ 1415 BMS_CellEquilnSts33 0 "BMS_CellEquilnSts33_0_NO" 1 "BMS_CellEquilnSts33_1_YES";
VAL_ 1415 BMS_CellEquilnSts34 0 "BMS_CellEquilnSts34_0_NO" 1 "BMS_CellEquilnSts34_1_YES";
VAL_ 1415 BMS_CellEquilnSts35 0 "BMS_CellEquilnSts35_0_NO" 1 "BMS_CellEquilnSts35_1_YES";
VAL_ 1415 BMS_CellEquilnSts36 0 "BMS_CellEquilnSts36_0_NO" 1 "BMS_CellEquilnSts36_1_YES";
VAL_ 1415 BMS_CellEquilnSts37 0 "BMS_CellEquilnSts37_0_NO" 1 "BMS_CellEquilnSts37_1_YES";
VAL_ 1415 BMS_CellEquilnSts38 0 "BMS_CellEquilnSts38_0_NO" 1 "BMS_CellEquilnSts38_1_YES";
VAL_ 1415 BMS_CellEquilnSts39 0 "BMS_CellEquilnSts39_0_NO" 1 "BMS_CellEquilnSts39_1_YES";
VAL_ 1415 BMS_CellEquilnSts4 0 "BMS_CellEquilnSts4_0_NO" 1 "BMS_CellEquilnSts4_1_YES";
VAL_ 1415 BMS_CellEquilnSts40 0 "BMS_CellEquilnSts40_0_NO" 1 "BMS_CellEquilnSts40_1_YES";
VAL_ 1415 BMS_CellEquilnSts41 0 "BMS_CellEquilnSts41_0_NO" 1 "BMS_CellEquilnSts41_1_YES";
VAL_ 1415 BMS_CellEquilnSts42 0 "BMS_CellEquilnSts42_0_NO" 1 "BMS_CellEquilnSts42_1_YES";
VAL_ 1415 BMS_CellEquilnSts43 0 "BMS_CellEquilnSts43_0_NO" 1 "BMS_CellEquilnSts43_1_YES";
VAL_ 1415 BMS_CellEquilnSts44 0 "BMS_CellEquilnSts44_0_NO" 1 "BMS_CellEquilnSts44_1_YES";
VAL_ 1415 BMS_CellEquilnSts45 0 "BMS_CellEquilnSts45_0_NO" 1 "BMS_CellEquilnSts45_1_YES";
VAL_ 1415 BMS_CellEquilnSts46 0 "BMS_CellEquilnSts46_0_NO" 1 "BMS_CellEquilnSts46_1_YES";
VAL_ 1415 BMS_CellEquilnSts47 0 "BMS_CellEquilnSts47_0_NO" 1 "BMS_CellEquilnSts47_1_YES";
VAL_ 1415 BMS_CellEquilnSts48 0 "BMS_CellEquilnSts48_0_NO" 1 "BMS_CellEquilnSts48_1_YES";
VAL_ 1415 BMS_CellEquilnSts49 0 "BMS_CellEquilnSts49_0_NO" 1 "BMS_CellEquilnSts49_1_YES";
VAL_ 1415 BMS_CellEquilnSts5 0 "BMS_CellEquilnSts5_0_NO" 1 "BMS_CellEquilnSts5_1_YES";
VAL_ 1415 BMS_CellEquilnSts50 0 "BMS_CellEquilnSts50_0_NO" 1 "BMS_CellEquilnSts50_1_YES";
VAL_ 1415 BMS_CellEquilnSts51 0 "BMS_CellEquilnSts51_0_NO" 1 "BMS_CellEquilnSts51_1_YES";
VAL_ 1415 BMS_CellEquilnSts52 0 "BMS_CellEquilnSts52_0_NO" 1 "BMS_CellEquilnSts52_1_YES";
VAL_ 1415 BMS_CellEquilnSts53 0 "BMS_CellEquilnSts53_0_NO" 1 "BMS_CellEquilnSts53_1_YES";
VAL_ 1415 BMS_CellEquilnSts54 0 "BMS_CellEquilnSts54_0_NO" 1 "BMS_CellEquilnSts54_1_YES";
VAL_ 1415 BMS_CellEquilnSts55 0 "BMS_CellEquilnSts55_0_NO" 1 "BMS_CellEquilnSts55_1_YES";
VAL_ 1415 BMS_CellEquilnSts56 0 "BMS_CellEquilnSts56_0_NO" 1 "BMS_CellEquilnSts56_1_YES";
VAL_ 1415 BMS_CellEquilnSts57 0 "BMS_CellEquilnSts57_0_NO" 1 "BMS_CellEquilnSts57_1_YES";
VAL_ 1415 BMS_CellEquilnSts58 0 "BMS_CellEquilnSts58_0_NO" 1 "BMS_CellEquilnSts58_1_YES";
VAL_ 1415 BMS_CellEquilnSts59 0 "BMS_CellEquilnSts59_0_NO" 1 "BMS_CellEquilnSts59_1_YES";
VAL_ 1415 BMS_CellEquilnSts6 0 "BMS_CellEquilnSts6_0_NO" 1 "BMS_CellEquilnSts6_1_YES";
VAL_ 1415 BMS_CellEquilnSts60 0 "BMS_CellEquilnSts60_0_NO" 1 "BMS_CellEquilnSts60_1_YES";
VAL_ 1415 BMS_CellEquilnSts61 0 "BMS_CellEquilnSts61_0_NO" 1 "BMS_CellEquilnSts61_1_YES";
VAL_ 1415 BMS_CellEquilnSts62 0 "BMS_CellEquilnSts62_0_NO" 1 "BMS_CellEquilnSts62_1_YES";
VAL_ 1415 BMS_CellEquilnSts63 0 "BMS_CellEquilnSts63_0_NO" 1 "BMS_CellEquilnSts63_1_YES";
VAL_ 1415 BMS_CellEquilnSts64 0 "BMS_CellEquilnSts64_0_NO" 1 "BMS_CellEquilnSts64_1_YES";
VAL_ 1415 BMS_CellEquilnSts65 0 "BMS_CellEquilnSts65_0_NO" 1 "BMS_CellEquilnSts65_1_YES";
VAL_ 1415 BMS_CellEquilnSts66 0 "BMS_CellEquilnSts66_0_NO" 1 "BMS_CellEquilnSts66_1_YES";
VAL_ 1415 BMS_CellEquilnSts67 0 "BMS_CellEquilnSts67_0_NO" 1 "BMS_CellEquilnSts67_1_YES";
VAL_ 1415 BMS_CellEquilnSts68 0 "BMS_CellEquilnSts68_0_NO" 1 "BMS_CellEquilnSts68_1_YES";
VAL_ 1415 BMS_CellEquilnSts69 0 "BMS_CellEquilnSts69_0_NO" 1 "BMS_CellEquilnSts69_1_YES";
VAL_ 1415 BMS_CellEquilnSts7 0 "BMS_CellEquilnSts7_0_NO" 1 "BMS_CellEquilnSts7_1_YES";
VAL_ 1415 BMS_CellEquilnSts70 0 "BMS_CellEquilnSts70_0_NO" 1 "BMS_CellEquilnSts70_1_YES";
VAL_ 1415 BMS_CellEquilnSts71 0 "BMS_CellEquilnSts71_0_NO" 1 "BMS_CellEquilnSts71_1_YES";
VAL_ 1415 BMS_CellEquilnSts72 0 "BMS_CellEquilnSts72_0_NO" 1 "BMS_CellEquilnSts72_1_YES";
VAL_ 1415 BMS_CellEquilnSts73 0 "BMS_CellEquilnSts73_0_NO" 1 "BMS_CellEquilnSts73_1_YES";
VAL_ 1415 BMS_CellEquilnSts74 0 "BMS_CellEquilnSts74_0_NO" 1 "BMS_CellEquilnSts74_1_YES";
VAL_ 1415 BMS_CellEquilnSts75 0 "BMS_CellEquilnSts75_0_NO" 1 "BMS_CellEquilnSts75_1_YES";
VAL_ 1415 BMS_CellEquilnSts76 0 "BMS_CellEquilnSts76_0_NO" 1 "BMS_CellEquilnSts76_1_YES";
VAL_ 1415 BMS_CellEquilnSts77 0 "BMS_CellEquilnSts77_0_NO" 1 "BMS_CellEquilnSts77_1_YES";
VAL_ 1415 BMS_CellEquilnSts78 0 "BMS_CellEquilnSts78_0_NO" 1 "BMS_CellEquilnSts78_1_YES";
VAL_ 1415 BMS_CellEquilnSts79 0 "BMS_CellEquilnSts79_0_NO" 1 "BMS_CellEquilnSts79_1_YES";
VAL_ 1415 BMS_CellEquilnSts8 0 "BMS_CellEquilnSts8_0_NO" 1 "BMS_CellEquilnSts8_1_YES";
VAL_ 1415 BMS_CellEquilnSts80 0 "BMS_CellEquilnSts80_0_NO" 1 "BMS_CellEquilnSts80_1_YES";
VAL_ 1415 BMS_CellEquilnSts81 0 "BMS_CellEquilnSts81_0_NO" 1 "BMS_CellEquilnSts81_1_YES";
VAL_ 1415 BMS_CellEquilnSts82 0 "BMS_CellEquilnSts82_0_NO" 1 "BMS_CellEquilnSts82_1_YES";
VAL_ 1415 BMS_CellEquilnSts83 0 "BMS_CellEquilnSts83_0_NO" 1 "BMS_CellEquilnSts83_1_YES";
VAL_ 1415 BMS_CellEquilnSts84 0 "BMS_CellEquilnSts84_0_NO" 1 "BMS_CellEquilnSts84_1_YES";
VAL_ 1415 BMS_CellEquilnSts85 0 "BMS_CellEquilnSts85_0_NO" 1 "BMS_CellEquilnSts85_1_YES";
VAL_ 1415 BMS_CellEquilnSts86 0 "BMS_CellEquilnSts86_0_NO" 1 "BMS_CellEquilnSts86_1_YES";
VAL_ 1415 BMS_CellEquilnSts87 0 "BMS_CellEquilnSts87_0_NO" 1 "BMS_CellEquilnSts87_1_YES";
VAL_ 1415 BMS_CellEquilnSts88 0 "BMS_CellEquilnSts88_0_NO" 1 "BMS_CellEquilnSts88_1_YES";
VAL_ 1415 BMS_CellEquilnSts89 0 "BMS_CellEquilnSts89_0_NO" 1 "BMS_CellEquilnSts89_1_YES";
VAL_ 1415 BMS_CellEquilnSts9 0 "BMS_CellEquilnSts9_0_NO" 1 "BMS_CellEquilnSts9_1_YES";
VAL_ 1415 BMS_CellEquilnSts90 0 "BMS_CellEquilnSts90_0_NO" 1 "BMS_CellEquilnSts90_1_YES";
VAL_ 1415 BMS_CellEquilnSts91 0 "BMS_CellEquilnSts91_0_NO" 1 "BMS_CellEquilnSts91_1_YES";
VAL_ 1415 BMS_CellEquilnSts92 0 "BMS_CellEquilnSts92_0_NO" 1 "BMS_CellEquilnSts92_1_YES";
VAL_ 1415 BMS_CellEquilnSts93 0 "BMS_CellEquilnSts93_0_NO" 1 "BMS_CellEquilnSts93_1_YES";
VAL_ 1415 BMS_CellEquilnSts94 0 "BMS_CellEquilnSts94_0_NO" 1 "BMS_CellEquilnSts94_1_YES";
VAL_ 1415 BMS_CellEquilnSts95 0 "BMS_CellEquilnSts95_0_NO" 1 "BMS_CellEquilnSts95_1_YES";
VAL_ 1415 BMS_CellEquilnSts96 0 "BMS_CellEquilnSts96_0_NO" 1 "BMS_CellEquilnSts96_1_YES";
VAL_ 1415 BMS_CellEquilnSts97 0 "BMS_CellEquilnSts97_0_NO" 1 "BMS_CellEquilnSts97_1_YES";
VAL_ 1415 BMS_CellEquilnSts98 0 "BMS_CellEquilnSts98_0_NO" 1 "BMS_CellEquilnSts98_1_YES";
VAL_ 1415 BMS_CellEquilnSts99 0 "BMS_CellEquilnSts99_0_NO" 1 "BMS_CellEquilnSts99_1_YES";
VAL_ 1415 BMS_EquilnFltCellIdx 0 "BMS_EquilnFltCellIdx_0_Normal" 255 "BMS_EquilnFltCellIdx_255_Invalid";
VAL_ 389 BMS_ACChrgSt 0 "BMS_ACChrgSt_0_Off_未插枪" 1 "BMS_ACChrgSt_1_Init_初始化" 2 "BMS_ACChrgSt_2_Standby_待机" 3 "BMS_ACChrgSt_3_Charging_充电中" 4 "BMS_ACChrgSt_4_CHGEnd_充电终止" 5 "BMS_ACChrgSt_5_PreHeat_预热" 6 "BMS_ACChrgSt_6_Fault_充电异常终止" 7 "BMS_ACChrgSt_7_PilePowerOn_桩端供电" 8 "BMS_ACChrgSt_8_reserve";
VAL_ 389 BMS_ACOutDischrgSt 0 "BMS_ACOutDischrgSt_0_未连接OFF" 1 "BMS_ACOutDischrgSt_1_初始化Init" 2 "BMS_ACOutDischrgSt_2_准备中Standby" 3 "BMS_ACOutDischrgSt_3_放电中DisCharging" 4 "BMS_ACOutDischrgSt_4_放电完成DicChgEnd" 5 "BMS_ACOutDischrgSt_5_放电故障结束DisChgFault" 6 "BMS_ACOutDischrgSt_6_Reserved";
VAL_ 389 BMS_ActvHvOffReq 0 "BMS_ActvHvOffReq_0_No_Request" 1 "BMS_ActvHvOffReq_1_Low_Battery_HVOFF_Request" 2 "BMS_ActvHvOffReq_2_2015+PowerSupplyMode_HVOFF_Request";
VAL_ 389 BMS_ActvHvOnReq 0 "BMS_ActvHvOnReq_0_No_Request" 1 "BMS_ActvHvOnReq_1_Charge" 2 "BMS_ActvHvOnReq_2_Low_Temp_Heat" 3 "BMS_ActvHvOnReq_3_Charge&Low_Temp_Heat";
VAL_ 389 BMS_BattChrgNeeded 0 "BMS_BattChrgNeeded_0_BattChgNotNeeded" 1 "BMS_BattChrgNeeded_1_BattChgNeeded";
VAL_ 389 BMS_ChrgASigSt 0 "BMS_ChrgASigSt_0_Inactive" 1 "BMS_ChrgASigSt_1_Active";
VAL_ 389 BMS_ChrgForm 0 "BMS_ChrgForm_0_Immediate_Charge" 1 "BMS_ChrgForm_1_Timing_Charge" 2 "BMS_ChrgForm_2_Reserved";
VAL_ 389 BMS_ChrgLockReq 0 "BMS_ChrgLockReq_0_Init" 1 "BMS_ChrgLockReq_1_Lock" 2 "BMS_ChrgLockReq_2_Unlock" 3 "BMS_ChrgLockReq_3_Invalid";
VAL_ 389 BMS_ChrgRemainTime 8190 "BMS_ChrgRemainTime_8190_Initial_Value" 8191 "BMS_ChrgRemainTime_8191_Invalid";
VAL_ 389 BMS_ChrgTiEstimn 8190 "BMS_ChrgTiEstimn_8190_Initial_Value" 8191 "BMS_ChrgTiEstimn_8191_Invalid";
VAL_ 389 BMS_ChrgTrgtSOC 126 "BMS_ChrgTrgtSOC_126_Initial_Value" 127 "BMS_ChrgTrgtSOC_127_Invalid";
VAL_ 389 BMS_DCChrgConnectSt 0 "BMS_DCChrgConnectSt_0_Disconnect" 1 "BMS_DCChrgConnectSt_1_Charge_gun_fully_connected" 2 "BMS_DCChrgConnectSt_2_The_connection_is_abnormal." 3 "BMS_DCChrgConnectSt_3_Converter_connection" 4 "BMS_DCChrgConnectSt_4_discharge_gun_connection";
VAL_ 389 BMS_DCChrgSt 0 "BMS_DCChrgSt_0_Off_未插枪" 1 "BMS_DCChrgSt_1_Init_初始化" 2 "BMS_DCChrgSt_2_Standby_待机" 3 "BMS_DCChrgSt_3_Charging_充电中" 4 "BMS_DCChrgSt_4_CHGEnd_充电终止" 5 "BMS_DCChrgSt_5_PreHeat_预热" 6 "BMS_DCChrgSt_6_Fault_充电异常终止" 7 "BMS_DCChrgSt_7_预留";
VAL_ 389 BMS_DCOutDischrgSt 0 "BMS_DCOutDischrgSt_0_未连接OFF" 1 "BMS_DCOutDischrgSt_1_初始化Init" 2 "BMS_DCOutDischrgSt_2_准备中Standby" 3 "BMS_DCOutDischrgSt_3_放电中DisCharging" 4 "BMS_DCOutDischrgSt_4_放电完成DicChgEnd" 5 "BMS_DCOutDischrgSt_5_放电故障结束DisChgFault" 6 "BMS_DCOutDischrgSt_6_Reserved";
VAL_ 389 BMS_DCPileInsuTestVoltMax 1023 "BMS_DCPileInsuTestVoltMax_1023_Invalid";
VAL_ 389 BMS_DeratingCoeff 1022 "BMS_DeratingCoeff_1022_Initial_Value" 1023 "BMS_DeratingCoeff_1023_Invalid";
VAL_ 389 BMS_DrtngChg 0 "BMS_DrtngChg_0_Normal" 1 "BMS_DrtngChg_1_L1" 2 "BMS_DrtngChg_2_L2" 3 "BMS_DrtngChg_3_Reserved";
VAL_ 389 BMS_FCNegRelaySt 0 "BMS_FCNegRelaySt_0_FC_NEG_OPEN" 1 "BMS_FCNegRelaySt_1_FC_NEG_CLOSE" 2 "BMS_FCNegRelaySt_2_FC_RELAY_FAULT";
VAL_ 389 BMS_FCPosRelaySt 0 "BMS_FCPosRelaySt_0_FC_POS_OPEN" 1 "BMS_FCPosRelaySt_1_FC_POS_CLOSE" 2 "BMS_FCPosRelaySt_2_FC_RELAY_FAULT";
VAL_ 389 BMS_HVONReq 0 "BMS_HVONReq_0_No_Request" 1 "BMS_HVONReq_1_Request";
VAL_ 389 BMS_LinkEnergizeSt 0 "BMS_LinkEnergizeSt_0_None" 1 "BMS_LinkEnergizeSt_1_Starting" 2 "BMS_LinkEnergizeSt_2_Running" 3 "BMS_LinkEnergizeSt_3_Finished" 4 "BMS_LinkEnergizeSt_4_Reserved";
VAL_ 389 BMS_OBCCurrtReq 4094 "BMS_OBCCurrtReq_4094_Initial_Value" 4095 "BMS_OBCCurrtReq_4095_Invalid";
VAL_ 389 BMS_OBCInvACVoltReq 511 "BMS_OBCInvACVoltReq_511_Invalid";
VAL_ 389 BMS_OBCInvMaxPermPwr 1023 "BMS_OBCInvMaxPermPwr_1023_Invalid";
VAL_ 389 BMS_OBCVoltReq 1022 "BMS_OBCVoltReq_1022_Initial_Value" 1023 "BMS_OBCVoltReq_1023_Invalid";
VAL_ 389 BMS_OBCWorkModReq 0 "BMS_OBCWorkModReq_0_No_mode" 1 "BMS_OBCWorkModReq_1_DcChargeMode(Reserved)" 2 "BMS_OBCWorkModReq_2_AcChargeMode" 3 "BMS_OBCWorkModReq_3_BatteryWarm" 4 "BMS_OBCWorkModReq_4_InverterMode" 5 "BMS_OBCWorkModReq_5_Reserved";
VAL_ 389 BMS_PilePwrSt 0 "BMS_PilePwrSt_0_No_Request" 1 "BMS_PilePwrSt_1_Request" 2 "BMS_PilePwrSt_2_Running" 3 "BMS_PilePwrSt_3_Reserved" 7 "BMS_PilePwrSt_7__Invalid";
VAL_ 389 BMS_S1Req 0 "BMS_S1Req_0_12V_Output" 1 "BMS_S1Req_1_PWM_Output";
VAL_ 389 BMS_S2SwtCtrl 0 "BMS_S2SwtCtrl_0_No_active" 1 "BMS_S2SwtCtrl_1_Open" 2 "BMS_S2SwtCtrl_2_Close" 3 "BMS_S2SwtCtrl_3_Invalid";
VAL_ 389 BMS_S4Req 0 "BMS_S4Req_0_Detection_status" 1 "BMS_S4Req_1_Output_status";
VAL_ 795 BMS_AFEPreFail 0 "BMS_AFEPreFail_0_Normal" 1 "BMS_AFEPreFail_1_Fault";
VAL_ 795 BMS_ChrgCurrtLkUp 16382 "BMS_ChrgCurrtLkUp_16382_Initial_Value" 16383 "BMS_ChrgCurrtLkUp_16383_Invalid";
VAL_ 795 BMS_CrashPWMDuty 126 "BMS_CrashPWMDuty_126_Initial_Value" 127 "BMS_CrashPWMDuty_127_Invalid";
VAL_ 795 BMS_EquPreFail 0 "BMS_EquPreFail_0_Normal" 1 "BMS_EquPreFail_1_Fault";
VAL_ 795 BMS_EquPreFailNum 0 "BMS_EquPreFailNum_0_Normal" 1 "BMS_EquPreFailNum_1_Fault";
VAL_ 795 BMS_HighTempFaultNTCIdx 62 "BMS_HighTempFaultNTCIdx_62_Initial_Value" 63 "BMS_HighTempFaultNTCIdx_63_Invalid";
VAL_ 795 BMS_HighTempFaultNTCNum 62 "BMS_HighTempFaultNTCNum_62_Initial_Value" 63 "BMS_HighTempFaultNTCNum_63_Invalid";
VAL_ 795 BMS_HVILFCVh 8190 "BMS_HVILFCVh_8190_Initial_Value" 8191 "BMS_HVILFCVh_8191_Invalid";
VAL_ 795 BMS_HVILFCVl 8190 "BMS_HVILFCVl_8190_Initial_Value" 8191 "BMS_HVILFCVl_8191_Invalid";
VAL_ 795 BMS_HVILPWRTrainFVh 8190 "BMS_HVILPWRTrainFVh_8190_Initial_Value" 8191 "BMS_HVILPWRTrainFVh_8191_Invalid";
VAL_ 795 BMS_HVILPWRTrainFVl 8190 "BMS_HVILPWRTrainFVl_8190_Initial_Value" 8191 "BMS_HVILPWRTrainFVl_8191_Invalid";
VAL_ 795 BMS_HVILPWRTrainRVh 8190 "BMS_HVILPWRTrainRVh_8190_Initial_Value" 8191 "BMS_HVILPWRTrainRVh_8191_Invalid";
VAL_ 795 BMS_HVILPWRTrainRVl 8190 "BMS_HVILPWRTrainRVl_8190_Initial_Value" 8191 "BMS_HVILPWRTrainRVl_8191_Invalid";
VAL_ 795 BMS_InsulationNeg 65534 "BMS_InsulationNeg_65534_Initial_Value" 65535 "BMS_InsulationNeg_65535_Invalid";
VAL_ 795 BMS_InsulationPos 65534 "BMS_InsulationPos_65534_Initial_Value" 65535 "BMS_InsulationPos_65535_Invalid";
VAL_ 795 BMS_InsulationVoltNeg 8190 "BMS_InsulationVoltNeg_8190_Initial_Value" 8191 "BMS_InsulationVoltNeg_8191_Invalid";
VAL_ 795 BMS_InsulationVoltPos 8190 "BMS_InsulationVoltPos_8190_Initial_Value" 8191 "BMS_InsulationVoltPos_8191_Invalid";
VAL_ 795 BMS_LowTempFaultNTCIdx 62 "BMS_LowTempFaultNTCIdx_62_Initial_Value" 63 "BMS_LowTempFaultNTCIdx_63_Invalid";
VAL_ 795 BMS_LowTempFaultNTCNum 62 "BMS_LowTempFaultNTCNum_62_Initial_Value" 63 "BMS_LowTempFaultNTCNum_63_Invalid";
VAL_ 795 BMS_PreChgScssTime 1022 "BMS_PreChgScssTime_1022_Initial_Value" 1023 "BMS_PreChgScssTime_1023_Invalid";
VAL_ 795 BMS_TSmplngLnPreFail 0 "BMS_TSmplngLnPreFail_0_Normal" 1 "BMS_TSmplngLnPreFail_1_Fault";
VAL_ 795 BMS_VSmplngLnPreFail 0 "BMS_VSmplngLnPreFail_0_Normal" 1 "BMS_VSmplngLnPreFail_1_Fault";
VAL_ 797 BMS_CellMaxVolt 8190 "BMS_CellMaxVolt_8190_Initial_Value" 8191 "BMS_CellMaxVolt_8191_Invalid";
VAL_ 797 BMS_CellMinVolt 8190 "BMS_CellMinVolt_8190_Initial_Value" 8191 "BMS_CellMinVolt_8191_Invalid";
VAL_ 797 BMS_CellVoltSum 16382 "BMS_CellVoltSum_16382_Initial_Value" 16383 "BMS_CellVoltSum_16383_Invalid";
VAL_ 797 BMS_ModuleVolt1 1022 "BMS_ModuleVolt1_1022_Initial_Value" 1023 "BMS_ModuleVolt1_1023_Invalid";
VAL_ 797 BMS_ModuleVolt10 1022 "BMS_ModuleVolt10_1022_Initial_Value" 1023 "BMS_ModuleVolt10_1023_Invalid";
VAL_ 797 BMS_ModuleVolt11 1022 "BMS_ModuleVolt11_1022_Initial_Value" 1023 "BMS_ModuleVolt11_1023_Invalid";
VAL_ 797 BMS_ModuleVolt12 1022 "BMS_ModuleVolt12_1022_Initial_Value" 1023 "BMS_ModuleVolt12_1023_Invalid";
VAL_ 797 BMS_ModuleVolt13 1022 "BMS_ModuleVolt13_1022_Initial_Value" 1023 "BMS_ModuleVolt13_1023_Invalid";
VAL_ 797 BMS_ModuleVolt14 1022 "BMS_ModuleVolt14_1022_Initial_Value" 1023 "BMS_ModuleVolt14_1023_Invalid";
VAL_ 797 BMS_ModuleVolt2 1022 "BMS_ModuleVolt2_1022_Initial_Value" 1023 "BMS_ModuleVolt2_1023_Invalid";
VAL_ 797 BMS_ModuleVolt3 1022 "BMS_ModuleVolt3_1022_Initial_Value" 1023 "BMS_ModuleVolt3_1023_Invalid";
VAL_ 797 BMS_ModuleVolt4 1022 "BMS_ModuleVolt4_1022_Initial_Value" 1023 "BMS_ModuleVolt4_1023_Invalid";
VAL_ 797 BMS_ModuleVolt5 1022 "BMS_ModuleVolt5_1022_Initial_Value" 1023 "BMS_ModuleVolt5_1023_Invalid";
VAL_ 797 BMS_ModuleVolt6 1022 "BMS_ModuleVolt6_1022_Initial_Value" 1023 "BMS_ModuleVolt6_1023_Invalid";
VAL_ 797 BMS_ModuleVolt7 1022 "BMS_ModuleVolt7_1022_Initial_Value" 1023 "BMS_ModuleVolt7_1023_Invalid";
VAL_ 797 BMS_ModuleVolt8 1022 "BMS_ModuleVolt8_1022_Initial_Value" 1023 "BMS_ModuleVolt8_1023_Invalid";
VAL_ 797 BMS_ModuleVolt9 1022 "BMS_ModuleVolt9_1022_Initial_Value" 1023 "BMS_ModuleVolt9_1023_Invalid";
VAL_ 797 BMS_PrimaryCurrtSnsrTemp 254 "BMS_PrimaryCurrtSnsrTemp_254_Initial_Value" 255 "BMS_PrimaryCurrtSnsrTemp_255_Invalid";
VAL_ 1299 BMS_EquTemp1 254 "BMS_EquTemp1_254_Initial_Value" 255 "BMS_EquTemp1_255_Invalid";
VAL_ 1299 BMS_EquTemp10 254 "BMS_EquTemp10_254_Initial_Value" 255 "BMS_EquTemp10_255_Invalid";
VAL_ 1299 BMS_EquTemp11 254 "BMS_EquTemp11_254_Initial_Value" 255 "BMS_EquTemp11_255_Invalid";
VAL_ 1299 BMS_EquTemp12 254 "BMS_EquTemp12_254_Initial_Value" 255 "BMS_EquTemp12_255_Invalid";
VAL_ 1299 BMS_EquTemp13 254 "BMS_EquTemp13_254_Initial_Value" 255 "BMS_EquTemp13_255_Invalid";
VAL_ 1299 BMS_EquTemp14 254 "BMS_EquTemp14_254_Initial_Value" 255 "BMS_EquTemp14_255_Invalid";
VAL_ 1299 BMS_EquTemp2 254 "BMS_EquTemp2_254_Initial_Value" 255 "BMS_EquTemp2_255_Invalid";
VAL_ 1299 BMS_EquTemp3 254 "BMS_EquTemp3_254_Initial_Value" 255 "BMS_EquTemp3_255_Invalid";
VAL_ 1299 BMS_EquTemp4 254 "BMS_EquTemp4_254_Initial_Value" 255 "BMS_EquTemp4_255_Invalid";
VAL_ 1299 BMS_EquTemp5 254 "BMS_EquTemp5_254_Initial_Value" 255 "BMS_EquTemp5_255_Invalid";
VAL_ 1299 BMS_EquTemp6 254 "BMS_EquTemp6_254_Initial_Value" 255 "BMS_EquTemp6_255_Invalid";
VAL_ 1299 BMS_EquTemp7 254 "BMS_EquTemp7_254_Initial_Value" 255 "BMS_EquTemp7_255_Invalid";
VAL_ 1299 BMS_EquTemp8 254 "BMS_EquTemp8_254_Initial_Value" 255 "BMS_EquTemp8_255_Invalid";
VAL_ 1299 BMS_EquTemp9 254 "BMS_EquTemp9_254_Initial_Value" 255 "BMS_EquTemp9_255_Invalid";
VAL_ 786 BMS_AirPressure 65534 "BMS_AirPressure_65534_Initial_Value" 65535 "BMS_AirPressure_65535_Invalid";
VAL_ 786 BMS_AirPressureRate 254 "BMS_AirPressureRate_254_Initial_Value" 255 "BMS_AirPressureRate_255_Invalid";
VAL_ 786 BMS_BattSocUnderLamp 0 "BMS_BattSocUnderLamp_0_Off" 1 "BMS_BattSocUnderLamp_1_ON";
VAL_ 786 BMS_BattTempRate 254 "BMS_BattTempRate_254_Initial_Value" 255 "BMS_BattTempRate_255_Invalid";
VAL_ 786 BMS_BattTLowLamp1 0 "BMS_BattTLowLamp1_0_Off" 1 "BMS_BattTLowLamp1_1_ON";
VAL_ 786 BMS_BattTLowLamp2 0 "BMS_BattTLowLamp2_0_OFF" 1 "BMS_BattTLowLamp2_1_ON";
VAL_ 786 BMS_BattTOverLamp 0 "BMS_BattTOverLamp_0_Off" 1 "BMS_BattTOverLamp_1_ON";
VAL_ 786 BMS_HVPwrDwnRsn 0 "BMS_HVPwrDwnRsn_0_Normal" 63 "BMS_HVPwrDwnRsn_63_Invalid";
VAL_ 786 BMS_HVPwrOnFailRsn 0 "BMS_HVPwrOnFailRsn_0_Normal" 63 "BMS_HVPwrOnFailRsn_63_Invalid";
VAL_ 786 BMS_InsulationProhibitRsn 0 "BMS_InsulationProhibitRsn_0_Normal" 31 "BMS_InsulationProhibitRsn_31_Invalid";
VAL_ 786 BMS_MIL_Request 0 "BMS_MIL_Request_0_Lamp_off" 1 "BMS_MIL_Request_1_Lamp_on";
VAL_ 786 BMS_PackSOHActual 1022 "BMS_PackSOHActual_1022_Initial_Value" 1023 "BMS_PackSOHActual_1023_Invalid";
VAL_ 786 BMS_PwrBattErrLamp 0 "BMS_PwrBattErrLamp_0_Off" 1 "BMS_PwrBattErrLamp_1_ON";
VAL_ 786 BMS_ResetRsn 0 "BMS_ResetRsn_0_Normal" 255 "BMS_ResetRsn_255_Invalid";
VAL_ 786 BMS_SOCCalAlarm 0 "BMS_SOCCalAlarm_0_Normal" 1 "BMS_SOCCalAlarm_1_Alarm" 2 "BMS_SOCCalAlarm_2_Reserved";
VAL_ 786 BMS_TRWarnRsn 0 "BMS_TRWarnRsn_0_Normal" 1 "BMS_TRWarnRsn_1_Cause_No";
VAL_ 461 BST_AchievedCellVoltage 0 "BST_AchievedCellVoltage_0_Not_Achieved" 1 "BST_AchievedCellVoltage_1_Achieved" 2 "BST_AchievedCellVoltage_2_Untrusted" 3 "BST_AchievedCellVoltage_3_Reserved";
VAL_ 461 BST_AchievedPackVoltage 0 "BST_AchievedPackVoltage_0_Not_Achieved" 1 "BST_AchievedPackVoltage_1_Achieved" 2 "BST_AchievedPackVoltage_2_Untrusted" 3 "BST_AchievedPackVoltage_3_Reserved";
VAL_ 461 BST_AchievedSOC 0 "BST_AchievedSOC_0_Not_Achieved" 1 "BST_AchievedSOC_1_Achieved" 2 "BST_AchievedSOC_2_Untrusted" 3 "BST_AchievedSOC_3_Reserved";
VAL_ 461 BST_BatteryTempHigh 0 "BST_BatteryTempHigh_0_Normal" 1 "BST_BatteryTempHigh_1_Fault" 2 "BST_BatteryTempHigh_2_Untrusted" 3 "BST_BatteryTempHigh_3_Reserved";
VAL_ 461 BST_BMSComponentsFault 0 "BST_BMSComponentsFault_0_Normal" 1 "BST_BMSComponentsFault_1_Fault" 2 "BST_BMSComponentsFault_2_Untrusted" 3 "BST_BMSComponentsFault_3_Reserved";
VAL_ 461 BST_ChargeConnetorFault 0 "BST_ChargeConnetorFault_0_Normal" 1 "BST_ChargeConnetorFault_1_Fault" 2 "BST_ChargeConnetorFault_2_Untrusted" 3 "BST_ChargeConnetorFault_3_Reserved";
VAL_ 461 BST_ChargeTeminated 0 "BST_ChargeTeminated_0_Normal" 1 "BST_ChargeTeminated_1_Fault" 2 "BST_ChargeTeminated_2_Untrusted" 3 "BST_ChargeTeminated_3_Reserved";
VAL_ 461 BST_HVContactorFault 0 "BST_HVContactorFault_0_Normal" 1 "BST_HVContactorFault_1_Fault" 2 "BST_HVContactorFault_2_Untrusted" 3 "BST_HVContactorFault_3_Reserved";
VAL_ 461 BST_InsulationFault 0 "BST_InsulationFault_0_Normal" 1 "BST_InsulationFault_1_Fault" 2 "BST_InsulationFault_2_Untrusted" 3 "BST_InsulationFault_3_Reserved";
VAL_ 461 BST_OtherFault 0 "BST_OtherFault_0_Normal" 1 "BST_OtherFault_1_Fault" 2 "BST_OtherFault_2_Untrusted" 3 "BST_OtherFault_3_Reserved";
VAL_ 461 BST_OutputConectorTempHigh 0 "BST_OutputConectorTempHigh_0_Normal" 1 "BST_OutputConectorTempHigh_1_Fault" 2 "BST_OutputConectorTempHigh_2_Untrusted" 3 "BST_OutputConectorTempHigh_3_Reserved";
VAL_ 461 BST_OverCurrentError 0 "BST_OverCurrentError_0_Normal" 1 "BST_OverCurrentError_1_Fault" 2 "BST_OverCurrentError_2_Untrusted" 3 "BST_OverCurrentError_3_Reserved";
VAL_ 461 BST_Point2VoltageDetectFault 0 "BST_Point2VoltageDetectFault_0_Normal" 1 "BST_Point2VoltageDetectFault_1_Fault" 2 "BST_Point2VoltageDetectFault_2_Untrusted" 3 "BST_Point2VoltageDetectFault_3_Reserved";
VAL_ 461 BST_VoltageError 0 "BST_VoltageError_0_Normal" 1 "BST_VoltageError_1_Fault" 2 "BST_VoltageError_2_Untrusted" 3 "BST_VoltageError_3_Reserved";
VAL_ 461 CST_AchievedCondition 0 "CST_AchievedCondition_0_Normal" 1 "CST_AchievedCondition_1_Fault" 2 "CST_AchievedCondition_2_Untrusted" 3 "CST_AchievedCondition_3_Reserved";
VAL_ 461 CST_BMSAbort 0 "CST_BMSAbort_0_Normal" 1 "CST_BMSAbort_1_Fault" 2 "CST_BMSAbort_2_Untrusted" 3 "CST_BMSAbort_3_Reserved";
VAL_ 461 CST_ChargeConnetorFault 0 "CST_ChargeConnetorFault_0_Normal" 1 "CST_ChargeConnetorFault_1_Fault" 2 "CST_ChargeConnetorFault_2_Untrusted" 3 "CST_ChargeConnetorFault_3_Reserved";
VAL_ 461 CST_ChargeInnerTempFault 0 "CST_ChargeInnerTempFault_0_Normal" 1 "CST_ChargeInnerTempFault_1_Fault" 2 "CST_ChargeInnerTempFault_2_Untrusted" 3 "CST_ChargeInnerTempFault_3_Reserved";
VAL_ 461 CST_ChargeStopFault 0 "CST_ChargeStopFault_0_Normal" 1 "CST_ChargeStopFault_1_Fault" 2 "CST_ChargeStopFault_2_Untrusted" 3 "CST_ChargeStopFault_3_Reserved";
VAL_ 461 CST_ChargeTempHighFault 0 "CST_ChargeTempHighFault_0_Normal" 1 "CST_ChargeTempHighFault_1_Fault" 2 "CST_ChargeTempHighFault_2_Untrusted" 3 "CST_ChargeTempHighFault_3_Reserved";
VAL_ 461 CST_CurrentMismathError 0 "CST_CurrentMismathError_0_Normal" 1 "CST_CurrentMismathError_1_Fault" 2 "CST_CurrentMismathError_2_Untrusted" 3 "CST_CurrentMismathError_3_Reserved";
VAL_ 461 CST_EnergyTransmitFault 0 "CST_EnergyTransmitFault_0_Normal" 1 "CST_EnergyTransmitFault_1_Fault" 2 "CST_EnergyTransmitFault_2_Untrusted" 3 "CST_EnergyTransmitFault_3_Reserved";
VAL_ 461 CST_FaultAbort 0 "CST_FaultAbort_0_Normal" 1 "CST_FaultAbort_1_Fault" 2 "CST_FaultAbort_2_Untrusted" 3 "CST_FaultAbort_3_Reserved";
VAL_ 461 CST_ManualAbort 0 "CST_ManualAbort_0_Normal" 1 "CST_ManualAbort_1_Fault" 2 "CST_ManualAbort_2_Untrusted" 3 "CST_ManualAbort_3_Reserved";
VAL_ 461 CST_OtherFault 0 "CST_OtherFault_0_Normal" 1 "CST_OtherFault_1_Fault" 2 "CST_OtherFault_2_Untrusted" 3 "CST_OtherFault_3_Reserved";
VAL_ 461 CST_VolateError 0 "CST_VolateError_0_Normal" 1 "CST_VolateError_1_Fault" 2 "CST_VolateError_2_Untrusted" 3 "CST_VolateError_3_Reserved";
VAL_ 862 BCL_ChareMode 0 "BCL_ChareMode_0_Reserved_(meaningless)" 1 "BCL_ChareMode_1_Constant_voltage_charging" 2 "BCL_ChareMode_2_Constant_current_mode" 255 "BCL_ChareMode_255_Invalid";
VAL_ 862 BCL_CurrentRequire 65535 "BCL_CurrentRequire_65535_Invalid";
VAL_ 862 BCL_VoltageRequire 65535 "BCL_VoltageRequire_65535_Invalid";
VAL_ 862 BEM_CCSTimeout 0 "BEM_CCSTimeout_0_Normal" 1 "BEM_CCSTimeout_1_Timeout" 2 "BEM_CCSTimeout_2_Untrusted" 3 "BEM_CCSTimeout_3_Reserved";
VAL_ 862 BEM_CRMTimeout00 0 "BEM_CRMTimeout00_0_Normal" 1 "BEM_CRMTimeout00_1_Timeout" 2 "BEM_CRMTimeout00_2_Untrusted" 3 "BEM_CRMTimeout00_3_Reserved";
VAL_ 862 BEM_CRMTimeoutAA 0 "BEM_CRMTimeoutAA_0_Normal" 1 "BEM_CRMTimeoutAA_1_Timeout" 2 "BEM_CRMTimeoutAA_2_Untrusted" 3 "BEM_CRMTimeoutAA_3_Reserved";
VAL_ 862 BEM_CROTimeout 0 "BEM_CROTimeout_0_Normal" 1 "BEM_CROTimeout_1_Timeout" 2 "BEM_CROTimeout_2_Untrusted" 3 "BEM_CROTimeout_3_Reserved";
VAL_ 862 BEM_CSDTimeout 0 "BEM_CSDTimeout_0_Normal" 1 "BEM_CSDTimeout_1_Timeout" 2 "BEM_CSDTimeout_2_Untrusted" 3 "BEM_CSDTimeout_3_Reserved";
VAL_ 862 BEM_CSTTimeout 0 "BEM_CSTTimeout_0_Normal" 1 "BEM_CSTTimeout_1_Timeout" 2 "BEM_CSTTimeout_2_Untrusted" 3 "BEM_CSTTimeout_3_Reserved";
VAL_ 862 BEM_CTS_CMLTimeout 0 "BEM_CTS_CMLTimeout_0_Normal" 1 "BEM_CTS_CMLTimeout_1_Timeout" 2 "BEM_CTS_CMLTimeout_2_Untrusted" 3 "BEM_CTS_CMLTimeout_3_Reserved";
VAL_ 862 BEM_Other 0 "BEM_Other_0_Normal" 1 "BEM_Other_1_Timeout" 2 "BEM_Other_2_Untrusted" 3 "BEM_Other_3_Reserved";
VAL_ 862 BRM_BatteryChargeTimes 16777215 "BRM_BatteryChargeTimes_16777215_Invalid";
VAL_ 862 BRM_BatteryManufacture 4294967295 "BRM_BatteryManufacture_4294967295_Invalid";
VAL_ 862 BRO_BMSChargeReady 0 "BRO_BMSChargeReady_0_Not_ready_to_charge" 170 "BRO_BMSChargeReady_170_Ready_to_charge" 255 "BRO_BMSChargeReady_255_Invalid";
VAL_ 862 CCS_ChargeAllowed 0 "CCS_ChargeAllowed_0_Pause" 1 "CCS_ChargeAllowed_1_Allowed" 2 "CCS_ChargeAllowed_2_Reserved";
VAL_ 862 CCS_OutputCurent 65535 "CCS_OutputCurent_65535_Invalid";
VAL_ 862 CCS_OutputVoltage 65535 "CCS_OutputVoltage_65535_Invalid";
VAL_ 862 CCS_TotalChargeTime 65535 "CCS_TotalChargeTime_65535_Invalid";
VAL_ 862 CEM_BCLTimeout 0 "CEM_BCLTimeout_0_Normal" 1 "CEM_BCLTimeout_1_Timeout" 2 "CEM_BCLTimeout_2_Untrusted" 3 "CEM_BCLTimeout_3_Reserved";
VAL_ 862 CEM_BCPTimeout 0 "CEM_BCPTimeout_0_Normal" 1 "CEM_BCPTimeout_1_Timeout" 2 "CEM_BCPTimeout_2_Untrusted" 3 "CEM_BCPTimeout_3_Reserved";
VAL_ 862 CEM_BCSTimeout 0 "CEM_BCSTimeout_0_Normal" 1 "CEM_BCSTimeout_1_Timeout" 2 "CEM_BCSTimeout_2_Untrusted" 3 "CEM_BCSTimeout_3_Reserved";
VAL_ 862 CEM_BRMTimeout 0 "CEM_BRMTimeout_0_Normal" 1 "CEM_BRMTimeout_1_Timeout" 2 "CEM_BRMTimeout_2_Untrusted" 3 "CEM_BRMTimeout_3_Reserved";
VAL_ 862 CEM_BROTimeout 0 "CEM_BROTimeout_0_Normal" 1 "CEM_BROTimeout_1_Timeout" 2 "CEM_BROTimeout_2_Untrusted" 3 "CEM_BROTimeout_3_Reserved";
VAL_ 862 CEM_BSDTimeout 0 "CEM_BSDTimeout_0_Normal" 1 "CEM_BSDTimeout_1_Timeout" 2 "CEM_BSDTimeout_2_Untrusted" 3 "CEM_BSDTimeout_3_Reserved";
VAL_ 862 CEM_BSTTimeout 0 "CEM_BSTTimeout_0_Normal" 1 "CEM_BSTTimeout_1_Timeout" 2 "CEM_BSTTimeout_2_Untrusted" 3 "CEM_BSTTimeout_3_Reserved";
VAL_ 862 CEM_Other 0 "CEM_Other_0_Normal" 1 "CEM_Other_1_Timeout" 2 "CEM_Other_2_Untrusted" 3 "CEM_Other_3_Reserved";
VAL_ 862 CHM_ComVersion 16777215 "CHM_ComVersion_16777215_Invalid";
VAL_ 862 CML_OutputCurentMax 65535 "CML_OutputCurentMax_65535_Invalid";
VAL_ 862 CML_OutputCurentMin 65535 "CML_OutputCurentMin_65535_Invalid";
VAL_ 862 CML_OutputVoltageMax 65535 "CML_OutputVoltageMax_65535_Invalid";
VAL_ 862 CML_OutputVoltageMin 65535 "CML_OutputVoltageMin_65535_Invalid";
VAL_ 862 CRM_ChargeNo 4294967295 "CRM_ChargeNo_4294967295_Invalid";
VAL_ 862 CRM_RecongnitionResult 0 "CRM_RecongnitionResult_0_Not_Recongnition" 170 "CRM_RecongnitionResult_170_Recongnition" 255 "CRM_RecongnitionResult_255_Invalid";
VAL_ 862 CRM_RegionCode 16777215 "CRM_RegionCode_16777215_Invalid";
VAL_ 862 CRO_ChargeReady 0 "CRO_ChargeReady_0_Not_ready" 170 "CRO_ChargeReady_170_Ready" 255 "CRO_ChargeReady_255_Invalid";
VAL_ 862 CSD_TotalChrgEnergy 65535 "CSD_TotalChrgEnergy_65535_Invalid";
VAL_ 1416 BMS_BattConstnceErrGb 0 "BMS_BattConstnceErrGb_0_No_Error" 1 "BMS_BattConstnceErrGb_1_Error";
VAL_ 1416 BMS_BattIGb 65534 "BMS_BattIGb_65534_Initial_Value";
VAL_ 1416 BMS_BattMatchErrGb 0 "BMS_BattMatchErrGb_0_No_Error" 1 "BMS_BattMatchErrGb_1_Error";
VAL_ 1416 BMS_BattNrTotGb 254 "BMS_BattNrTotGb_254_Initial_Value";
VAL_ 1416 BMS_BattSocHiGb 0 "BMS_BattSocHiGb_0_No_Error" 1 "BMS_BattSocHiGb_1_Error";
VAL_ 1416 BMS_BattSocJmpGb 0 "BMS_BattSocJmpGb_0_No_Error" 1 "BMS_BattSocJmpGb_1_Error";
VAL_ 1416 BMS_BattSocLoGb 0 "BMS_BattSocLoGb_0_No_Error" 1 "BMS_BattSocLoGb_1_Error";
VAL_ 1416 BMS_BattTOverGb 0 "BMS_BattTOverGb_0_No_Error" 1 "BMS_BattTOverGb_1_Error";
VAL_ 1416 BMS_BattUGb 65535 "BMS_BattUGb_65535_Invalid";
VAL_ 1416 BMS_BattUMaxNrGb 255 "BMS_BattUMaxNrGb_255_Invalid";
VAL_ 1416 BMS_BattUMinNrGb 255 "BMS_BattUMinNrGb_255_Invalid";
VAL_ 1416 BMS_BattUOverGb 0 "BMS_BattUOverGb_0_No_Error" 1 "BMS_BattUOverGb_1_Error";
VAL_ 1416 BMS_BattUUnderGb 0 "BMS_BattUUnderGb_0_No_Error" 1 "BMS_BattUUnderGb_1_Error";
VAL_ 1416 BMS_CellNrTotGb 65535 "BMS_CellNrTotGb_65535_Invalid";
VAL_ 1416 BMS_CellUMaxGb 65535 "BMS_CellUMaxGb_65535_Invalid";
VAL_ 1416 BMS_CellUMaxNrGb 255 "BMS_CellUMaxNrGb_255_Invalid";
VAL_ 1416 BMS_CellUMinGb 65535 "BMS_CellUMinGb_65535_Invalid";
VAL_ 1416 BMS_CellUMinNrGb 255 "BMS_CellUMinNrGb_255_Invalid";
VAL_ 1416 BMS_CellUOverGb 0 "BMS_CellUOverGb_0_No_Error" 1 "BMS_CellUOverGb_1_Error";
VAL_ 1416 BMS_CellUUnderGb 0 "BMS_CellUUnderGb_0_No_Error" 1 "BMS_CellUUnderGb_1_Error";
VAL_ 1416 BMS_ChrgOverGb 0 "BMS_ChrgOverGb_0_No_Error" 1 "BMS_ChrgOverGb_1_Error";
VAL_ 1416 BMS_ChrgStGb 0 "BMS_ChrgStGb_0_INVALID" 1 "BMS_ChrgStGb_1_CHARGING_IN_PARK" 2 "BMS_ChrgStGb_2_CHARGING_IN_DRIVE" 3 "BMS_ChrgStGb_3_NOT_CHARGING" 4 "BMS_ChrgStGb_4_CHARGE_COMPLETE" 5 "BMS_ChrgStGb_5_CHARGE_ABNORMAL" 6 "BMS_ChrgStGb_6_Reserved" 7 "BMS_ChrgStGb_7_Reserved";
VAL_ 1416 BMS_DeltaTOverGb 0 "BMS_DeltaTOverGb_0_No_Error" 1 "BMS_DeltaTOverGb_1_Error";
VAL_ 1416 BMS_HvilStsGb 0 "BMS_HvilStsGb_0_No_Error" 1 "BMS_HvilStsGb_1_Error";
VAL_ 1416 BMS_InsulationRGb 65535 "BMS_InsulationRGb_65535_Invalid";
VAL_ 1416 BMS_InsulationStsGb 0 "BMS_InsulationStsGb_0_No_Error" 1 "BMS_InsulationStsGb_1_Error";
VAL_ 1416 BMS_ModTMaxGb 254 "BMS_ModTMaxGb_254_Initial_Value";
VAL_ 1416 BMS_ModTMaxNrGb 255 "BMS_ModTMaxNrGb_255_Invalid";
VAL_ 1416 BMS_ModTMinGb 254 "BMS_ModTMinGb_254_Initial_Value";
VAL_ 1416 BMS_ModTMinNrGb 255 "BMS_ModTMinNrGb_255_Invalid";
VAL_ 1416 BMS_SnsrTMaxNrGb 255 "BMS_SnsrTMaxNrGb_255_Invalid";
VAL_ 1416 BMS_SnsrTMinNrGb 255 "BMS_SnsrTMinNrGb_255_Invalid";
VAL_ 1416 BMS_SnsrTNrTotGb 65535 "BMS_SnsrTNrTotGb_65535_Invalid";
VAL_ 1416 BMS_SocGb 255 "BMS_SocGb_255_Invalid";
VAL_ 1301 BMS_BattInlT 255 "BMS_BattInlT_255_Invalid";
VAL_ 1301 BMS_HVIL_CDU_St 0 "BMS_HVIL_CDU_St_0_Not_ready" 1 "BMS_HVIL_CDU_St_1_Lock" 2 "BMS_HVIL_CDU_St_2_Unlock" 3 "BMS_HVIL_CDU_St_3_HW_Fault";
VAL_ 1301 BMS_HVIL_TDU_St 0 "BMS_HVIL_TDU_St_0_Not_ready" 1 "BMS_HVIL_TDU_St_1_Lock" 2 "BMS_HVIL_TDU_St_2_Unlock" 3 "BMS_HVIL_TDU_St_3_HW_Fault";
VAL_ 260 BMS_BattCurrt 32766 "BMS_BattCurrt_32766_Initial_Value" 32767 "BMS_BattCurrt_32767_Invalid";
VAL_ 260 BMS_BattCurrtSnsr1 32766 "BMS_BattCurrtSnsr1_32766_Initial_Value" 32767 "BMS_BattCurrtSnsr1_32767_Invalid";
VAL_ 260 BMS_BattCurrtSnsr1PreFail 0 "BMS_BattCurrtSnsr1PreFail_0_Normal" 1 "BMS_BattCurrtSnsr1PreFail_1_Fault";
VAL_ 260 BMS_BattCurrtSnsr2 32766 "BMS_BattCurrtSnsr2_32766_Initial_Value" 32767 "BMS_BattCurrtSnsr2_32767_Invalid";
VAL_ 260 BMS_BattCurrtSnsr2PreFail 0 "BMS_BattCurrtSnsr2PreFail_0_Normal" 1 "BMS_BattCurrtSnsr2PreFail_1_Fault";
VAL_ 260 BMS_BattVolt_U1 16382 "BMS_BattVolt_U1_16382_Initial_Value" 16383 "BMS_BattVolt_U1_16383_Invalid";
VAL_ 260 BMS_BattVolt_U2 16382 "BMS_BattVolt_U2_16382_Initial_Value" 16383 "BMS_BattVolt_U2_16383_Invalid";
VAL_ 260 BMS_BattVolt_U7 16382 "BMS_BattVolt_U7_16382_Initial_Value" 16383 "BMS_BattVolt_U7_16383_Invalid";
VAL_ 260 BMS_BattVolt_U8 16382 "BMS_BattVolt_U8_16382_Initial_Value" 16383 "BMS_BattVolt_U8_16383_Invalid";
VAL_ 260 BMS_LVBattVolt_KL30 254 "BMS_LVBattVolt_KL30_254_Initial_Value" 255 "BMS_LVBattVolt_KL30_255_Invalid";
VAL_ 260 BMS_LVBattVolt_Relay 255 "BMS_LVBattVolt_Relay_255_Invalid";
VAL_ 260 BMS_vPackG0PreFail 0 "BMS_vPackG0PreFail_0_Normal" 1 "BMS_vPackG0PreFail_1_Fault";
VAL_ 260 BMS_vPackG1PreFail 0 "BMS_vPackG1PreFail_0_Normal" 1 "BMS_vPackG1PreFail_1_Fault";
VAL_ 269 BMS_CurrtLimitCharge 16382 "BMS_CurrtLimitCharge_16382_Initial_Value" 16383 "BMS_CurrtLimitCharge_16383_Invalid";
VAL_ 269 BMS_CurrtLimitDrive 16382 "BMS_CurrtLimitDrive_16382_Initial_Value" 16383 "BMS_CurrtLimitDrive_16383_Invalid";
VAL_ 269 BMS_CurrtLimitFeedback 16382 "BMS_CurrtLimitFeedback_16382_Initial_Value" 16383 "BMS_CurrtLimitFeedback_16383_Invalid";
VAL_ 269 BMS_PackPwr 32766 "BMS_PackPwr_32766_Initial_Value" 32767 "BMS_PackPwr_32767_Invalid";
VAL_ 269 BMS_PackSOCActual 1022 "BMS_PackSOCActual_1022_Initial_Value" 1023 "BMS_PackSOCActual_1023_Invalid";
VAL_ 269 BMS_PackSOCCalc 1022 "BMS_PackSOCCalc_1022_Initial_Value" 1023 "BMS_PackSOCCalc_1023_Invalid";
VAL_ 269 BMS_PackSOCDisp 127 "BMS_PackSOCDisp_127_Invalid";
VAL_ 269 BMS_PackSOCRange 1022 "BMS_PackSOCRange_1022_Initial_Value" 1023 "BMS_PackSOCRange_1023_Invalid";
VAL_ 269 BMS_PackSOEActual 262142 "BMS_PackSOEActual_262142_Initial_Value" 262143 "BMS_PackSOEActual_262143_Invalid";
VAL_ 269 BMS_PackSOEDisp 16382 "BMS_PackSOEDisp_16382_Initial_Value" 16383 "BMS_PackSOEDisp_16383_Invalid";
VAL_ 269 BMS_PackSOHDisp 1022 "BMS_PackSOHDisp_1022_Initial_Value" 1023 "BMS_PackSOHDisp_1023_Invalid";
VAL_ 269 BMS_PwrLimitCharge 16382 "BMS_PwrLimitCharge_16382_Initial_Value" 16383 "BMS_PwrLimitCharge_16383_Invalid";
VAL_ 269 BMS_PwrLimitDrive 16382 "BMS_PwrLimitDrive_16382_Initial_Value" 16383 "BMS_PwrLimitDrive_16383_Invalid";
VAL_ 269 BMS_PwrLimitFeedback 16382 "BMS_PwrLimitFeedback_16382_Initial_Value" 16383 "BMS_PwrLimitFeedback_16383_Invalid";
VAL_ 528 BMS_ChrgCurrtContnsMax 16382 "BMS_ChrgCurrtContnsMax_16382_Initial_Value" 16383 "BMS_ChrgCurrtContnsMax_16383_Invalid";
VAL_ 528 BMS_ChrgCurrtLongTiMax 16382 "BMS_ChrgCurrtLongTiMax_16382_Initial_Value" 16383 "BMS_ChrgCurrtLongTiMax_16383_Invalid";
VAL_ 528 BMS_ChrgCurrtShoTiMax 16382 "BMS_ChrgCurrtShoTiMax_16382_Initial_Value" 16383 "BMS_ChrgCurrtShoTiMax_16383_Invalid";
VAL_ 528 BMS_ChrgPwrContnsMax 16382 "BMS_ChrgPwrContnsMax_16382_Initial_Value" 16383 "BMS_ChrgPwrContnsMax_16383_Invalid";
VAL_ 528 BMS_ChrgPwrLongTiMax 16382 "BMS_ChrgPwrLongTiMax_16382_Initial_Value" 16383 "BMS_ChrgPwrLongTiMax_16383_Invalid";
VAL_ 528 BMS_ChrgPwrShoTiMax 16382 "BMS_ChrgPwrShoTiMax_16382_Initial_Value" 16383 "BMS_ChrgPwrShoTiMax_16383_Invalid";
VAL_ 528 BMS_DchaCurrtContnsMax 16382 "BMS_DchaCurrtContnsMax_16382_Initial_Value" 16383 "BMS_DchaCurrtContnsMax_16383_Invalid";
VAL_ 528 BMS_DchaCurrtLongTiMax 16382 "BMS_DchaCurrtLongTiMax_16382_Initial_Value" 16383 "BMS_DchaCurrtLongTiMax_16383_Invalid";
VAL_ 528 BMS_DchaCurrtShoTiMax 16382 "BMS_DchaCurrtShoTiMax_16382_Initial_Value" 16383 "BMS_DchaCurrtShoTiMax_16383_Invalid";
VAL_ 528 BMS_DchaPwrContnsMax 16382 "BMS_DchaPwrContnsMax_16382_Initial_Value" 16383 "BMS_DchaPwrContnsMax_16383_Invalid";
VAL_ 528 BMS_DchaPwrLongTiMax 16382 "BMS_DchaPwrLongTiMax_16382_Initial_Value" 16383 "BMS_DchaPwrLongTiMax_16383_Invalid";
VAL_ 528 BMS_DchaPwrShoTiMax 16382 "BMS_DchaPwrShoTiMax_16382_Initial_Value" 16383 "BMS_DchaPwrShoTiMax_16383_Invalid";
VAL_ 528 BMS_NormSOPLimSt 0 "BMS_NormSOPLimSt_0_NoLimit" 1 "BMS_NormSOPLimSt_1_ChargeLimt" 2 "BMS_NormSOPLimSt_2_DischargeLimit" 3 "BMS_NormSOPLimSt_3_FeedbackLimit" 4 "BMS_NormSOPLimSt_4_Reserved";
VAL_ 528 BMS_PackSOCNotAvrlble 1022 "BMS_PackSOCNotAvrlble_1022_Initial_Value" 1023 "BMS_PackSOCNotAvrlble_1023_Invalid";
VAL_ 263 BMS_AbnormalPollingSt 0 "BMS_AbnormalPollingSt_0_Normal" 1 "BMS_AbnormalPollingSt_1_Abnormal" 2 "BMS_AbnormalPollingSt_2_Reserved";
VAL_ 263 BMS_AFEWakeupSt 0 "BMS_AFEWakeupSt_0_Sleep" 1 "BMS_AFEWakeupSt_1_AFE_Wakeup" 2 "BMS_AFEWakeupSt_2_Reserved";
VAL_ 263 BMS_APlusWakeupSt 0 "BMS_APlusWakeupSt_0_Sleep" 1 "BMS_APlusWakeupSt_1_A+_Wakeup" 2 "BMS_APlusWakeupSt_2_Reserved";
VAL_ 263 BMS_BPSWakeupSt 0 "BMS_BPSWakeupSt_0_Sleep" 1 "BMS_BPSWakeupSt_1_BPS_Wakeup" 2 "BMS_BPSWakeupSt_2_Reserved";
VAL_ 263 BMS_CC1WakeupSt 0 "BMS_CC1WakeupSt_0_Sleep" 1 "BMS_CC1WakeupSt_1_CC1_Wakeup" 2 "BMS_CC1WakeupSt_2_Reserved";
VAL_ 263 BMS_CC2WakeupSt 0 "BMS_CC2WakeupSt_0_Sleep" 1 "BMS_CC2WakeupSt_1_CC2_Wakeup" 2 "BMS_CC2WakeupSt_2_Reserved";
VAL_ 263 BMS_CrashSt 0 "BMS_CrashSt_0_No_Error" 1 "BMS_CrashSt_1_PWM_Error" 2 "BMS_CrashSt_2_CAN_Error" 3 "BMS_CrashSt_3_Reserved";
VAL_ 263 BMS_DCBBoxRlyCtrlCmd 0 "BMS_DCBBoxRlyCtrlCmd_0_OPEN" 1 "BMS_DCBBoxRlyCtrlCmd_1_CLOSE";
VAL_ 263 BMS_DCBCapRlyCtrlCmd 0 "BMS_DCBCapRlyCtrlCmd_0_OPEN" 1 "BMS_DCBCapRlyCtrlCmd_1_CLOSE";
VAL_ 263 BMS_DCBoostChrgReq 0 "BMS_DCBoostChrgReq_0_Init" 1 "BMS_DCBoostChrgReq_1_Demand" 2 "BMS_DCBoostChrgReq_2_No_Demand" 3 "BMS_DCBoostChrgReq_3_Reserved";
VAL_ 263 BMS_DCChrgProtocolVers 0 "BMS_DCChrgProtocolVers_0_Initial" 255 "BMS_DCChrgProtocolVers_255_Invalid";
VAL_ 263 BMS_FaultLevel 0 "BMS_FaultLevel_0_Normal" 1 "BMS_FaultLevel_1_Level_1" 2 "BMS_FaultLevel_2_Level_2" 3 "BMS_FaultLevel_3_Level_3" 4 "BMS_FaultLevel_4_Level_4" 5 "BMS_FaultLevel_5_Level_5" 6 "BMS_FaultLevel_6_Level_6" 7 "BMS_FaultLevel_7_Reserved";
VAL_ 263 BMS_HVIL_FC_St 0 "BMS_HVIL_FC_St_0_Not_ready" 1 "BMS_HVIL_FC_St_1_Lock" 2 "BMS_HVIL_FC_St_2_Unlock" 3 "BMS_HVIL_FC_St_3_HW_Fault";
VAL_ 263 BMS_HVIL_FMot_St 0 "BMS_HVIL_FMot_St_0_Not_ready" 1 "BMS_HVIL_FMot_St_1_Lock" 2 "BMS_HVIL_FMot_St_2_Unlock" 3 "BMS_HVIL_FMot_St_3_HW_Fault";
VAL_ 263 BMS_HVIL_RMot_St 0 "BMS_HVIL_RMot_St_0_Not_ready" 1 "BMS_HVIL_RMot_St_1_Lock" 2 "BMS_HVIL_RMot_St_2_Unlock" 3 "BMS_HVIL_RMot_St_3_HW_Fault";
VAL_ 263 BMS_HWWakeupSt 0 "BMS_HWWakeupSt_0_Sleep" 1 "BMS_HWWakeupSt_1_Hardwire_Wakeup" 2 "BMS_HWWakeupSt_2_Reserved";
VAL_ 263 BMS_InsulationFaultlevel 0 "BMS_InsulationFaultlevel_0_None" 1 "BMS_InsulationFaultlevel_1_Level1" 2 "BMS_InsulationFaultlevel_2_Level2" 3 "BMS_InsulationFaultlevel_3_Level3";
VAL_ 263 BMS_InsulationSt 0 "BMS_InsulationSt_0_Unknow" 1 "BMS_InsulationSt_1_Normal" 2 "BMS_InsulationSt_2_Fault_LEVEL_1" 3 "BMS_InsulationSt_3_Fault_LEVEL_2" 4 "BMS_InsulationSt_4_Fault_LEVEL_3" 5 "BMS_InsulationSt_5_Fault_LEVEL_4" 6 "BMS_InsulationSt_6_Reseverd";
VAL_ 263 BMS_LowSOCHVOffReq 0 "BMS_LowSOCHVOffReq_0_NoRequest" 1 "BMS_LowSOCHVOffReq_1_HVOffRequest";
VAL_ 263 BMS_MainNegSt 0 "BMS_MainNegSt_0_Open" 1 "BMS_MainNegSt_1_Close" 2 "BMS_MainNegSt_2_Fault";
VAL_ 263 BMS_MainPosSt 0 "BMS_MainPosSt_0_Open" 1 "BMS_MainPosSt_1_Close" 2 "BMS_MainPosSt_2_Fault";
VAL_ 263 BMS_MainPreChrgSt 0 "BMS_MainPreChrgSt_0_Open" 1 "BMS_MainPreChrgSt_1_Close" 2 "BMS_MainPreChrgSt_2_Fault";
VAL_ 263 BMS_MCURDCBoostChrgModReq 0 "BMS_MCURDCBoostChrgModReq_0_Init" 1 "BMS_MCURDCBoostChrgModReq_1_Constant_voltage_mode" 2 "BMS_MCURDCBoostChrgModReq_2_Constant_current_mode" 3 "BMS_MCURDCBoostChrgModReq_3_Constant_change_ratio";
VAL_ 263 BMS_MCURDCBoostChrgOperReq 0 "BMS_MCURDCBoostChrgOperReq_0_No_Work" 1 "BMS_MCURDCBoostChrgOperReq_1_Buck_Precharge" 2 "BMS_MCURDCBoostChrgOperReq_2_Boost_Charge" 3 "BMS_MCURDCBoostChrgOperReq_3_Reserved" 4 "BMS_MCURDCBoostChrgOperReq_4_Discharge" 5 "BMS_MCURDCBoostChrgOperReq_5_Reserved" 6 "BMS_MCURDCBoostChrgOperReq_6_Reserved" 7 "BMS_MCURDCBoostChrgOperReq_7_Reserved";
VAL_ 263 BMS_NegInsulationSt 0 "BMS_NegInsulationSt_0_Unknow" 1 "BMS_NegInsulationSt_1_Normal" 2 "BMS_NegInsulationSt_2_Fault" 3 "BMS_NegInsulationSt_3_HWFault";
VAL_ 263 BMS_NMWakeupSt 0 "BMS_NMWakeupSt_0_Sleep" 1 "BMS_NMWakeupSt_1_NM_Wakeup" 2 "BMS_NMWakeupSt_2_Reserved";
VAL_ 263 BMS_OBDFaultExistSts 0 "BMS_OBDFaultExistSts_0_No_OBD_Fault" 1 "BMS_OBDFaultExistSts_1_OBD_Fault";
VAL_ 263 BMS_OperSt 0 "BMS_OperSt_0_Initial_初始化" 1 "BMS_OperSt_1_Standby_待机" 2 "BMS_OperSt_2_Precharge_预充" 3 "BMS_OperSt_3_HVON_电池包高压Ready" 4 "BMS_OperSt_4_HVOff_高压下电" 5 "BMS_OperSt_5_Polling_巡检不上高压" 6 "BMS_OperSt_6_AfterRun" 7 "BMS_OperSt_7_HVFault_无法上高压或故障下高压状态" 8 "BMS_OperSt_8_LinkHVON_桩端高压Ready" 9 "BMS_OperSt_9_Reserved";
VAL_ 263 BMS_PckInsulationSt 0 "BMS_PckInsulationSt_0_Unknow" 1 "BMS_PckInsulationSt_1_Normal" 2 "BMS_PckInsulationSt_2_Fault" 3 "BMS_PckInsulationSt_3_HWFault";
VAL_ 263 BMS_PosInsulationSt 0 "BMS_PosInsulationSt_0_Unknow" 1 "BMS_PosInsulationSt_1_Normal" 2 "BMS_PosInsulationSt_2_Fault" 3 "BMS_PosInsulationSt_3_HWFault";
VAL_ 263 BMS_RTCWakeupSt 0 "BMS_RTCWakeupSt_0_Sleep" 1 "BMS_RTCWakeupSt_1_RTC_Wakeup" 2 "BMS_RTCWakeupSt_2_Reserved";
VAL_ 263 BMS_ThermRunawaySt 0 "BMS_ThermRunawaySt_0_No_Error" 1 "BMS_ThermRunawaySt_1_Error" 2 "BMS_ThermRunawaySt_2_Reserved";
VAL_ 263 BMS_VeInsulationSt 0 "BMS_VeInsulationSt_0_Unknow未知" 1 "BMS_VeInsulationSt_1_Normal正常" 2 "BMS_VeInsulationSt_2_Fault故障" 3 "BMS_VeInsulationSt_3_HWFault检测电路故障";
VAL_ 263 BMS_WorkMode 0 "BMS_WorkMode_0_Initial" 1 "BMS_WorkMode_1_Standby" 2 "BMS_WorkMode_2_AC_Mode_AC" 3 "BMS_WorkMode_3_DC_Mode_DC" 4 "BMS_WorkMode_4_DynamicMode" 5 "BMS_WorkMode_5_StaticMode" 6 "BMS_WorkMode_6_Reserved";
VAL_ 1417 BMS_ACChrgCpDisp 254 "BMS_ACChrgCpDisp_254_Initial_Value" 255 "BMS_ACChrgCpDisp_255_Invalid";
VAL_ 1417 BMS_ACChrgEngDisp 254 "BMS_ACChrgEngDisp_254_Initial_Value" 255 "BMS_ACChrgEngDisp_255_Invalid";
VAL_ 1417 BMS_BattType 0 "BMS_BattType_0_Unknow" 1 "BMS_BattType_1_lithium_iron_phosphate" 2 "BMS_BattType_2_lithium_manganate" 3 "BMS_BattType_3_lithium_cobaltate" 4 "BMS_BattType_4_ternary_material" 5 "BMS_BattType_5_polymer_lithium_ion" 6 "BMS_BattType_6_supercapacitor" 7 "BMS_BattType_7_Lithium_titanate" 8 "BMS_BattType_8_fuel_cell" 9 "BMS_BattType_9_Lithium_ferromanganese_phosphate_+_ternary_blend" 10 "BMS_BattType_10_Reserved" 15 "BMS_BattType_15_Invalid";
VAL_ 1417 BMS_DCChrgCpDisp 254 "BMS_DCChrgCpDisp_254_Initial_Value" 255 "BMS_DCChrgCpDisp_255_Invalid";
VAL_ 1417 BMS_DCChrgEngDisp 254 "BMS_DCChrgEngDisp_254_Initial_Value" 255 "BMS_DCChrgEngDisp_255_Invalid";
VAL_ 1417 BMS_DisChaCpDisp 254 "BMS_DisChaCpDisp_254_Initial_Value" 255 "BMS_DisChaCpDisp_255_Invalid";
VAL_ 1417 BMS_DisChaEngDisp 254 "BMS_DisChaEngDisp_254_Initial_Value" 255 "BMS_DisChaEngDisp_255_Invalid";
VAL_ 1417 BMS_RegenCpDisp 254 "BMS_RegenCpDisp_254_Initial_Value" 255 "BMS_RegenCpDisp_255_Invalid";
VAL_ 1417 BMS_RegenEngDisp 254 "BMS_RegenEngDisp_254_Initial_Value" 255 "BMS_RegenEngDisp_255_Invalid";
VAL_ 1417 BMS_TotalACChrgCpDisp 4194302 "BMS_TotalACChrgCpDisp_4194302_Initial_Value" 4194303 "BMS_TotalACChrgCpDisp_4194303_Invalid";
VAL_ 1417 BMS_TotalACChrgEngDisp 4194302 "BMS_TotalACChrgEngDisp_4194302_Initial_Value" 4194303 "BMS_TotalACChrgEngDisp_4194303_Invalid";
VAL_ 1417 BMS_TotalDCChrgCpDisp 4194302 "BMS_TotalDCChrgCpDisp_4194302_Initial_Value" 4194303 "BMS_TotalDCChrgCpDisp_4194303_Invalid";
VAL_ 1417 BMS_TotalDCChrgEngDisp 4194302 "BMS_TotalDCChrgEngDisp_4194302_Initial_Value" 4194303 "BMS_TotalDCChrgEngDisp_4194303_Invalid";
VAL_ 1417 BMS_TotalDisChaCpDisp 4194302 "BMS_TotalDisChaCpDisp_4194302_Initial_Value" 4194303 "BMS_TotalDisChaCpDisp_4194303_Invalid";
VAL_ 1417 BMS_TotalDisChaEngDisp 4194302 "BMS_TotalDisChaEngDisp_4194302_Initial_Value" 4194303 "BMS_TotalDisChaEngDisp_4194303_Invalid";
VAL_ 1417 BMS_TotalRegenCpDisp 4194302 "BMS_TotalRegenCpDisp_4194302_Initial_Value" 4194303 "BMS_TotalRegenCpDisp_4194303_Invalid";
VAL_ 1417 BMS_TotalRegenEngDisp 4194302 "BMS_TotalRegenEngDisp_4194302_Initial_Value" 4194303 "BMS_TotalRegenEngDisp_4194303_Invalid";
VAL_ 791 BMS_BattTempAvg 254 "BMS_BattTempAvg_254_Initial_Value" 255 "BMS_BattTempAvg_255_Invalid";
VAL_ 791 BMS_BattTempMax 254 "BMS_BattTempMax_254_Initial_Value" 255 "BMS_BattTempMax_255_Invalid";
VAL_ 791 BMS_BattTempMin 254 "BMS_BattTempMin_254_Initial_Value" 255 "BMS_BattTempMin_255_Invalid";
VAL_ 791 BMS_BookHeatStsRsp 0 "BMS_BookHeatStsRsp_0_Off" 1 "BMS_BookHeatStsRsp_1_Heating" 2 "BMS_BookHeatStsRsp_2_The_SOC_is_too_low_and_cannot_be_enabled." 3 "BMS_BookHeatStsRsp_3_No_heating_required" 4 "BMS_BookHeatStsRsp_4_The_system_is_abnormal_and_cannot_be_enabled." 5 "BMS_BookHeatStsRsp_5_Abnormal_exit_(Temperature_cannot_be_increased)" 6 "BMS_BookHeatStsRsp_6_Abnormal_exit_(SOC_<_25%)" 7 "BMS_BookHeatStsRsp_7_Heating_end" 8 "BMS_BookHeatStsRsp_8_Reserved";
VAL_ 791 BMS_CoolingLevel 0 "BMS_CoolingLevel_0_NoRequest" 1 "BMS_CoolingLevel_1_Level0" 2 "BMS_CoolingLevel_2_Level1" 3 "BMS_CoolingLevel_3_Level2" 4 "BMS_CoolingLevel_4_Level3" 5 "BMS_CoolingLevel_5_Level4" 6 "BMS_CoolingLevel_6_Level5" 7 "BMS_CoolingLevel_7_Reserved";
VAL_ 791 BMS_HeatingLevel 0 "BMS_HeatingLevel_0_NoRequest" 1 "BMS_HeatingLevel_1_Level0" 2 "BMS_HeatingLevel_2_Level1" 3 "BMS_HeatingLevel_3_Level2" 4 "BMS_HeatingLevel_4_Level3" 5 "BMS_HeatingLevel_5_Level4" 6 "BMS_HeatingLevel_6_Level5" 7 "BMS_HeatingLevel_7_Reserved";
VAL_ 791 BMS_HeatngActuPwr 255 "BMS_HeatngActuPwr_255_Invalid";
VAL_ 791 BMS_HeatReq 0 "BMS_HeatReq_0_NoRequest" 1 "BMS_HeatReq_1_ChargeFisrt" 2 "BMS_HeatReq_2_HeatFisrt" 3 "BMS_HeatReq_3_Reserved";
VAL_ 791 BMS_NavChrgThermStFb 0 "BMS_NavChrgThermStFb_0_Default_State" 1 "BMS_NavChrgThermStFb_1_Navigation_Heating" 2 "BMS_NavChrgThermStFb_2_Navigation_Cooling" 3 "BMS_NavChrgThermStFb_3_Navigation_Thermal_Completed" 4 "BMS_NavChrgThermStFb_4_BMS_Reject" 5 "BMS_NavChrgThermStFb_5_WaterCycle" 6 "BMS_NavChrgThermStFb_6_Reserved" 7 "BMS_NavChrgThermStFb_7_Invalid";
VAL_ 791 BMS_PasCoolAllwd 0 "BMS_PasCoolAllwd_0_OFF" 1 "BMS_PasCoolAllwd_1_ON" 2 "BMS_PasCoolAllwd_2_Reserved";
VAL_ 791 BMS_PasHeatAllwd 0 "BMS_PasHeatAllwd_0_OFF" 1 "BMS_PasHeatAllwd_1_ON" 2 "BMS_PasHeatAllwd_2_Reserved";
VAL_ 791 BMS_RemThermTiEstimn 254 "BMS_RemThermTiEstimn_254_Initial_Value" 255 "BMS_RemThermTiEstimn_255_Invalid";
VAL_ 791 BMS_ThermalRequest 0 "BMS_ThermalRequest_0_NoRequest" 1 "BMS_ThermalRequest_1_waterCycle" 2 "BMS_ThermalRequest_2_Cool" 3 "BMS_ThermalRequest_3_Heat" 4 "BMS_ThermalRequest_4_Reserved";
VAL_ 791 BMS_ThermalScene 0 "BMS_ThermalScene_0_NoRequest" 1 "BMS_ThermalScene_1_Driving" 2 "BMS_ThermalScene_2_DrvNvgChrg" 3 "BMS_ThermalScene_3_ACChrg" 4 "BMS_ThermalScene_4_DCChrg" 5 "BMS_ThermalScene_5_ACChrgBefore" 6 "BMS_ThermalScene_6_DCChrgBefore" 7 "BMS_ThermalScene_7_LinkOnThermForDrv" 8 "BMS_ThermalScene_8_BattThermForDrv" 9 "BMS_ThermalScene_9_FullChrgStoreHeat" 10 "BMS_ThermalScene_10_LVOn" 11 "BMS_ThermalScene_11_Default" 12 "BMS_ThermalScene_12_RestEvrGenerate" 13 "BMS_ThermalScene_13_Reserved";
VAL_ 791 BMS_ThermUsgAllwd 0 "BMS_ThermUsgAllwd_0_OFF" 1 "BMS_ThermUsgAllwd_1_ON" 2 "BMS_ThermUsgAllwd_2_Reserved";
VAL_ 791 BMS_TrgtFlowRate 510 "BMS_TrgtFlowRate_510_Initial_Value" 511 "BMS_TrgtFlowRate_511_Invalid";
VAL_ 791 BMS_TrgtInletTemp 254 "BMS_TrgtInletTemp_254_Initial_Value" 255 "BMS_TrgtInletTemp_255_Invalid";
VAL_ 1422 BMS_BattTraceCodLen 255 "BMS_BattTraceCodLen_255_Invalid";
VAL_ 1422 BMS_BattTraceCodN1 48 "BMS_BattTraceCodN1_48_0" 49 "BMS_BattTraceCodN1_49_1" 50 "BMS_BattTraceCodN1_50_2" 51 "BMS_BattTraceCodN1_51_3" 52 "BMS_BattTraceCodN1_52_4" 53 "BMS_BattTraceCodN1_53_5" 54 "BMS_BattTraceCodN1_54_6" 55 "BMS_BattTraceCodN1_55_7" 56 "BMS_BattTraceCodN1_56_8" 57 "BMS_BattTraceCodN1_57_9" 65 "BMS_BattTraceCodN1_65_A" 66 "BMS_BattTraceCodN1_66_B" 67 "BMS_BattTraceCodN1_67_C" 68 "BMS_BattTraceCodN1_68_D" 69 "BMS_BattTraceCodN1_69_E" 70 "BMS_BattTraceCodN1_70_F" 71 "BMS_BattTraceCodN1_71_G" 72 "BMS_BattTraceCodN1_72_H" 73 "BMS_BattTraceCodN1_73_I" 74 "BMS_BattTraceCodN1_74_J" 75 "BMS_BattTraceCodN1_75_K" 76 "BMS_BattTraceCodN1_76_L" 77 "BMS_BattTraceCodN1_77_M" 78 "BMS_BattTraceCodN1_78_N" 79 "BMS_BattTraceCodN1_79_O" 80 "BMS_BattTraceCodN1_80_P" 81 "BMS_BattTraceCodN1_81_Q" 82 "BMS_BattTraceCodN1_82_R" 83 "BMS_BattTraceCodN1_83_S" 84 "BMS_BattTraceCodN1_84_T" 85 "BMS_BattTraceCodN1_85_U" 86 "BMS_BattTraceCodN1_86_V" 87 "BMS_BattTraceCodN1_87_W" 88 "BMS_BattTraceCodN1_88_X" 89 "BMS_BattTraceCodN1_89_Y" 90 "BMS_BattTraceCodN1_90_Z";
VAL_ 1422 BMS_BattTraceCodN10 48 "BMS_BattTraceCodN10_48_0" 49 "BMS_BattTraceCodN10_49_1" 50 "BMS_BattTraceCodN10_50_2" 51 "BMS_BattTraceCodN10_51_3" 52 "BMS_BattTraceCodN10_52_4" 53 "BMS_BattTraceCodN10_53_5" 54 "BMS_BattTraceCodN10_54_6" 55 "BMS_BattTraceCodN10_55_7" 56 "BMS_BattTraceCodN10_56_8" 57 "BMS_BattTraceCodN10_57_9" 65 "BMS_BattTraceCodN10_65_A" 66 "BMS_BattTraceCodN10_66_B" 67 "BMS_BattTraceCodN10_67_C" 68 "BMS_BattTraceCodN10_68_D" 69 "BMS_BattTraceCodN10_69_E" 70 "BMS_BattTraceCodN10_70_F" 71 "BMS_BattTraceCodN10_71_G" 72 "BMS_BattTraceCodN10_72_H" 73 "BMS_BattTraceCodN10_73_I" 74 "BMS_BattTraceCodN10_74_J" 75 "BMS_BattTraceCodN10_75_K" 76 "BMS_BattTraceCodN10_76_L" 77 "BMS_BattTraceCodN10_77_M" 78 "BMS_BattTraceCodN10_78_N" 79 "BMS_BattTraceCodN10_79_O" 80 "BMS_BattTraceCodN10_80_P" 81 "BMS_BattTraceCodN10_81_Q" 82 "BMS_BattTraceCodN10_82_R" 83 "BMS_BattTraceCodN10_83_S" 84 "BMS_BattTraceCodN10_84_T" 85 "BMS_BattTraceCodN10_85_U" 86 "BMS_BattTraceCodN10_86_V" 87 "BMS_BattTraceCodN10_87_W" 88 "BMS_BattTraceCodN10_88_X" 89 "BMS_BattTraceCodN10_89_Y" 90 "BMS_BattTraceCodN10_90_Z";
VAL_ 1422 BMS_BattTraceCodN11 48 "BMS_BattTraceCodN11_48_0" 49 "BMS_BattTraceCodN11_49_1" 50 "BMS_BattTraceCodN11_50_2" 51 "BMS_BattTraceCodN11_51_3" 52 "BMS_BattTraceCodN11_52_4" 53 "BMS_BattTraceCodN11_53_5" 54 "BMS_BattTraceCodN11_54_6" 55 "BMS_BattTraceCodN11_55_7" 56 "BMS_BattTraceCodN11_56_8" 57 "BMS_BattTraceCodN11_57_9" 65 "BMS_BattTraceCodN11_65_A" 66 "BMS_BattTraceCodN11_66_B" 67 "BMS_BattTraceCodN11_67_C" 68 "BMS_BattTraceCodN11_68_D" 69 "BMS_BattTraceCodN11_69_E" 70 "BMS_BattTraceCodN11_70_F" 71 "BMS_BattTraceCodN11_71_G" 72 "BMS_BattTraceCodN11_72_H" 73 "BMS_BattTraceCodN11_73_I" 74 "BMS_BattTraceCodN11_74_J" 75 "BMS_BattTraceCodN11_75_K" 76 "BMS_BattTraceCodN11_76_L" 77 "BMS_BattTraceCodN11_77_M" 78 "BMS_BattTraceCodN11_78_N" 79 "BMS_BattTraceCodN11_79_O" 80 "BMS_BattTraceCodN11_80_P" 81 "BMS_BattTraceCodN11_81_Q" 82 "BMS_BattTraceCodN11_82_R" 83 "BMS_BattTraceCodN11_83_S" 84 "BMS_BattTraceCodN11_84_T" 85 "BMS_BattTraceCodN11_85_U" 86 "BMS_BattTraceCodN11_86_V" 87 "BMS_BattTraceCodN11_87_W" 88 "BMS_BattTraceCodN11_88_X" 89 "BMS_BattTraceCodN11_89_Y" 90 "BMS_BattTraceCodN11_90_Z";
VAL_ 1422 BMS_BattTraceCodN12 48 "BMS_BattTraceCodN12_48_0" 49 "BMS_BattTraceCodN12_49_1" 50 "BMS_BattTraceCodN12_50_2" 51 "BMS_BattTraceCodN12_51_3" 52 "BMS_BattTraceCodN12_52_4" 53 "BMS_BattTraceCodN12_53_5" 54 "BMS_BattTraceCodN12_54_6" 55 "BMS_BattTraceCodN12_55_7" 56 "BMS_BattTraceCodN12_56_8" 57 "BMS_BattTraceCodN12_57_9" 65 "BMS_BattTraceCodN12_65_A" 66 "BMS_BattTraceCodN12_66_B" 67 "BMS_BattTraceCodN12_67_C" 68 "BMS_BattTraceCodN12_68_D" 69 "BMS_BattTraceCodN12_69_E" 70 "BMS_BattTraceCodN12_70_F" 71 "BMS_BattTraceCodN12_71_G" 72 "BMS_BattTraceCodN12_72_H" 73 "BMS_BattTraceCodN12_73_I" 74 "BMS_BattTraceCodN12_74_J" 75 "BMS_BattTraceCodN12_75_K" 76 "BMS_BattTraceCodN12_76_L" 77 "BMS_BattTraceCodN12_77_M" 78 "BMS_BattTraceCodN12_78_N" 79 "BMS_BattTraceCodN12_79_O" 80 "BMS_BattTraceCodN12_80_P" 81 "BMS_BattTraceCodN12_81_Q" 82 "BMS_BattTraceCodN12_82_R" 83 "BMS_BattTraceCodN12_83_S" 84 "BMS_BattTraceCodN12_84_T" 85 "BMS_BattTraceCodN12_85_U" 86 "BMS_BattTraceCodN12_86_V" 87 "BMS_BattTraceCodN12_87_W" 88 "BMS_BattTraceCodN12_88_X" 89 "BMS_BattTraceCodN12_89_Y" 90 "BMS_BattTraceCodN12_90_Z";
VAL_ 1422 BMS_BattTraceCodN13 48 "BMS_BattTraceCodN13_48_0" 49 "BMS_BattTraceCodN13_49_1" 50 "BMS_BattTraceCodN13_50_2" 51 "BMS_BattTraceCodN13_51_3" 52 "BMS_BattTraceCodN13_52_4" 53 "BMS_BattTraceCodN13_53_5" 54 "BMS_BattTraceCodN13_54_6" 55 "BMS_BattTraceCodN13_55_7" 56 "BMS_BattTraceCodN13_56_8" 57 "BMS_BattTraceCodN13_57_9" 65 "BMS_BattTraceCodN13_65_A" 66 "BMS_BattTraceCodN13_66_B" 67 "BMS_BattTraceCodN13_67_C" 68 "BMS_BattTraceCodN13_68_D" 69 "BMS_BattTraceCodN13_69_E" 70 "BMS_BattTraceCodN13_70_F" 71 "BMS_BattTraceCodN13_71_G" 72 "BMS_BattTraceCodN13_72_H" 73 "BMS_BattTraceCodN13_73_I" 74 "BMS_BattTraceCodN13_74_J" 75 "BMS_BattTraceCodN13_75_K" 76 "BMS_BattTraceCodN13_76_L" 77 "BMS_BattTraceCodN13_77_M" 78 "BMS_BattTraceCodN13_78_N" 79 "BMS_BattTraceCodN13_79_O" 80 "BMS_BattTraceCodN13_80_P" 81 "BMS_BattTraceCodN13_81_Q" 82 "BMS_BattTraceCodN13_82_R" 83 "BMS_BattTraceCodN13_83_S" 84 "BMS_BattTraceCodN13_84_T" 85 "BMS_BattTraceCodN13_85_U" 86 "BMS_BattTraceCodN13_86_V" 87 "BMS_BattTraceCodN13_87_W" 88 "BMS_BattTraceCodN13_88_X" 89 "BMS_BattTraceCodN13_89_Y" 90 "BMS_BattTraceCodN13_90_Z";
VAL_ 1422 BMS_BattTraceCodN14 48 "BMS_BattTraceCodN14_48_0" 49 "BMS_BattTraceCodN14_49_1" 50 "BMS_BattTraceCodN14_50_2" 51 "BMS_BattTraceCodN14_51_3" 52 "BMS_BattTraceCodN14_52_4" 53 "BMS_BattTraceCodN14_53_5" 54 "BMS_BattTraceCodN14_54_6" 55 "BMS_BattTraceCodN14_55_7" 56 "BMS_BattTraceCodN14_56_8" 57 "BMS_BattTraceCodN14_57_9" 65 "BMS_BattTraceCodN14_65_A" 66 "BMS_BattTraceCodN14_66_B" 67 "BMS_BattTraceCodN14_67_C" 68 "BMS_BattTraceCodN14_68_D" 69 "BMS_BattTraceCodN14_69_E" 70 "BMS_BattTraceCodN14_70_F" 71 "BMS_BattTraceCodN14_71_G" 72 "BMS_BattTraceCodN14_72_H" 73 "BMS_BattTraceCodN14_73_I" 74 "BMS_BattTraceCodN14_74_J" 75 "BMS_BattTraceCodN14_75_K" 76 "BMS_BattTraceCodN14_76_L" 77 "BMS_BattTraceCodN14_77_M" 78 "BMS_BattTraceCodN14_78_N" 79 "BMS_BattTraceCodN14_79_O" 80 "BMS_BattTraceCodN14_80_P" 81 "BMS_BattTraceCodN14_81_Q" 82 "BMS_BattTraceCodN14_82_R" 83 "BMS_BattTraceCodN14_83_S" 84 "BMS_BattTraceCodN14_84_T" 85 "BMS_BattTraceCodN14_85_U" 86 "BMS_BattTraceCodN14_86_V" 87 "BMS_BattTraceCodN14_87_W" 88 "BMS_BattTraceCodN14_88_X" 89 "BMS_BattTraceCodN14_89_Y" 90 "BMS_BattTraceCodN14_90_Z";
VAL_ 1422 BMS_BattTraceCodN15 48 "BMS_BattTraceCodN15_48_0" 49 "BMS_BattTraceCodN15_49_1" 50 "BMS_BattTraceCodN15_50_2" 51 "BMS_BattTraceCodN15_51_3" 52 "BMS_BattTraceCodN15_52_4" 53 "BMS_BattTraceCodN15_53_5" 54 "BMS_BattTraceCodN15_54_6" 55 "BMS_BattTraceCodN15_55_7" 56 "BMS_BattTraceCodN15_56_8" 57 "BMS_BattTraceCodN15_57_9" 65 "BMS_BattTraceCodN15_65_A" 66 "BMS_BattTraceCodN15_66_B" 67 "BMS_BattTraceCodN15_67_C" 68 "BMS_BattTraceCodN15_68_D" 69 "BMS_BattTraceCodN15_69_E" 70 "BMS_BattTraceCodN15_70_F" 71 "BMS_BattTraceCodN15_71_G" 72 "BMS_BattTraceCodN15_72_H" 73 "BMS_BattTraceCodN15_73_I" 74 "BMS_BattTraceCodN15_74_J" 75 "BMS_BattTraceCodN15_75_K" 76 "BMS_BattTraceCodN15_76_L" 77 "BMS_BattTraceCodN15_77_M" 78 "BMS_BattTraceCodN15_78_N" 79 "BMS_BattTraceCodN15_79_O" 80 "BMS_BattTraceCodN15_80_P" 81 "BMS_BattTraceCodN15_81_Q" 82 "BMS_BattTraceCodN15_82_R" 83 "BMS_BattTraceCodN15_83_S" 84 "BMS_BattTraceCodN15_84_T" 85 "BMS_BattTraceCodN15_85_U" 86 "BMS_BattTraceCodN15_86_V" 87 "BMS_BattTraceCodN15_87_W" 88 "BMS_BattTraceCodN15_88_X" 89 "BMS_BattTraceCodN15_89_Y" 90 "BMS_BattTraceCodN15_90_Z";
VAL_ 1422 BMS_BattTraceCodN16 48 "BMS_BattTraceCodN16_48_0" 49 "BMS_BattTraceCodN16_49_1" 50 "BMS_BattTraceCodN16_50_2" 51 "BMS_BattTraceCodN16_51_3" 52 "BMS_BattTraceCodN16_52_4" 53 "BMS_BattTraceCodN16_53_5" 54 "BMS_BattTraceCodN16_54_6" 55 "BMS_BattTraceCodN16_55_7" 56 "BMS_BattTraceCodN16_56_8" 57 "BMS_BattTraceCodN16_57_9" 65 "BMS_BattTraceCodN16_65_A" 66 "BMS_BattTraceCodN16_66_B" 67 "BMS_BattTraceCodN16_67_C" 68 "BMS_BattTraceCodN16_68_D" 69 "BMS_BattTraceCodN16_69_E" 70 "BMS_BattTraceCodN16_70_F" 71 "BMS_BattTraceCodN16_71_G" 72 "BMS_BattTraceCodN16_72_H" 73 "BMS_BattTraceCodN16_73_I" 74 "BMS_BattTraceCodN16_74_J" 75 "BMS_BattTraceCodN16_75_K" 76 "BMS_BattTraceCodN16_76_L" 77 "BMS_BattTraceCodN16_77_M" 78 "BMS_BattTraceCodN16_78_N" 79 "BMS_BattTraceCodN16_79_O" 80 "BMS_BattTraceCodN16_80_P" 81 "BMS_BattTraceCodN16_81_Q" 82 "BMS_BattTraceCodN16_82_R" 83 "BMS_BattTraceCodN16_83_S" 84 "BMS_BattTraceCodN16_84_T" 85 "BMS_BattTraceCodN16_85_U" 86 "BMS_BattTraceCodN16_86_V" 87 "BMS_BattTraceCodN16_87_W" 88 "BMS_BattTraceCodN16_88_X" 89 "BMS_BattTraceCodN16_89_Y" 90 "BMS_BattTraceCodN16_90_Z";
VAL_ 1422 BMS_BattTraceCodN17 48 "BMS_BattTraceCodN17_48_0" 49 "BMS_BattTraceCodN17_49_1" 50 "BMS_BattTraceCodN17_50_2" 51 "BMS_BattTraceCodN17_51_3" 52 "BMS_BattTraceCodN17_52_4" 53 "BMS_BattTraceCodN17_53_5" 54 "BMS_BattTraceCodN17_54_6" 55 "BMS_BattTraceCodN17_55_7" 56 "BMS_BattTraceCodN17_56_8" 57 "BMS_BattTraceCodN17_57_9" 65 "BMS_BattTraceCodN17_65_A" 66 "BMS_BattTraceCodN17_66_B" 67 "BMS_BattTraceCodN17_67_C" 68 "BMS_BattTraceCodN17_68_D" 69 "BMS_BattTraceCodN17_69_E" 70 "BMS_BattTraceCodN17_70_F" 71 "BMS_BattTraceCodN17_71_G" 72 "BMS_BattTraceCodN17_72_H" 73 "BMS_BattTraceCodN17_73_I" 74 "BMS_BattTraceCodN17_74_J" 75 "BMS_BattTraceCodN17_75_K" 76 "BMS_BattTraceCodN17_76_L" 77 "BMS_BattTraceCodN17_77_M" 78 "BMS_BattTraceCodN17_78_N" 79 "BMS_BattTraceCodN17_79_O" 80 "BMS_BattTraceCodN17_80_P" 81 "BMS_BattTraceCodN17_81_Q" 82 "BMS_BattTraceCodN17_82_R" 83 "BMS_BattTraceCodN17_83_S" 84 "BMS_BattTraceCodN17_84_T" 85 "BMS_BattTraceCodN17_85_U" 86 "BMS_BattTraceCodN17_86_V" 87 "BMS_BattTraceCodN17_87_W" 88 "BMS_BattTraceCodN17_88_X" 89 "BMS_BattTraceCodN17_89_Y" 90 "BMS_BattTraceCodN17_90_Z";
VAL_ 1422 BMS_BattTraceCodN18 48 "BMS_BattTraceCodN18_48_0" 49 "BMS_BattTraceCodN18_49_1" 50 "BMS_BattTraceCodN18_50_2" 51 "BMS_BattTraceCodN18_51_3" 52 "BMS_BattTraceCodN18_52_4" 53 "BMS_BattTraceCodN18_53_5" 54 "BMS_BattTraceCodN18_54_6" 55 "BMS_BattTraceCodN18_55_7" 56 "BMS_BattTraceCodN18_56_8" 57 "BMS_BattTraceCodN18_57_9" 65 "BMS_BattTraceCodN18_65_A" 66 "BMS_BattTraceCodN18_66_B" 67 "BMS_BattTraceCodN18_67_C" 68 "BMS_BattTraceCodN18_68_D" 69 "BMS_BattTraceCodN18_69_E" 70 "BMS_BattTraceCodN18_70_F" 71 "BMS_BattTraceCodN18_71_G" 72 "BMS_BattTraceCodN18_72_H" 73 "BMS_BattTraceCodN18_73_I" 74 "BMS_BattTraceCodN18_74_J" 75 "BMS_BattTraceCodN18_75_K" 76 "BMS_BattTraceCodN18_76_L" 77 "BMS_BattTraceCodN18_77_M" 78 "BMS_BattTraceCodN18_78_N" 79 "BMS_BattTraceCodN18_79_O" 80 "BMS_BattTraceCodN18_80_P" 81 "BMS_BattTraceCodN18_81_Q" 82 "BMS_BattTraceCodN18_82_R" 83 "BMS_BattTraceCodN18_83_S" 84 "BMS_BattTraceCodN18_84_T" 85 "BMS_BattTraceCodN18_85_U" 86 "BMS_BattTraceCodN18_86_V" 87 "BMS_BattTraceCodN18_87_W" 88 "BMS_BattTraceCodN18_88_X" 89 "BMS_BattTraceCodN18_89_Y" 90 "BMS_BattTraceCodN18_90_Z";
VAL_ 1422 BMS_BattTraceCodN19 48 "BMS_BattTraceCodN19_48_0" 49 "BMS_BattTraceCodN19_49_1" 50 "BMS_BattTraceCodN19_50_2" 51 "BMS_BattTraceCodN19_51_3" 52 "BMS_BattTraceCodN19_52_4" 53 "BMS_BattTraceCodN19_53_5" 54 "BMS_BattTraceCodN19_54_6" 55 "BMS_BattTraceCodN19_55_7" 56 "BMS_BattTraceCodN19_56_8" 57 "BMS_BattTraceCodN19_57_9" 65 "BMS_BattTraceCodN19_65_A" 66 "BMS_BattTraceCodN19_66_B" 67 "BMS_BattTraceCodN19_67_C" 68 "BMS_BattTraceCodN19_68_D" 69 "BMS_BattTraceCodN19_69_E" 70 "BMS_BattTraceCodN19_70_F" 71 "BMS_BattTraceCodN19_71_G" 72 "BMS_BattTraceCodN19_72_H" 73 "BMS_BattTraceCodN19_73_I" 74 "BMS_BattTraceCodN19_74_J" 75 "BMS_BattTraceCodN19_75_K" 76 "BMS_BattTraceCodN19_76_L" 77 "BMS_BattTraceCodN19_77_M" 78 "BMS_BattTraceCodN19_78_N" 79 "BMS_BattTraceCodN19_79_O" 80 "BMS_BattTraceCodN19_80_P" 81 "BMS_BattTraceCodN19_81_Q" 82 "BMS_BattTraceCodN19_82_R" 83 "BMS_BattTraceCodN19_83_S" 84 "BMS_BattTraceCodN19_84_T" 85 "BMS_BattTraceCodN19_85_U" 86 "BMS_BattTraceCodN19_86_V" 87 "BMS_BattTraceCodN19_87_W" 88 "BMS_BattTraceCodN19_88_X" 89 "BMS_BattTraceCodN19_89_Y" 90 "BMS_BattTraceCodN19_90_Z";
VAL_ 1422 BMS_BattTraceCodN2 48 "BMS_BattTraceCodN2_48_0" 49 "BMS_BattTraceCodN2_49_1" 50 "BMS_BattTraceCodN2_50_2" 51 "BMS_BattTraceCodN2_51_3" 52 "BMS_BattTraceCodN2_52_4" 53 "BMS_BattTraceCodN2_53_5" 54 "BMS_BattTraceCodN2_54_6" 55 "BMS_BattTraceCodN2_55_7" 56 "BMS_BattTraceCodN2_56_8" 57 "BMS_BattTraceCodN2_57_9" 65 "BMS_BattTraceCodN2_65_A" 66 "BMS_BattTraceCodN2_66_B" 67 "BMS_BattTraceCodN2_67_C" 68 "BMS_BattTraceCodN2_68_D" 69 "BMS_BattTraceCodN2_69_E" 70 "BMS_BattTraceCodN2_70_F" 71 "BMS_BattTraceCodN2_71_G" 72 "BMS_BattTraceCodN2_72_H" 73 "BMS_BattTraceCodN2_73_I" 74 "BMS_BattTraceCodN2_74_J" 75 "BMS_BattTraceCodN2_75_K" 76 "BMS_BattTraceCodN2_76_L" 77 "BMS_BattTraceCodN2_77_M" 78 "BMS_BattTraceCodN2_78_N" 79 "BMS_BattTraceCodN2_79_O" 80 "BMS_BattTraceCodN2_80_P" 81 "BMS_BattTraceCodN2_81_Q" 82 "BMS_BattTraceCodN2_82_R" 83 "BMS_BattTraceCodN2_83_S" 84 "BMS_BattTraceCodN2_84_T" 85 "BMS_BattTraceCodN2_85_U" 86 "BMS_BattTraceCodN2_86_V" 87 "BMS_BattTraceCodN2_87_W" 88 "BMS_BattTraceCodN2_88_X" 89 "BMS_BattTraceCodN2_89_Y" 90 "BMS_BattTraceCodN2_90_Z";
VAL_ 1422 BMS_BattTraceCodN20 48 "BMS_BattTraceCodN20_48_0" 49 "BMS_BattTraceCodN20_49_1" 50 "BMS_BattTraceCodN20_50_2" 51 "BMS_BattTraceCodN20_51_3" 52 "BMS_BattTraceCodN20_52_4" 53 "BMS_BattTraceCodN20_53_5" 54 "BMS_BattTraceCodN20_54_6" 55 "BMS_BattTraceCodN20_55_7" 56 "BMS_BattTraceCodN20_56_8" 57 "BMS_BattTraceCodN20_57_9" 65 "BMS_BattTraceCodN20_65_A" 66 "BMS_BattTraceCodN20_66_B" 67 "BMS_BattTraceCodN20_67_C" 68 "BMS_BattTraceCodN20_68_D" 69 "BMS_BattTraceCodN20_69_E" 70 "BMS_BattTraceCodN20_70_F" 71 "BMS_BattTraceCodN20_71_G" 72 "BMS_BattTraceCodN20_72_H" 73 "BMS_BattTraceCodN20_73_I" 74 "BMS_BattTraceCodN20_74_J" 75 "BMS_BattTraceCodN20_75_K" 76 "BMS_BattTraceCodN20_76_L" 77 "BMS_BattTraceCodN20_77_M" 78 "BMS_BattTraceCodN20_78_N" 79 "BMS_BattTraceCodN20_79_O" 80 "BMS_BattTraceCodN20_80_P" 81 "BMS_BattTraceCodN20_81_Q" 82 "BMS_BattTraceCodN20_82_R" 83 "BMS_BattTraceCodN20_83_S" 84 "BMS_BattTraceCodN20_84_T" 85 "BMS_BattTraceCodN20_85_U" 86 "BMS_BattTraceCodN20_86_V" 87 "BMS_BattTraceCodN20_87_W" 88 "BMS_BattTraceCodN20_88_X" 89 "BMS_BattTraceCodN20_89_Y" 90 "BMS_BattTraceCodN20_90_Z";
VAL_ 1422 BMS_BattTraceCodN21 48 "BMS_BattTraceCodN21_48_0" 49 "BMS_BattTraceCodN21_49_1" 50 "BMS_BattTraceCodN21_50_2" 51 "BMS_BattTraceCodN21_51_3" 52 "BMS_BattTraceCodN21_52_4" 53 "BMS_BattTraceCodN21_53_5" 54 "BMS_BattTraceCodN21_54_6" 55 "BMS_BattTraceCodN21_55_7" 56 "BMS_BattTraceCodN21_56_8" 57 "BMS_BattTraceCodN21_57_9" 65 "BMS_BattTraceCodN21_65_A" 66 "BMS_BattTraceCodN21_66_B" 67 "BMS_BattTraceCodN21_67_C" 68 "BMS_BattTraceCodN21_68_D" 69 "BMS_BattTraceCodN21_69_E" 70 "BMS_BattTraceCodN21_70_F" 71 "BMS_BattTraceCodN21_71_G" 72 "BMS_BattTraceCodN21_72_H" 73 "BMS_BattTraceCodN21_73_I" 74 "BMS_BattTraceCodN21_74_J" 75 "BMS_BattTraceCodN21_75_K" 76 "BMS_BattTraceCodN21_76_L" 77 "BMS_BattTraceCodN21_77_M" 78 "BMS_BattTraceCodN21_78_N" 79 "BMS_BattTraceCodN21_79_O" 80 "BMS_BattTraceCodN21_80_P" 81 "BMS_BattTraceCodN21_81_Q" 82 "BMS_BattTraceCodN21_82_R" 83 "BMS_BattTraceCodN21_83_S" 84 "BMS_BattTraceCodN21_84_T" 85 "BMS_BattTraceCodN21_85_U" 86 "BMS_BattTraceCodN21_86_V" 87 "BMS_BattTraceCodN21_87_W" 88 "BMS_BattTraceCodN21_88_X" 89 "BMS_BattTraceCodN21_89_Y" 90 "BMS_BattTraceCodN21_90_Z";
VAL_ 1422 BMS_BattTraceCodN22 48 "BMS_BattTraceCodN22_48_0" 49 "BMS_BattTraceCodN22_49_1" 50 "BMS_BattTraceCodN22_50_2" 51 "BMS_BattTraceCodN22_51_3" 52 "BMS_BattTraceCodN22_52_4" 53 "BMS_BattTraceCodN22_53_5" 54 "BMS_BattTraceCodN22_54_6" 55 "BMS_BattTraceCodN22_55_7" 56 "BMS_BattTraceCodN22_56_8" 57 "BMS_BattTraceCodN22_57_9" 65 "BMS_BattTraceCodN22_65_A" 66 "BMS_BattTraceCodN22_66_B" 67 "BMS_BattTraceCodN22_67_C" 68 "BMS_BattTraceCodN22_68_D" 69 "BMS_BattTraceCodN22_69_E" 70 "BMS_BattTraceCodN22_70_F" 71 "BMS_BattTraceCodN22_71_G" 72 "BMS_BattTraceCodN22_72_H" 73 "BMS_BattTraceCodN22_73_I" 74 "BMS_BattTraceCodN22_74_J" 75 "BMS_BattTraceCodN22_75_K" 76 "BMS_BattTraceCodN22_76_L" 77 "BMS_BattTraceCodN22_77_M" 78 "BMS_BattTraceCodN22_78_N" 79 "BMS_BattTraceCodN22_79_O" 80 "BMS_BattTraceCodN22_80_P" 81 "BMS_BattTraceCodN22_81_Q" 82 "BMS_BattTraceCodN22_82_R" 83 "BMS_BattTraceCodN22_83_S" 84 "BMS_BattTraceCodN22_84_T" 85 "BMS_BattTraceCodN22_85_U" 86 "BMS_BattTraceCodN22_86_V" 87 "BMS_BattTraceCodN22_87_W" 88 "BMS_BattTraceCodN22_88_X" 89 "BMS_BattTraceCodN22_89_Y" 90 "BMS_BattTraceCodN22_90_Z";
VAL_ 1422 BMS_BattTraceCodN23 48 "BMS_BattTraceCodN23_48_0" 49 "BMS_BattTraceCodN23_49_1" 50 "BMS_BattTraceCodN23_50_2" 51 "BMS_BattTraceCodN23_51_3" 52 "BMS_BattTraceCodN23_52_4" 53 "BMS_BattTraceCodN23_53_5" 54 "BMS_BattTraceCodN23_54_6" 55 "BMS_BattTraceCodN23_55_7" 56 "BMS_BattTraceCodN23_56_8" 57 "BMS_BattTraceCodN23_57_9" 65 "BMS_BattTraceCodN23_65_A" 66 "BMS_BattTraceCodN23_66_B" 67 "BMS_BattTraceCodN23_67_C" 68 "BMS_BattTraceCodN23_68_D" 69 "BMS_BattTraceCodN23_69_E" 70 "BMS_BattTraceCodN23_70_F" 71 "BMS_BattTraceCodN23_71_G" 72 "BMS_BattTraceCodN23_72_H" 73 "BMS_BattTraceCodN23_73_I" 74 "BMS_BattTraceCodN23_74_J" 75 "BMS_BattTraceCodN23_75_K" 76 "BMS_BattTraceCodN23_76_L" 77 "BMS_BattTraceCodN23_77_M" 78 "BMS_BattTraceCodN23_78_N" 79 "BMS_BattTraceCodN23_79_O" 80 "BMS_BattTraceCodN23_80_P" 81 "BMS_BattTraceCodN23_81_Q" 82 "BMS_BattTraceCodN23_82_R" 83 "BMS_BattTraceCodN23_83_S" 84 "BMS_BattTraceCodN23_84_T" 85 "BMS_BattTraceCodN23_85_U" 86 "BMS_BattTraceCodN23_86_V" 87 "BMS_BattTraceCodN23_87_W" 88 "BMS_BattTraceCodN23_88_X" 89 "BMS_BattTraceCodN23_89_Y" 90 "BMS_BattTraceCodN23_90_Z";
VAL_ 1422 BMS_BattTraceCodN24 48 "BMS_BattTraceCodN24_48_0" 49 "BMS_BattTraceCodN24_49_1" 50 "BMS_BattTraceCodN24_50_2" 51 "BMS_BattTraceCodN24_51_3" 52 "BMS_BattTraceCodN24_52_4" 53 "BMS_BattTraceCodN24_53_5" 54 "BMS_BattTraceCodN24_54_6" 55 "BMS_BattTraceCodN24_55_7" 56 "BMS_BattTraceCodN24_56_8" 57 "BMS_BattTraceCodN24_57_9" 65 "BMS_BattTraceCodN24_65_A" 66 "BMS_BattTraceCodN24_66_B" 67 "BMS_BattTraceCodN24_67_C" 68 "BMS_BattTraceCodN24_68_D" 69 "BMS_BattTraceCodN24_69_E" 70 "BMS_BattTraceCodN24_70_F" 71 "BMS_BattTraceCodN24_71_G" 72 "BMS_BattTraceCodN24_72_H" 73 "BMS_BattTraceCodN24_73_I" 74 "BMS_BattTraceCodN24_74_J" 75 "BMS_BattTraceCodN24_75_K" 76 "BMS_BattTraceCodN24_76_L" 77 "BMS_BattTraceCodN24_77_M" 78 "BMS_BattTraceCodN24_78_N" 79 "BMS_BattTraceCodN24_79_O" 80 "BMS_BattTraceCodN24_80_P" 81 "BMS_BattTraceCodN24_81_Q" 82 "BMS_BattTraceCodN24_82_R" 83 "BMS_BattTraceCodN24_83_S" 84 "BMS_BattTraceCodN24_84_T" 85 "BMS_BattTraceCodN24_85_U" 86 "BMS_BattTraceCodN24_86_V" 87 "BMS_BattTraceCodN24_87_W" 88 "BMS_BattTraceCodN24_88_X" 89 "BMS_BattTraceCodN24_89_Y" 90 "BMS_BattTraceCodN24_90_Z";
VAL_ 1422 BMS_BattTraceCodN3 48 "BMS_BattTraceCodN3_48_0" 49 "BMS_BattTraceCodN3_49_1" 50 "BMS_BattTraceCodN3_50_2" 51 "BMS_BattTraceCodN3_51_3" 52 "BMS_BattTraceCodN3_52_4" 53 "BMS_BattTraceCodN3_53_5" 54 "BMS_BattTraceCodN3_54_6" 55 "BMS_BattTraceCodN3_55_7" 56 "BMS_BattTraceCodN3_56_8" 57 "BMS_BattTraceCodN3_57_9" 65 "BMS_BattTraceCodN3_65_A" 66 "BMS_BattTraceCodN3_66_B" 67 "BMS_BattTraceCodN3_67_C" 68 "BMS_BattTraceCodN3_68_D" 69 "BMS_BattTraceCodN3_69_E" 70 "BMS_BattTraceCodN3_70_F" 71 "BMS_BattTraceCodN3_71_G" 72 "BMS_BattTraceCodN3_72_H" 73 "BMS_BattTraceCodN3_73_I" 74 "BMS_BattTraceCodN3_74_J" 75 "BMS_BattTraceCodN3_75_K" 76 "BMS_BattTraceCodN3_76_L" 77 "BMS_BattTraceCodN3_77_M" 78 "BMS_BattTraceCodN3_78_N" 79 "BMS_BattTraceCodN3_79_O" 80 "BMS_BattTraceCodN3_80_P" 81 "BMS_BattTraceCodN3_81_Q" 82 "BMS_BattTraceCodN3_82_R" 83 "BMS_BattTraceCodN3_83_S" 84 "BMS_BattTraceCodN3_84_T" 85 "BMS_BattTraceCodN3_85_U" 86 "BMS_BattTraceCodN3_86_V" 87 "BMS_BattTraceCodN3_87_W" 88 "BMS_BattTraceCodN3_88_X" 89 "BMS_BattTraceCodN3_89_Y" 90 "BMS_BattTraceCodN3_90_Z";
VAL_ 1422 BMS_BattTraceCodN4 48 "BMS_BattTraceCodN4_48_0" 49 "BMS_BattTraceCodN4_49_1" 50 "BMS_BattTraceCodN4_50_2" 51 "BMS_BattTraceCodN4_51_3" 52 "BMS_BattTraceCodN4_52_4" 53 "BMS_BattTraceCodN4_53_5" 54 "BMS_BattTraceCodN4_54_6" 55 "BMS_BattTraceCodN4_55_7" 56 "BMS_BattTraceCodN4_56_8" 57 "BMS_BattTraceCodN4_57_9" 65 "BMS_BattTraceCodN4_65_A" 66 "BMS_BattTraceCodN4_66_B" 67 "BMS_BattTraceCodN4_67_C" 68 "BMS_BattTraceCodN4_68_D" 69 "BMS_BattTraceCodN4_69_E" 70 "BMS_BattTraceCodN4_70_F" 71 "BMS_BattTraceCodN4_71_G" 72 "BMS_BattTraceCodN4_72_H" 73 "BMS_BattTraceCodN4_73_I" 74 "BMS_BattTraceCodN4_74_J" 75 "BMS_BattTraceCodN4_75_K" 76 "BMS_BattTraceCodN4_76_L" 77 "BMS_BattTraceCodN4_77_M" 78 "BMS_BattTraceCodN4_78_N" 79 "BMS_BattTraceCodN4_79_O" 80 "BMS_BattTraceCodN4_80_P" 81 "BMS_BattTraceCodN4_81_Q" 82 "BMS_BattTraceCodN4_82_R" 83 "BMS_BattTraceCodN4_83_S" 84 "BMS_BattTraceCodN4_84_T" 85 "BMS_BattTraceCodN4_85_U" 86 "BMS_BattTraceCodN4_86_V" 87 "BMS_BattTraceCodN4_87_W" 88 "BMS_BattTraceCodN4_88_X" 89 "BMS_BattTraceCodN4_89_Y" 90 "BMS_BattTraceCodN4_90_Z";
VAL_ 1422 BMS_BattTraceCodN5 48 "BMS_BattTraceCodN5_48_0" 49 "BMS_BattTraceCodN5_49_1" 50 "BMS_BattTraceCodN5_50_2" 51 "BMS_BattTraceCodN5_51_3" 52 "BMS_BattTraceCodN5_52_4" 53 "BMS_BattTraceCodN5_53_5" 54 "BMS_BattTraceCodN5_54_6" 55 "BMS_BattTraceCodN5_55_7" 56 "BMS_BattTraceCodN5_56_8" 57 "BMS_BattTraceCodN5_57_9" 65 "BMS_BattTraceCodN5_65_A" 66 "BMS_BattTraceCodN5_66_B" 67 "BMS_BattTraceCodN5_67_C" 68 "BMS_BattTraceCodN5_68_D" 69 "BMS_BattTraceCodN5_69_E" 70 "BMS_BattTraceCodN5_70_F" 71 "BMS_BattTraceCodN5_71_G" 72 "BMS_BattTraceCodN5_72_H" 73 "BMS_BattTraceCodN5_73_I" 74 "BMS_BattTraceCodN5_74_J" 75 "BMS_BattTraceCodN5_75_K" 76 "BMS_BattTraceCodN5_76_L" 77 "BMS_BattTraceCodN5_77_M" 78 "BMS_BattTraceCodN5_78_N" 79 "BMS_BattTraceCodN5_79_O" 80 "BMS_BattTraceCodN5_80_P" 81 "BMS_BattTraceCodN5_81_Q" 82 "BMS_BattTraceCodN5_82_R" 83 "BMS_BattTraceCodN5_83_S" 84 "BMS_BattTraceCodN5_84_T" 85 "BMS_BattTraceCodN5_85_U" 86 "BMS_BattTraceCodN5_86_V" 87 "BMS_BattTraceCodN5_87_W" 88 "BMS_BattTraceCodN5_88_X" 89 "BMS_BattTraceCodN5_89_Y" 90 "BMS_BattTraceCodN5_90_Z";
VAL_ 1422 BMS_BattTraceCodN6 48 "BMS_BattTraceCodN6_48_0" 49 "BMS_BattTraceCodN6_49_1" 50 "BMS_BattTraceCodN6_50_2" 51 "BMS_BattTraceCodN6_51_3" 52 "BMS_BattTraceCodN6_52_4" 53 "BMS_BattTraceCodN6_53_5" 54 "BMS_BattTraceCodN6_54_6" 55 "BMS_BattTraceCodN6_55_7" 56 "BMS_BattTraceCodN6_56_8" 57 "BMS_BattTraceCodN6_57_9" 65 "BMS_BattTraceCodN6_65_A" 66 "BMS_BattTraceCodN6_66_B" 67 "BMS_BattTraceCodN6_67_C" 68 "BMS_BattTraceCodN6_68_D" 69 "BMS_BattTraceCodN6_69_E" 70 "BMS_BattTraceCodN6_70_F" 71 "BMS_BattTraceCodN6_71_G" 72 "BMS_BattTraceCodN6_72_H" 73 "BMS_BattTraceCodN6_73_I" 74 "BMS_BattTraceCodN6_74_J" 75 "BMS_BattTraceCodN6_75_K" 76 "BMS_BattTraceCodN6_76_L" 77 "BMS_BattTraceCodN6_77_M" 78 "BMS_BattTraceCodN6_78_N" 79 "BMS_BattTraceCodN6_79_O" 80 "BMS_BattTraceCodN6_80_P" 81 "BMS_BattTraceCodN6_81_Q" 82 "BMS_BattTraceCodN6_82_R" 83 "BMS_BattTraceCodN6_83_S" 84 "BMS_BattTraceCodN6_84_T" 85 "BMS_BattTraceCodN6_85_U" 86 "BMS_BattTraceCodN6_86_V" 87 "BMS_BattTraceCodN6_87_W" 88 "BMS_BattTraceCodN6_88_X" 89 "BMS_BattTraceCodN6_89_Y" 90 "BMS_BattTraceCodN6_90_Z";
VAL_ 1422 BMS_BattTraceCodN7 48 "BMS_BattTraceCodN7_48_0" 49 "BMS_BattTraceCodN7_49_1" 50 "BMS_BattTraceCodN7_50_2" 51 "BMS_BattTraceCodN7_51_3" 52 "BMS_BattTraceCodN7_52_4" 53 "BMS_BattTraceCodN7_53_5" 54 "BMS_BattTraceCodN7_54_6" 55 "BMS_BattTraceCodN7_55_7" 56 "BMS_BattTraceCodN7_56_8" 57 "BMS_BattTraceCodN7_57_9" 65 "BMS_BattTraceCodN7_65_A" 66 "BMS_BattTraceCodN7_66_B" 67 "BMS_BattTraceCodN7_67_C" 68 "BMS_BattTraceCodN7_68_D" 69 "BMS_BattTraceCodN7_69_E" 70 "BMS_BattTraceCodN7_70_F" 71 "BMS_BattTraceCodN7_71_G" 72 "BMS_BattTraceCodN7_72_H" 73 "BMS_BattTraceCodN7_73_I" 74 "BMS_BattTraceCodN7_74_J" 75 "BMS_BattTraceCodN7_75_K" 76 "BMS_BattTraceCodN7_76_L" 77 "BMS_BattTraceCodN7_77_M" 78 "BMS_BattTraceCodN7_78_N" 79 "BMS_BattTraceCodN7_79_O" 80 "BMS_BattTraceCodN7_80_P" 81 "BMS_BattTraceCodN7_81_Q" 82 "BMS_BattTraceCodN7_82_R" 83 "BMS_BattTraceCodN7_83_S" 84 "BMS_BattTraceCodN7_84_T" 85 "BMS_BattTraceCodN7_85_U" 86 "BMS_BattTraceCodN7_86_V" 87 "BMS_BattTraceCodN7_87_W" 88 "BMS_BattTraceCodN7_88_X" 89 "BMS_BattTraceCodN7_89_Y" 90 "BMS_BattTraceCodN7_90_Z";
VAL_ 1422 BMS_BattTraceCodN8 48 "BMS_BattTraceCodN8_48_0" 49 "BMS_BattTraceCodN8_49_1" 50 "BMS_BattTraceCodN8_50_2" 51 "BMS_BattTraceCodN8_51_3" 52 "BMS_BattTraceCodN8_52_4" 53 "BMS_BattTraceCodN8_53_5" 54 "BMS_BattTraceCodN8_54_6" 55 "BMS_BattTraceCodN8_55_7" 56 "BMS_BattTraceCodN8_56_8" 57 "BMS_BattTraceCodN8_57_9" 65 "BMS_BattTraceCodN8_65_A" 66 "BMS_BattTraceCodN8_66_B" 67 "BMS_BattTraceCodN8_67_C" 68 "BMS_BattTraceCodN8_68_D" 69 "BMS_BattTraceCodN8_69_E" 70 "BMS_BattTraceCodN8_70_F" 71 "BMS_BattTraceCodN8_71_G" 72 "BMS_BattTraceCodN8_72_H" 73 "BMS_BattTraceCodN8_73_I" 74 "BMS_BattTraceCodN8_74_J" 75 "BMS_BattTraceCodN8_75_K" 76 "BMS_BattTraceCodN8_76_L" 77 "BMS_BattTraceCodN8_77_M" 78 "BMS_BattTraceCodN8_78_N" 79 "BMS_BattTraceCodN8_79_O" 80 "BMS_BattTraceCodN8_80_P" 81 "BMS_BattTraceCodN8_81_Q" 82 "BMS_BattTraceCodN8_82_R" 83 "BMS_BattTraceCodN8_83_S" 84 "BMS_BattTraceCodN8_84_T" 85 "BMS_BattTraceCodN8_85_U" 86 "BMS_BattTraceCodN8_86_V" 87 "BMS_BattTraceCodN8_87_W" 88 "BMS_BattTraceCodN8_88_X" 89 "BMS_BattTraceCodN8_89_Y" 90 "BMS_BattTraceCodN8_90_Z";
VAL_ 1422 BMS_BattTraceCodN9 48 "BMS_BattTraceCodN9_48_0" 49 "BMS_BattTraceCodN9_49_1" 50 "BMS_BattTraceCodN9_50_2" 51 "BMS_BattTraceCodN9_51_3" 52 "BMS_BattTraceCodN9_52_4" 53 "BMS_BattTraceCodN9_53_5" 54 "BMS_BattTraceCodN9_54_6" 55 "BMS_BattTraceCodN9_55_7" 56 "BMS_BattTraceCodN9_56_8" 57 "BMS_BattTraceCodN9_57_9" 65 "BMS_BattTraceCodN9_65_A" 66 "BMS_BattTraceCodN9_66_B" 67 "BMS_BattTraceCodN9_67_C" 68 "BMS_BattTraceCodN9_68_D" 69 "BMS_BattTraceCodN9_69_E" 70 "BMS_BattTraceCodN9_70_F" 71 "BMS_BattTraceCodN9_71_G" 72 "BMS_BattTraceCodN9_72_H" 73 "BMS_BattTraceCodN9_73_I" 74 "BMS_BattTraceCodN9_74_J" 75 "BMS_BattTraceCodN9_75_K" 76 "BMS_BattTraceCodN9_76_L" 77 "BMS_BattTraceCodN9_77_M" 78 "BMS_BattTraceCodN9_78_N" 79 "BMS_BattTraceCodN9_79_O" 80 "BMS_BattTraceCodN9_80_P" 81 "BMS_BattTraceCodN9_81_Q" 82 "BMS_BattTraceCodN9_82_R" 83 "BMS_BattTraceCodN9_83_S" 84 "BMS_BattTraceCodN9_84_T" 85 "BMS_BattTraceCodN9_85_U" 86 "BMS_BattTraceCodN9_86_V" 87 "BMS_BattTraceCodN9_87_W" 88 "BMS_BattTraceCodN9_88_X" 89 "BMS_BattTraceCodN9_89_Y" 90 "BMS_BattTraceCodN9_90_Z";
